VERSION ""

NS_ :

BS_:

BU_: ACCL BGW DBPC DCFL DCFR DCRL DCRR DSM ECPM FBCM FFL FLDC FRDC HLL HLR HUD IHUB LGL PBPC PSM RCLL RCLR RLDC RLSM RRDC RRSM TOOL RCCL RCCR SCAM DEMFL DEMFR DEMRL DEMRR DOSFL DOSFR DOSRL DOSRR

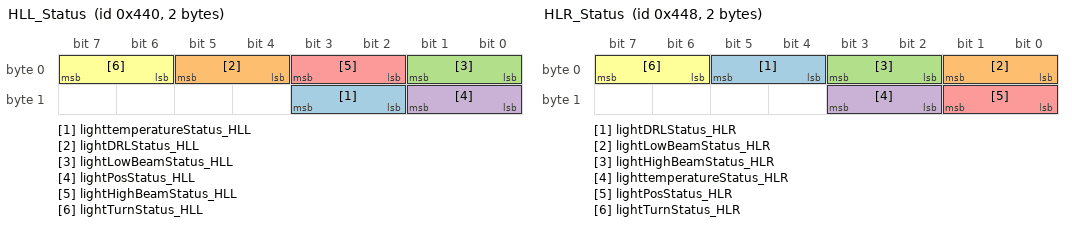
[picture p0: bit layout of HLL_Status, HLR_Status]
BO_ 1088 HLL_Status: 2 HLL
 SG_ lighttemperatureStatus_HLL : 11|2@0+ (1,0) [0|3] ""  FBCM
 SG_ lightDRLStatus_HLL : 5|2@0+ (1,0) [0|3] ""  HUD,BGW,FBCM
 SG_ lightLowBeamStatus_HLL : 1|2@0+ (1,0) [0|3] ""  IHUB,HUD,FBCM,BGW
 SG_ lightPosStatus_HLL : 9|2@0+ (1,0) [0|3] ""  HUD,FBCM,BGW
 SG_ lightHighBeamStatus_HLL : 3|2@0+ (1,0) [0|3] ""  IHUB,HUD,FBCM,BGW
 SG_ lightTurnStatus_HLL : 7|2@0+ (1,0) [0|3] ""  HUD,FBCM,BGW

BO_ 1096 HLR_Status: 2 HLR
 SG_ lightDRLStatus_HLR : 5|2@0+ (1,0) [0|3] ""  HUD,BGW,FBCM
 SG_ lightLowBeamStatus_HLR : 1|2@0+ (1,0) [0|3] ""  IHUB,HUD,FBCM,BGW
 SG_ lightHighBeamStatus_HLR : 3|2@0+ (1,0) [0|3] ""  IHUB,HUD,FBCM,BGW
 SG_ lighttemperatureStatus_HLR : 11|2@0+ (1,0) [0|3] ""  FBCM
 SG_ lightPosStatus_HLR : 9|2@0+ (1,0) [0|3] ""  HUD,FBCM,BGW
 SG_ lightTurnStatus_HLR : 7|2@0+ (1,0) [0|3] ""  HUD,FBCM,BGW

BO_ 680 DCRL_Status: 8 DCRL
 SG_ doorLockReq_DCRL : 55|2@0+ (1,0) [0|2] ""  BGW
 SG_ lockUnlockReq_RLLUS : 41|2@0+ (1,0) [0|2] ""  BGW
 SG_ doorSafeMode_DCRL : 53|2@0+ (1,0) [0|0] ""  FBCM,BGW
 SG_ doorLatchPawlOpen_DCRL : 48|2@0+ (1,0) [0|3] ""  TOOL
 SG_ doorLatchFault_DCRL : 23|2@0+ (1,0) [0|2] ""  BGW
 SG_ childLockButtonState_DCRL : 21|2@0+ (1,0) [0|2] ""  BGW,DCFL,DCFR,DCRL,DCRR
 SG_ doorIsUnlatched_DCRL : 31|2@0+ (1,0) [0|2] ""  HUD,FBCM,BGW,DCFR,DCRR,DCFL,IHUB
 SG_ doorExtSwitch_DCRL : 9|2@0+ (1,0) [0|2] ""  BGW
 SG_ doorMirrorState_DCRL : 7|3@0+ (1,0) [0|6] ""  ECPM,BGW
 SG_ doorState_DCRL : 13|4@0+ (1,0) [0|9] ""  ECPM,FBCM,BGW,DBPC
 SG_ mirrorHeaterState_DCRL : 15|2@0+ (1,0) [0|2] ""  ECPM,BGW
 SG_ sideRepeaterState_DCRL : 2|2@0+ (1,0) [0|2] ""  BGW
 SG_ doorDTCPresent_DCRL : 4|2@0+ (1,0) [0|2] ""  BGW
 SG_ windowStatusRl_DCRL : 19|3@0+ (1,0) [0|6] ""  BGW
 SG_ mirrorFoldFeedbackLeft_DCRL : 29|2@0+ (1,0) [0|2] ""  BGW
 SG_ mirrorDefrostGlassStatusLh_DCRL : 27|2@0+ (1,0) [0|2] ""  BGW
 SG_ mirrorStatusMovUpDownLeft_DCRL : 39|2@0+ (1,0) [0|2] ""  BGW
 SG_ mirrorStatusMovInOutLeft_DCRL : 37|2@0+ (1,0) [0|2] ""  BGW
 SG_ mirrorDefrostCamStatusLeft_DCRL : 35|2@0+ (1,0) [0|2] ""  BGW
 SG_ errorAMPRL_DCRL : 16|1@0+ (1,0) [0|1] ""  BGW
 SG_ errorALDRL_DCRL : 0|1@0+ (1,0) [0|1] ""  BGW
 SG_ doorAngle_DCRL : 47|6@0- (2,40) [-24|100] "degrees"  BGW
 SG_ doorAngleMax_DCRL : 62|7@0+ (1,0) [0|126] "degrees"  BGW
 SG_ wakeUpCause_DCRL : 51|3@0+ (1,0) [0|7] ""  TOOL

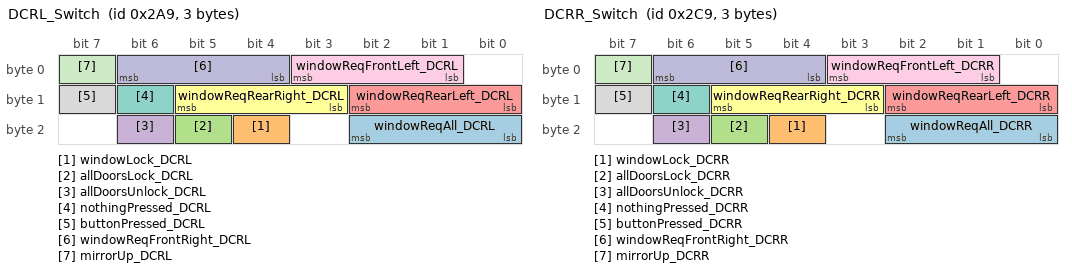
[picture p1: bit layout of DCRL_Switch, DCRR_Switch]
BO_ 681 DCRL_Switch: 3 DCRL
 SG_ windowReqAll_DCRL : 18|3@0+ (1,0) [0|6] ""  DCRR,DCRL,DCFR,DCFL,TOOL
 SG_ windowLock_DCRL : 20|1@0+ (1,0) [0|1] ""  DCRR,DCRL,DCFR,DCFL,TOOL
 SG_ allDoorsLock_DCRL : 21|1@0+ (1,0) [0|1] ""  DCRR,DCRL,DCFR,DCFL,TOOL
 SG_ allDoorsUnlock_DCRL : 22|1@0+ (1,0) [0|1] ""  DCRR,DCRL,DCFR,DCFL,TOOL
 SG_ windowReqRearLeft_DCRL : 10|3@0+ (1,0) [0|6] ""  DCFR,DCRR,DCFL,DCRL,BGW,TOOL
 SG_ windowReqRearRight_DCRL : 13|3@0+ (1,0) [0|6] ""  DCRL,DCFR,DCFL,DCRR,BGW,TOOL
 SG_ nothingPressed_DCRL : 14|1@0+ (1,0) [0|1] ""  DCFR,DCRL,DCRR,DCFL,TOOL
 SG_ buttonPressed_DCRL : 15|1@0+ (1,0) [0|1] ""  DCFR,DCRL,DCRR,DCFL,TOOL
 SG_ windowReqFrontLeft_DCRL : 3|3@0+ (1,0) [0|6] ""  DCFR,DCRL,DCRR,DCFL,BGW
 SG_ windowReqFrontRight_DCRL : 6|3@0+ (1,0) [0|6] ""  DCFR,DCRL,DCRR,DCFL,BGW,TOOL
 SG_ mirrorUp_DCRL : 7|1@0+ (1,0) [0|1] ""  DCRR,DCRL,DCFR,DCFL,TOOL

BO_ 712 DCRR_Status: 8 DCRR
 SG_ doorLockReq_DCRR : 55|2@0+ (1,0) [0|2] ""  BGW
 SG_ lockUnlockReq_RRLUS : 41|2@0+ (1,0) [0|2] ""  BGW
 SG_ doorSafeMode_DCRR : 53|2@0+ (1,0) [0|0] ""  FBCM,BGW
 SG_ doorLatchPawlOpen_DCRR : 48|2@0+ (1,0) [0|3] ""  TOOL
 SG_ doorLatchFault_DCRR : 23|2@0+ (1,0) [0|2] ""  BGW
 SG_ childLockButtonState_DCRR : 21|2@0+ (1,0) [0|2] ""  BGW,DCFL,DCFR,DCRL,DCRR
 SG_ doorIsUnlatched_DCRR : 31|2@0+ (1,0) [0|2] ""  HUD,FBCM,BGW,DCFR,DCFL,DCRL,IHUB
 SG_ doorExtSwitch_DCRR : 9|2@0+ (1,0) [0|2] ""  BGW
 SG_ doorMirrorState_DCRR : 7|3@0+ (1,0) [0|6] ""  ECPM,BGW
 SG_ doorState_DCRR : 13|4@0+ (1,0) [0|9] ""  ECPM,FBCM,BGW,DBPC
 SG_ mirrorHeaterState_DCRR : 15|2@0+ (1,0) [0|2] ""  ECPM,BGW
 SG_ sideRepeaterState_DCRR : 2|2@0+ (1,0) [0|2] ""  BGW
 SG_ doorDTCPresent_DCRR : 4|2@0+ (1,0) [0|2] ""  BGW
 SG_ windowStatusRr_DCRR : 19|3@0+ (1,0) [0|6] ""  BGW
 SG_ mirrorFoldFeedbackRight_DCRR : 29|2@0+ (1,0) [0|2] ""  BGW
 SG_ mirrorDefrostGlassStatusRh_DCRR : 27|2@0+ (1,0) [0|2] ""  BGW
 SG_ mirrorStatusMovUpDownRight_DCRR : 39|2@0+ (1,0) [0|2] ""  BGW
 SG_ mirrorStatusMovInOutRight_DCRR : 37|2@0+ (1,0) [0|2] ""  BGW
 SG_ mirrorDefrostCamStatusRight_DCRR : 35|2@0+ (1,0) [0|2] ""  BGW
 SG_ errorAMPRR_DCRR : 16|1@0+ (1,0) [0|1] ""  BGW
 SG_ errorALDRR_DCRR : 0|1@0+ (1,0) [0|1] ""  BGW
 SG_ doorAngle_DCRR : 47|6@0- (2,40) [-24|100] "degrees"  BGW
 SG_ doorAngleMax_DCRR : 62|7@0+ (1,0) [0|126] "degrees"  BGW
 SG_ wakeUpCause_DCRR : 51|3@0+ (1,0) [0|7] ""  TOOL

BO_ 713 DCRR_Switch: 3 DCRR
 SG_ windowReqAll_DCRR : 18|3@0+ (1,0) [0|6] ""  DCRR,DCRL,DCFR,DCFL,TOOL
 SG_ windowLock_DCRR : 20|1@0+ (1,0) [0|1] ""  DCRR,DCRL,DCFR,DCFL,TOOL
 SG_ allDoorsLock_DCRR : 21|1@0+ (1,0) [0|1] ""  DCRR,DCRL,DCFR,DCFL,TOOL
 SG_ allDoorsUnlock_DCRR : 22|1@0+ (1,0) [0|1] ""  DCRR,DCRL,DCFR,DCFL,TOOL
 SG_ windowReqRearLeft_DCRR : 10|3@0+ (1,0) [0|6] ""  DCFR,DCRR,DCFL,DCRL
 SG_ windowReqRearRight_DCRR : 13|3@0+ (1,0) [0|6] ""  DCRL,DCFR,DCFL,DCRR,BGW
 SG_ nothingPressed_DCRR : 14|1@0+ (1,0) [0|1] ""  DCFR,DCRL,DCRR,DCFL,TOOL
 SG_ buttonPressed_DCRR : 15|1@0+ (1,0) [0|1] ""  DCFR,DCRL,DCRR,DCFL,TOOL
 SG_ windowReqFrontLeft_DCRR : 3|3@0+ (1,0) [0|6] ""  DCFR,DCRL,DCRR,DCFL,BGW
 SG_ windowReqFrontRight_DCRR : 6|3@0+ (1,0) [0|6] ""  DCFR,DCRL,DCRR,DCFL,BGW,TOOL
 SG_ mirrorUp_DCRR : 7|1@0+ (1,0) [0|1] ""  DCRR,DCRL,DCFR,DCFL,TOOL

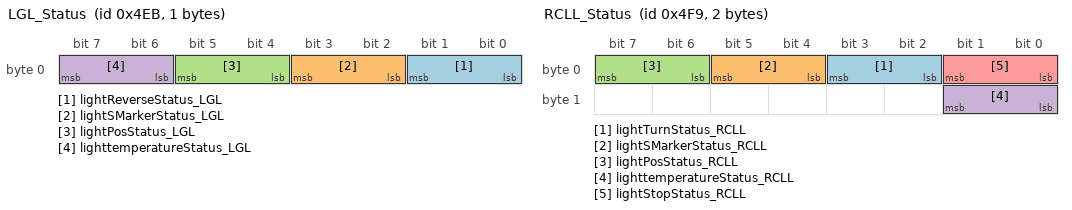
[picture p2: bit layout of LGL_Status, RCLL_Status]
BO_ 1259 LGL_Status: 1 LGL
 SG_ lightReverseStatus_LGL : 1|2@0+ (1,0) [0|3] ""  HUD,BGW,FBCM
 SG_ lightSMarkerStatus_LGL : 3|2@0+ (1,0) [0|3] ""  HUD,BGW,FBCM
 SG_ lightPosStatus_LGL : 5|2@0+ (1,0) [0|3] ""  HUD,BGW,FBCM
 SG_ lighttemperatureStatus_LGL : 7|2@0+ (1,0) [0|3] ""  HUD,BGW,FBCM

BO_ 1273 RCLL_Status: 2 RCLL
 SG_ lightTurnStatus_RCLL : 3|2@0+ (1,0) [0|3] ""  BGW,FBCM
 SG_ lightSMarkerStatus_RCLL : 5|2@0+ (1,0) [0|3] ""  HUD,BGW,FBCM
 SG_ lightPosStatus_RCLL : 7|2@0+ (1,0) [0|3] ""  HUD,BGW,FBCM
 SG_ lighttemperatureStatus_RCLL : 9|2@0+ (1,0) [0|3] ""  FBCM
 SG_ lightStopStatus_RCLL : 1|2@0+ (1,0) [0|2] ""  BGW,FBCM

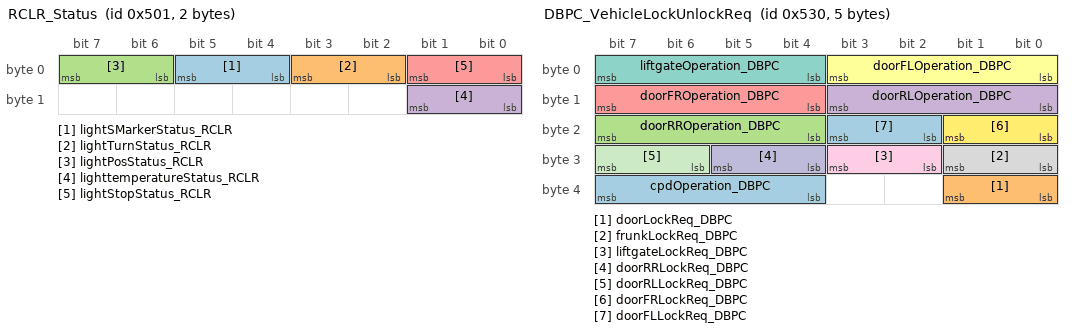
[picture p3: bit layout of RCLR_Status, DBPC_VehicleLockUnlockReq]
BO_ 1281 RCLR_Status: 2 RCLR
 SG_ lightSMarkerStatus_RCLR : 5|2@0+ (1,0) [0|3] ""  BGW
 SG_ lightTurnStatus_RCLR : 3|2@0+ (1,0) [0|3] ""  BGW,FBCM
 SG_ lightPosStatus_RCLR : 7|2@0+ (1,0) [0|3] ""  HUD,BGW,FBCM
 SG_ lighttemperatureStatus_RCLR : 9|2@0+ (1,0) [0|3] ""  FBCM
 SG_ lightStopStatus_RCLR : 1|2@0+ (1,0) [0|3] ""  BGW,FBCM

BO_ 1290 BGW_ClimateMassageCtrl: 8 BGW
 SG_ seatCushionMassageCmdRL_BGW : 34|2@0+ (1,0) [0|0] ""  RLSM
 SG_ seatCushionMassageCmdRR_BGW : 50|2@0+ (1,0) [0|0] ""  RRSM
 SG_ seatBackMassageCmdRR_BGW : 52|2@0+ (1,0) [0|0] ""  RRSM
 SG_ seatBackMassageCmdRL_BGW : 36|2@0+ (1,0) [0|0] ""  RLSM
 SG_ seatCushionMassageCmdFR_BGW : 18|2@0+ (1,0) [0|0] ""  PSM
 SG_ seatBackMassageCmdFR_BGW : 20|2@0+ (1,0) [0|0] ""  PSM
 SG_ seatCushionMassageCmdFL_BGW : 2|2@0+ (1,0) [0|0] ""  DSM
 SG_ seatBackMassageCmdFL_BGW : 4|2@0+ (1,0) [0|0] ""  DSM
 SG_ seatMassageTypeCmdRR_BGW : 63|3@0+ (1,0) [0|0] ""  RRSM
 SG_ seatMassageIntensityCmdRR_BGW : 60|3@0+ (1,0) [0|0] ""  RRSM
 SG_ seatHeatVentCmdRR_BGW : 55|3@0+ (1,0) [0|0] ""  RRSM
 SG_ seatMassageTypeCmdRL_BGW : 47|3@0+ (1,0) [0|0] ""  RLSM
 SG_ seatMassageIntensityCmdRL_BGW : 44|3@0+ (1,0) [0|0] ""  RLSM
 SG_ seatHeatVentCmdRL_BGW : 39|3@0+ (1,0) [0|0] ""  RLSM
 SG_ seatMassageTypeCmdFR_BGW : 31|3@0+ (1,0) [0|0] ""  PSM
 SG_ seatMassageIntensityCmdFR_BGW : 28|3@0+ (1,0) [0|0] ""  PSM
 SG_ seatHeatVentCmdFR_BGW : 23|3@0+ (1,0) [0|0] ""  PSM
 SG_ seatHeatVentCmdFL_BGW : 7|3@0+ (1,0) [0|0] ""  DSM
 SG_ seatMassageIntensityCmdFL_BGW : 12|3@0+ (1,0) [0|0] ""  DSM
 SG_ seatMassageTypeCmdFL_BGW : 15|3@0+ (1,0) [0|0] ""  DSM

BO_ 1298 ACCL_Status: 1 ACCL
 SG_ lightPosStatus_ACCL : 1|2@0+ (1,0) [0|3] ""  FBCM

BO_ 1328 DBPC_VehicleLockUnlockReq: 5 DBPC
 SG_ cpdOperation_DBPC : 39|4@0+ (1,0) [0|0] ""  FBCM,BGW
 SG_ doorLockReq_DBPC : 33|2@0+ (1,0) [0|2] ""  BGW
 SG_ doorRROperation_DBPC : 23|4@0+ (1,0) [0|14] ""  DCFL,DCFR,DCRR,DCRL,FBCM
 SG_ doorRLOperation_DBPC : 11|4@0+ (1,0) [0|14] ""  DCFL,DCFR,DCRR,DCRL,FBCM
 SG_ doorFROperation_DBPC : 15|4@0+ (1,0) [0|14] ""  DCFL,DCFR,DCRR,DCRL,FBCM
 SG_ doorFLOperation_DBPC : 3|4@0+ (1,0) [0|14] ""  DCFL,DCFR,DCRR,DCRL,FBCM
 SG_ liftgateOperation_DBPC : 7|4@0+ (1,0) [0|14] ""  BGW
 SG_ frunkLockReq_DBPC : 25|2@0+ (1,0) [0|2] ""  BGW
 SG_ liftgateLockReq_DBPC : 27|2@0+ (1,0) [0|2] ""  BGW
 SG_ doorRRLockReq_DBPC : 29|2@0+ (1,0) [0|2] ""  BGW
 SG_ doorRLLockReq_DBPC : 31|2@0+ (1,0) [0|2] ""  BGW
 SG_ doorFRLockReq_DBPC : 17|2@0+ (1,0) [0|2] ""  BGW
 SG_ doorFLLockReq_DBPC : 19|2@0+ (1,0) [0|2] ""  BGW

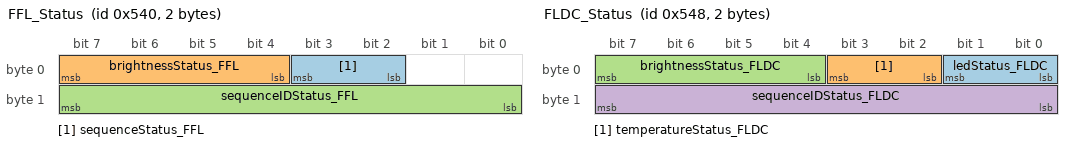
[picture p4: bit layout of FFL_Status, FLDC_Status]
BO_ 1344 FFL_Status: 2 FFL
 SG_ sequenceStatus_FFL : 3|2@0+ (1,0) [0|2] ""  BGW
 SG_ brightnessStatus_FFL : 7|4@0+ (0.07,0) [0|0.98] ""  BGW
 SG_ sequenceIDStatus_FFL : 15|8@0+ (1,0) [0|254] ""  BGW

BO_ 1352 FLDC_Status: 2 FLDC
 SG_ ledStatus_FLDC : 1|2@0+ (1,0) [0|0] ""  BGW
 SG_ temperatureStatus_FLDC : 3|2@0+ (1,0) [0|0] ""  BGW
 SG_ brightnessStatus_FLDC : 7|4@0+ (0.07,0) [0|0.98] ""  BGW
 SG_ sequenceIDStatus_FLDC : 15|8@0+ (1,0) [0|254] ""  BGW

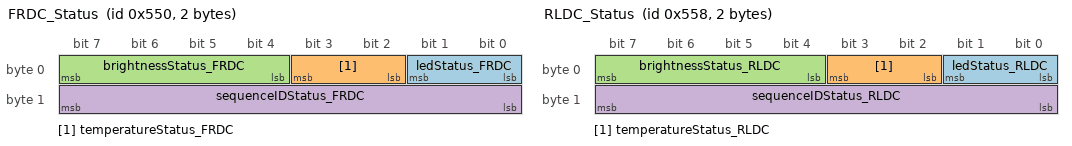
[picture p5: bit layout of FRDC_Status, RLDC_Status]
BO_ 1360 FRDC_Status: 2 FRDC
 SG_ ledStatus_FRDC : 1|2@0+ (1,0) [0|0] ""  BGW
 SG_ temperatureStatus_FRDC : 3|2@0+ (1,0) [0|0] ""  BGW
 SG_ brightnessStatus_FRDC : 7|4@0+ (0.07,0) [0|0.98] ""  BGW
 SG_ sequenceIDStatus_FRDC : 15|8@0+ (1,0) [0|254] ""  BGW

BO_ 1368 RLDC_Status: 2 RLDC
 SG_ ledStatus_RLDC : 1|2@0+ (1,0) [0|0] ""  BGW
 SG_ temperatureStatus_RLDC : 3|2@0+ (1,0) [0|0] ""  BGW
 SG_ brightnessStatus_RLDC : 7|4@0+ (0.07,0) [0|0.98] ""  BGW
 SG_ sequenceIDStatus_RLDC : 15|8@0+ (1,0) [0|254] ""  BGW

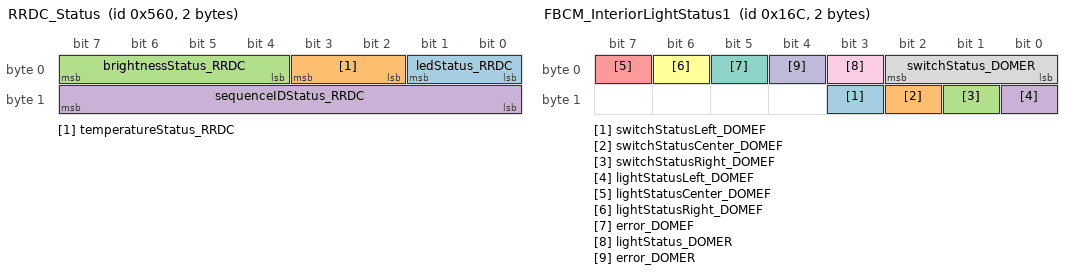
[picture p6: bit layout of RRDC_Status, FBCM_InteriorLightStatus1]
BO_ 1376 RRDC_Status: 2 RRDC
 SG_ ledStatus_RRDC : 1|2@0+ (1,0) [0|0] ""  BGW
 SG_ temperatureStatus_RRDC : 3|2@0+ (1,0) [0|0] ""  BGW
 SG_ brightnessStatus_RRDC : 7|4@0+ (0.07,0) [0|0.98] ""  BGW
 SG_ sequenceIDStatus_RRDC : 15|8@0+ (1,0) [0|254] ""  BGW

BO_ 364 FBCM_InteriorLightStatus1: 2 FBCM
 SG_ switchStatusLeft_DOMEF : 11|1@0+ (1,0) [0|1] ""  BGW
 SG_ switchStatusCenter_DOMEF : 10|1@0+ (1,0) [0|1] ""  BGW
 SG_ switchStatusRight_DOMEF : 9|1@0+ (1,0) [0|1] ""  BGW
 SG_ lightStatusLeft_DOMEF : 8|1@0+ (1,0) [0|1] ""  BGW
 SG_ lightStatusCenter_DOMEF : 7|1@0+ (1,0) [0|1] ""  BGW
 SG_ lightStatusRight_DOMEF : 6|1@0+ (1,0) [0|1] ""  BGW
 SG_ error_DOMEF : 5|1@0+ (1,0) [0|1] ""  BGW
 SG_ switchStatus_DOMER : 2|3@0+ (1,0) [0|6] ""  BGW
 SG_ lightStatus_DOMER : 3|1@0+ (1,0) [0|1] ""  BGW
 SG_ error_DOMER : 4|1@0+ (1,0) [0|1] ""  BGW

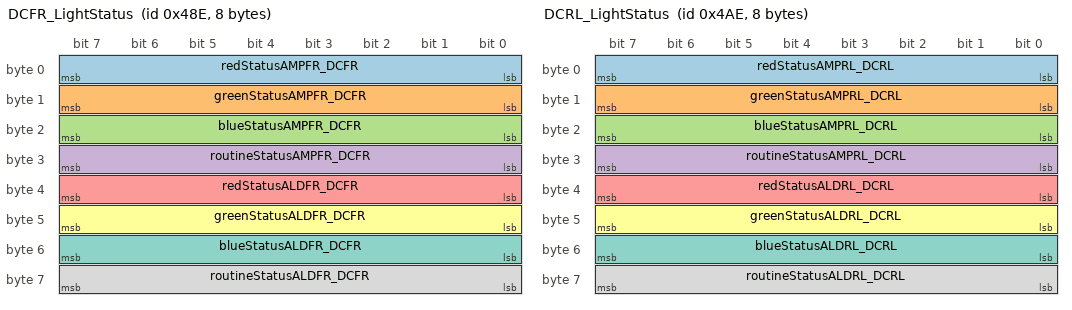
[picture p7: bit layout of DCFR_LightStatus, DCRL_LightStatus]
BO_ 1166 DCFR_LightStatus: 8 DCFR
 SG_ redStatusAMPFR_DCFR : 7|8@0+ (1,0) [0|254] ""  BGW
 SG_ greenStatusAMPFR_DCFR : 15|8@0+ (1,0) [0|254] ""  BGW
 SG_ blueStatusAMPFR_DCFR : 23|8@0+ (1,0) [0|254] ""  BGW
 SG_ routineStatusAMPFR_DCFR : 31|8@0+ (1,0) [0|254] ""  BGW
 SG_ redStatusALDFR_DCFR : 39|8@0+ (1,0) [0|254] ""  BGW
 SG_ greenStatusALDFR_DCFR : 47|8@0+ (1,0) [0|254] ""  BGW
 SG_ blueStatusALDFR_DCFR : 55|8@0+ (1,0) [0|254] ""  BGW
 SG_ routineStatusALDFR_DCFR : 63|8@0+ (1,0) [0|254] ""  BGW

BO_ 1198 DCRL_LightStatus: 8 DCRL
 SG_ redStatusAMPRL_DCRL : 7|8@0+ (1,0) [0|254] ""  BGW
 SG_ greenStatusAMPRL_DCRL : 15|8@0+ (1,0) [0|254] ""  BGW
 SG_ blueStatusAMPRL_DCRL : 23|8@0+ (1,0) [0|254] ""  BGW
 SG_ routineStatusAMPRL_DCRL : 31|8@0+ (1,0) [0|254] ""  BGW
 SG_ redStatusALDRL_DCRL : 39|8@0+ (1,0) [0|254] ""  BGW
 SG_ greenStatusALDRL_DCRL : 47|8@0+ (1,0) [0|254] ""  BGW
 SG_ blueStatusALDRL_DCRL : 55|8@0+ (1,0) [0|254] ""  BGW
 SG_ routineStatusALDRL_DCRL : 63|8@0+ (1,0) [0|254] ""  BGW

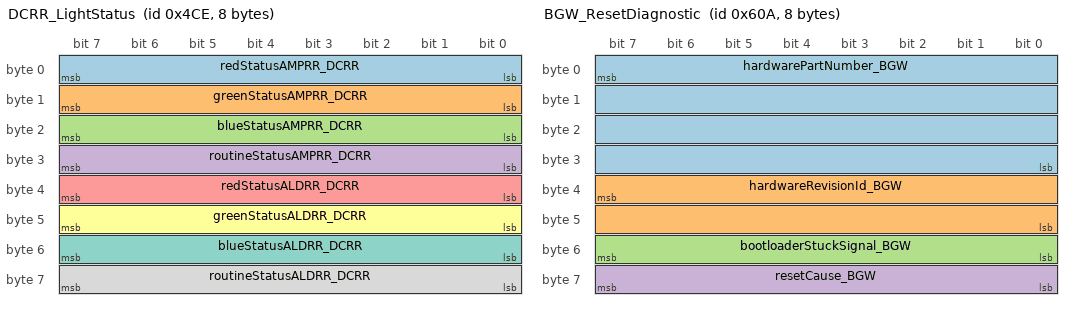
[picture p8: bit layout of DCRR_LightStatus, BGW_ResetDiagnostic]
BO_ 1230 DCRR_LightStatus: 8 DCRR
 SG_ redStatusAMPRR_DCRR : 7|8@0+ (1,0) [0|254] ""  BGW
 SG_ greenStatusAMPRR_DCRR : 15|8@0+ (1,0) [0|254] ""  BGW
 SG_ blueStatusAMPRR_DCRR : 23|8@0+ (1,0) [0|254] ""  BGW
 SG_ routineStatusAMPRR_DCRR : 31|8@0+ (1,0) [0|254] ""  BGW
 SG_ redStatusALDRR_DCRR : 39|8@0+ (1,0) [0|254] ""  BGW
 SG_ greenStatusALDRR_DCRR : 47|8@0+ (1,0) [0|254] ""  BGW
 SG_ blueStatusALDRR_DCRR : 55|8@0+ (1,0) [0|254] ""  BGW
 SG_ routineStatusALDRR_DCRR : 63|8@0+ (1,0) [0|254] ""  BGW

BO_ 1546 BGW_ResetDiagnostic: 8 BGW
 SG_ hardwarePartNumber_BGW : 7|32@0+ (1,0) [0|4294967294] ""  TOOL
 SG_ hardwareRevisionId_BGW : 39|16@0+ (1,0) [0|65534] ""  TOOL
 SG_ bootloaderStuckSignal_BGW : 55|8@0+ (1,0) [0|254] ""  TOOL
 SG_ resetCause_BGW : 63|8@0+ (1,0) [0|254] ""  TOOL

BO_ 1549 BGW_UDSRequest: 8 TOOL

BO_ 1550 BGW_UDSResponse: 8 BGW

BO_ 1551 BGW_Version: 8 BGW
 SG_ componentNum_BGW M : 7|8@0+ (1,0) [0|2] ""  TOOL
 SG_ idGitHashUpper_BGW m2 : 55|16@0+ (1,0) [0|65535] ""  TOOL
 SG_ idBuildMachine_BGW m2 : 47|8@0+ (1,0) [0|254] ""  TOOL
 SG_ versionSubMinor_BGW m2 : 39|8@0+ (1,0) [0|254] ""  TOOL
 SG_ versionReleaseCandidate_BGW m2 : 31|8@0+ (1,0) [0|254] ""  TOOL
 SG_ versionMinor_BGW m2 : 23|8@0+ (1,0) [0|254] ""  TOOL
 SG_ versionMajor_BGW m2 : 15|8@0+ (1,0) [0|254] ""  TOOL
 SG_ idBootGitHashUpper_BGW m0 : 55|16@0+ (1,0) [0|65535] ""  TOOL
 SG_ idBootBuildMachine_BGW m0 : 47|8@0+ (1,0) [0|254] ""  TOOL
 SG_ versionBootSubMinor_BGW m0 : 39|8@0+ (1,0) [0|254] ""  TOOL
 SG_ versionBootReleaseCandidate_BGW m0 : 31|8@0+ (1,0) [0|254] ""  TOOL
 SG_ versionBootMinor_BGW m0 : 23|8@0+ (1,0) [0|254] ""  TOOL
 SG_ versionBootMajor_BGW m0 : 15|8@0+ (1,0) [0|254] ""  TOOL
 SG_ versionCalSubMinor_BGW m1 : 39|8@0+ (1,0) [0|254] ""  TOOL
 SG_ versionCalReleaseCandidate_BGW m1 : 31|8@0+ (1,0) [0|254] ""  TOOL
 SG_ versionCalMinor_BGW m1 : 23|8@0+ (1,0) [0|254] ""  TOOL
 SG_ versionCalMajor_BGW m1 : 15|8@0+ (1,0) [0|254] ""  TOOL
 SG_ idCalGitHashUpper_BGW m1 : 55|16@0+ (1,0) [0|65534] ""  TOOL
 SG_ idCalBuildMachine_BGW m1 : 47|8@0+ (1,0) [0|254] ""  TOOL

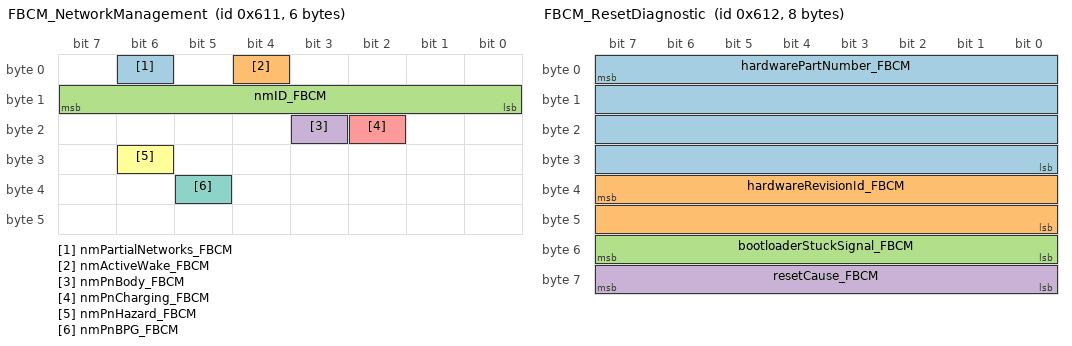
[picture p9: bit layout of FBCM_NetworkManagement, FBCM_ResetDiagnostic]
BO_ 1553 FBCM_NetworkManagement: 6 FBCM
 SG_ nmPartialNetworks_FBCM : 6|1@0+ (1,0) [0|1] ""  BGW,DCFL,DCFR,DCRL,DCRR
 SG_ nmActiveWake_FBCM : 4|1@0+ (1,0) [0|1] ""  BGW,DCFL,DCFR,DCRL,DCRR
 SG_ nmID_FBCM : 15|8@0+ (1,0) [0|31] ""  BGW,DCFL,DCFR,DCRL,DCRR
 SG_ nmPnBody_FBCM : 19|1@0+ (1,0) [0|1] ""  BGW,DCFL,DCFR,DCRL,DCRR
 SG_ nmPnCharging_FBCM : 18|1@0+ (1,0) [0|1] ""  BGW
 SG_ nmPnHazard_FBCM : 30|1@0+ (1,0) [0|1] ""  BGW,DCFL,DCFR
 SG_ nmPnBPG_FBCM : 37|1@0+ (1,0) [0|1] ""  BGW

BO_ 1554 FBCM_ResetDiagnostic: 8 FBCM
 SG_ hardwarePartNumber_FBCM : 7|32@0+ (1,0) [0|4294967294] ""  TOOL
 SG_ hardwareRevisionId_FBCM : 39|16@0+ (1,0) [0|65534] ""  TOOL
 SG_ bootloaderStuckSignal_FBCM : 55|8@0+ (1,0) [0|254] ""  TOOL
 SG_ resetCause_FBCM : 63|8@0+ (1,0) [0|254] ""  BGW,TOOL

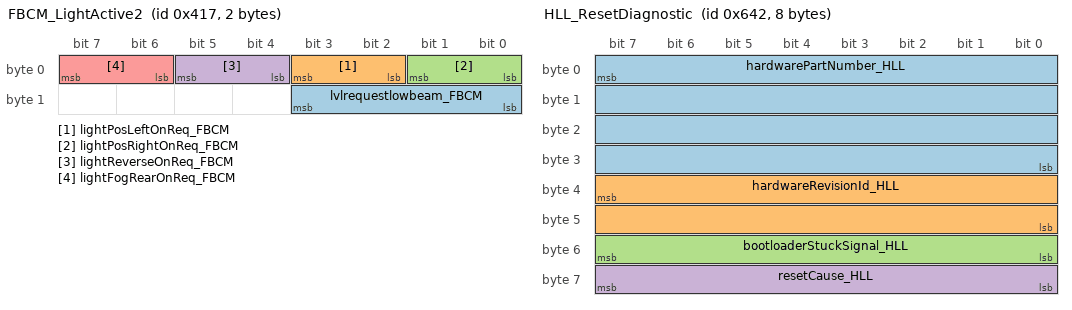
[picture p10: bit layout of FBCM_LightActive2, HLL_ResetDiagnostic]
BO_ 1047 FBCM_LightActive2: 2 FBCM
 SG_ lvlrequestlowbeam_FBCM : 11|4@0+ (1,0) [0|15] ""  HLR,HLL
 SG_ lightPosLeftOnReq_FBCM : 3|2@0+ (1,0) [0|2] ""  ACCL,RCCL,HLL,LGL
 SG_ lightPosRightOnReq_FBCM : 1|2@0+ (1,0) [0|2] ""  ACCL,RCCR,HLR,LGL
 SG_ lightReverseOnReq_FBCM : 5|2@0+ (1,0) [0|2] ""  BGW,IHUB,HUD,RCLL,RCLR
 SG_ lightFogRearOnReq_FBCM : 7|2@0+ (1,0) [0|2] ""  BGW,IHUB,HUD,RCLL,RCLR

BO_ 1557 FBCM_UDSRequest: 8 TOOL
 SG_ udsClientDataFBCM_TOOL : 7|64@0+ (1,0) [0|1.84467440737094E+019] ""  FBCM

BO_ 1558 FBCM_UDSResponse: 8 FBCM
 SG_ udsServerData_FBCM : 7|64@0+ (1,0) [0|1.84467440737094E+019] ""  TOOL

BO_ 1559 FBCM_Version: 8 FBCM
 SG_ versionCalSubMinor_FBCM m1 : 39|8@0+ (1,0) [0|254] ""  BGW,TOOL
 SG_ versionCalReleaseCandidate_FBCM m1 : 31|8@0+ (1,0) [0|254] ""  BGW,TOOL
 SG_ versionCalMinor_FBCM m1 : 23|8@0+ (1,0) [0|254] ""  BGW,TOOL
 SG_ versionCalMajor_FBCM m1 : 15|8@0+ (1,0) [0|254] ""  BGW,TOOL
 SG_ idCalGitHashUpper_FBCM m1 : 55|16@0+ (1,0) [0|65534] ""  BGW,TOOL
 SG_ idCalBuildMachine_FBCM m1 : 47|8@0+ (1,0) [0|254] ""  BGW,TOOL
 SG_ versionReleaseCandidate_FBCM m2 : 31|8@0+ (1,0) [0|254] ""  BGW,TOOL
 SG_ versionBootReleaseCandidate_FBCM m0 : 31|8@0+ (1,0) [0|254] ""  BGW,TOOL
 SG_ componentNum_FBCM M : 7|8@0+ (1,0) [0|254] ""  BGW,TOOL
 SG_ idGitHashUpper_FBCM m2 : 55|16@0+ (1,0) [0|65534] ""  BGW,TOOL
 SG_ idBootGitHashUpper_FBCM m0 : 55|16@0+ (1,0) [0|65534] ""  BGW,TOOL
 SG_ idBuildMachine_FBCM m2 : 47|8@0+ (1,0) [0|254] ""  BGW,TOOL
 SG_ versionSubMinor_FBCM m2 : 39|8@0+ (1,0) [0|254] ""  BGW,TOOL
 SG_ versionMinor_FBCM m2 : 23|8@0+ (1,0) [0|254] ""  BGW,TOOL
 SG_ versionMajor_FBCM m2 : 15|8@0+ (1,0) [0|254] ""  BGW,TOOL
 SG_ idBootBuildMachine_FBCM m0 : 47|8@0+ (1,0) [0|254] ""  BGW,TOOL
 SG_ versionBootSubMinor_FBCM m0 : 39|8@0+ (1,0) [0|254] ""  BGW,TOOL
 SG_ versionBootMinor_FBCM m0 : 23|8@0+ (1,0) [0|254] ""  BGW,TOOL
 SG_ versionBootMajor_FBCM m0 : 15|8@0+ (1,0) [0|254] ""  BGW,TOOL

BO_ 1602 HLL_ResetDiagnostic: 8 HLL
 SG_ hardwarePartNumber_HLL : 7|32@0+ (1,0) [0|4294967294] ""  TOOL
 SG_ hardwareRevisionId_HLL : 39|16@0+ (1,0) [0|65534] ""  TOOL
 SG_ bootloaderStuckSignal_HLL : 55|8@0+ (1,0) [0|254] ""  TOOL
 SG_ resetCause_HLL : 63|8@0+ (1,0) [0|254] ""  TOOL

BO_ 1605 HLL_UDSRequest: 8 TOOL
 SG_ udsClientDataHLL_TOOL : 7|64@0+ (1,0) [0|1.84467440737094E+019] ""  HLL

BO_ 1606 HLL_UDSResponse: 8 HLL
 SG_ udsServerData_HLL : 7|64@0+ (1,0) [0|1.84467440737094E+019] ""  TOOL

BO_ 1607 HLL_Version: 8 HLL
 SG_ versionReleaseCandidate_HLL m1 : 31|8@0+ (1,0) [0|254] ""  BGW,TOOL
 SG_ versionBootReleaseCandidate_HLL m0 : 31|8@0+ (1,0) [0|254] ""  BGW,TOOL
 SG_ componentNum_HLL M : 7|8@0+ (1,0) [0|254] ""  BGW,TOOL
 SG_ idGitHashUpper_HLL m1 : 55|16@0+ (1,0) [0|65534] ""  BGW,TOOL
 SG_ idBootGitHashUpper_HLL m0 : 55|16@0+ (1,0) [0|65534] ""  BGW,TOOL
 SG_ idBuildMachine_HLL m1 : 47|8@0+ (1,0) [0|254] ""  BGW,TOOL
 SG_ versionSubMinor_HLL m1 : 39|8@0+ (1,0) [0|254] ""  BGW,TOOL
 SG_ versionMinor_HLL m1 : 23|8@0+ (1,0) [0|254] ""  BGW,TOOL
 SG_ versionMajor_HLL m1 : 15|8@0+ (1,0) [0|254] ""  BGW,TOOL
 SG_ idBootBuildMachine_HLL m0 : 47|8@0+ (1,0) [0|254] ""  BGW,TOOL
 SG_ versionBootSubMinor_HLL m0 : 39|8@0+ (1,0) [0|254] ""  BGW,TOOL
 SG_ versionBootMinor_HLL m0 : 23|8@0+ (1,0) [0|254] ""  BGW,TOOL
 SG_ versionBootMajor_HLL m0 : 15|8@0+ (1,0) [0|254] ""  BGW,TOOL

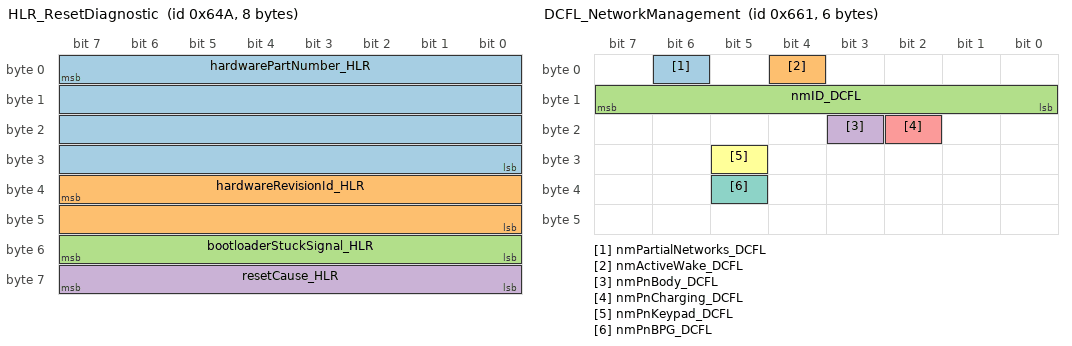
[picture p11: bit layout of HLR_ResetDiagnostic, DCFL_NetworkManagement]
BO_ 1610 HLR_ResetDiagnostic: 8 HLR
 SG_ hardwarePartNumber_HLR : 7|32@0+ (1,0) [0|4294967294] ""  TOOL
 SG_ hardwareRevisionId_HLR : 39|16@0+ (1,0) [0|65534] ""  TOOL
 SG_ bootloaderStuckSignal_HLR : 55|8@0+ (1,0) [0|254] ""  TOOL
 SG_ resetCause_HLR : 63|8@0+ (1,0) [0|254] ""  TOOL

BO_ 1613 HLR_UDSRequest: 8 TOOL
 SG_ udsClientDataHLR_TOOL : 7|64@0+ (1,0) [0|1.84467440737094E+019] ""  HLR

BO_ 1614 HLR_UDSResponse: 8 HLR
 SG_ udsServerData_HLR : 7|64@0+ (1,0) [0|1.84467440737094E+019] ""  TOOL

BO_ 1615 HLR_Version: 8 HLR
 SG_ versionReleaseCandidate_HLR m1 : 31|8@0+ (1,0) [0|254] ""  BGW,TOOL
 SG_ versionBootReleaseCandidate_HLR m0 : 31|8@0+ (1,0) [0|254] ""  BGW,TOOL
 SG_ componentNum_HLR M : 7|8@0+ (1,0) [0|254] ""  BGW,TOOL
 SG_ idGitHashUpper_HLR m1 : 55|16@0+ (1,0) [0|65534] ""  BGW,TOOL
 SG_ idBootGitHashUpper_HLR m0 : 55|16@0+ (1,0) [0|65534] ""  BGW,TOOL
 SG_ idBuildMachine_HLR m1 : 47|8@0+ (1,0) [0|254] ""  BGW,TOOL
 SG_ versionSubMinor_HLR m1 : 39|8@0+ (1,0) [0|254] ""  BGW,TOOL
 SG_ versionMinor_HLR m1 : 23|8@0+ (1,0) [0|254] ""  BGW,TOOL
 SG_ versionMajor_HLR m1 : 15|8@0+ (1,0) [0|254] ""  BGW,TOOL
 SG_ idBootBuildMachine_HLR m0 : 47|8@0+ (1,0) [0|254] ""  BGW,TOOL
 SG_ versionBootSubMinor_HLR m0 : 39|8@0+ (1,0) [0|254] ""  BGW,TOOL
 SG_ versionBootMinor_HLR m0 : 23|8@0+ (1,0) [0|254] ""  BGW,TOOL
 SG_ versionBootMajor_HLR m0 : 15|8@0+ (1,0) [0|254] ""  BGW,TOOL

BO_ 1633 DCFL_NetworkManagement: 6 DCFL
 SG_ nmPartialNetworks_DCFL : 6|1@0+ (1,0) [0|1] ""  BGW,DCFR,DCRL,DCRR,FBCM
 SG_ nmActiveWake_DCFL : 4|1@0+ (1,0) [0|1] ""  BGW,DCFR,DCRL,DCRR,FBCM
 SG_ nmID_DCFL : 15|8@0+ (1,0) [0|31] ""  BGW,DCFR,DCRL,DCRR,FBCM
 SG_ nmPnBody_DCFL : 19|1@0+ (1,0) [0|1] ""  BGW,DCFR,DCRL,DCRR,FBCM
 SG_ nmPnCharging_DCFL : 18|1@0+ (1,0) [0|1] ""  BGW
 SG_ nmPnKeypad_DCFL : 29|1@0+ (1,0) [0|1] ""  BGW
 SG_ nmPnBPG_DCFL : 37|1@0+ (1,0) [0|1] ""  BGW

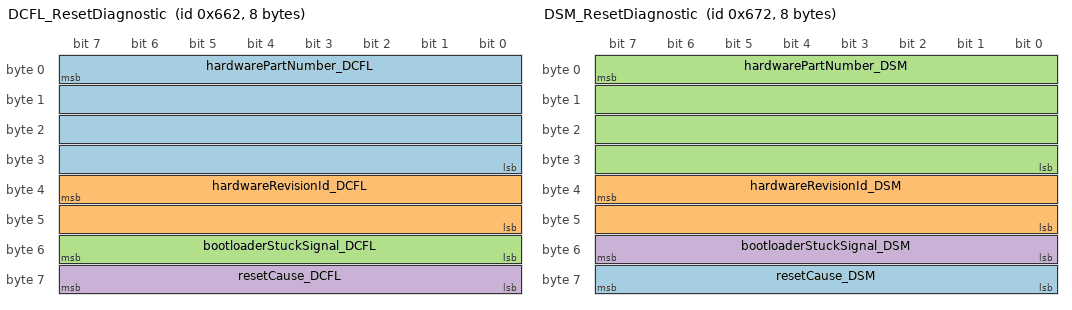
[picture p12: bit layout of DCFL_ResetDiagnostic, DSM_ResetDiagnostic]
BO_ 1634 DCFL_ResetDiagnostic: 8 DCFL
 SG_ hardwarePartNumber_DCFL : 7|32@0+ (1,0) [0|4294967294] ""  TOOL
 SG_ hardwareRevisionId_DCFL : 39|16@0+ (1,0) [0|65534] ""  TOOL
 SG_ bootloaderStuckSignal_DCFL : 55|8@0+ (1,0) [0|254] ""  TOOL
 SG_ resetCause_DCFL : 63|8@0+ (1,0) [0|254] ""  BGW,TOOL

BO_ 1637 DCFL_UDSRequest: 8 TOOL
 SG_ udsClientDataDcfl_TOOL : 7|64@0+ (1,0) [0|1.84467440737094E+019] ""  DCFL

BO_ 1638 DCFL_UDSResponse: 8 DCFL
 SG_ udsServerData_DCFL : 7|64@0+ (1,0) [0|1.84467440737094E+019] ""  TOOL

BO_ 1639 DCFL_Version: 8 DCFL
 SG_ versionCalSubMinor_DCFL m1 : 39|8@0+ (1,0) [0|254] ""  BGW,TOOL
 SG_ versionCalReleaseCandidate_DCFL m1 : 31|8@0+ (1,0) [0|254] ""  BGW,TOOL
 SG_ versionCalMinor_DCFL m1 : 23|8@0+ (1,0) [0|254] ""  BGW,TOOL
 SG_ versionCalMajor_DCFL m1 : 15|8@0+ (1,0) [0|254] ""  BGW,TOOL
 SG_ idCalBuildMachine_DCFL m1 : 47|8@0+ (1,0) [0|254] ""  BGW,TOOL
 SG_ idCalGitHashUpper_DCFL m1 : 55|16@0+ (1,0) [0|65534] ""  BGW,TOOL
 SG_ versionReleaseCandidate_DCFL m2 : 31|8@0+ (1,0) [0|254] ""  BGW,TOOL
 SG_ versionBootReleaseCandidate_DCFL m0 : 31|8@0+ (1,0) [0|254] ""  BGW,TOOL
 SG_ componentNum_DCFL M : 7|8@0+ (1,0) [0|3] ""  BGW,TOOL
 SG_ idGitHashUpper_DCFL m2 : 55|16@0+ (1,0) [0|65534] ""  BGW,TOOL
 SG_ idBootGitHashUpper_DCFL m0 : 55|16@0+ (1,0) [0|65534] ""  BGW,TOOL
 SG_ idBuildMachine_DCFL m2 : 47|8@0+ (1,0) [0|254] ""  BGW,TOOL
 SG_ versionSubMinor_DCFL m2 : 39|8@0+ (1,0) [0|254] ""  BGW,TOOL
 SG_ versionMinor_DCFL m2 : 23|8@0+ (1,0) [0|254] ""  BGW,TOOL
 SG_ versionMajor_DCFL m2 : 15|8@0+ (1,0) [0|254] ""  BGW,TOOL
 SG_ idBootBuildMachine_DCFL m0 : 47|8@0+ (1,0) [0|254] ""  BGW,TOOL
 SG_ versionBootSubMinor_DCFL m0 : 39|8@0+ (1,0) [0|254] ""  BGW,TOOL
 SG_ versionBootMinor_DCFL m0 : 23|8@0+ (1,0) [0|254] ""  BGW,TOOL
 SG_ versionBootMajor_DCFL m0 : 15|8@0+ (1,0) [0|254] ""  BGW,TOOL

BO_ 1650 DSM_ResetDiagnostic: 8 DSM
 SG_ resetCause_DSM : 63|8@0+ (1,0) [0|254] ""  TOOL
 SG_ hardwareRevisionId_DSM : 39|16@0+ (1,0) [0|65534] ""  TOOL
 SG_ hardwarePartNumber_DSM : 7|32@0+ (1,0) [0|4294967294] ""  TOOL
 SG_ bootloaderStuckSignal_DSM : 55|8@0+ (1,0) [0|254] ""  TOOL

BO_ 1653 DSM_UDSRequest: 8 TOOL
 SG_ udsClientDataDSM_TOOL : 7|64@0+ (1,0) [0|1.84467440737094E+019] ""  DSM

BO_ 1654 DSM_UDSResponse: 8 DSM
 SG_ udsServerData_DSM : 7|64@0+ (1,0) [0|1.84467440737094E+019] ""  TOOL

BO_ 1655 DSM_Version: 8 DSM
 SG_ versionReleaseCandidate_DSM m1 : 31|8@0+ (1,0) [0|254] ""  BGW,TOOL
 SG_ versionBootReleaseCandidate_DSM m0 : 31|8@0+ (1,0) [0|254] ""  BGW,TOOL
 SG_ componentNum_DSM M : 7|8@0+ (1,0) [0|254] ""  BGW,TOOL
 SG_ idGitHashUpper_DSM m1 : 55|16@0+ (1,0) [0|65534] ""  BGW,TOOL
 SG_ idBootGitHashUpper_DSM m0 : 55|16@0+ (1,0) [0|65534] ""  BGW,TOOL
 SG_ idBuildMachine_DSM m1 : 47|8@0+ (1,0) [0|254] ""  BGW,TOOL
 SG_ versionSubMinor_DSM m1 : 39|8@0+ (1,0) [0|254] ""  BGW,TOOL
 SG_ versionMinor_DSM m1 : 23|8@0+ (1,0) [0|254] ""  BGW,TOOL
 SG_ versionMajor_DSM m1 : 15|8@0+ (1,0) [0|254] ""  BGW,TOOL
 SG_ idBootBuildMachine_DSM m0 : 47|8@0+ (1,0) [0|254] ""  BGW,TOOL
 SG_ versionBootSubMinor_DSM m0 : 39|8@0+ (1,0) [0|254] ""  BGW,TOOL
 SG_ versionBootMinor_DSM m0 : 23|8@0+ (1,0) [0|254] ""  BGW,TOOL
 SG_ versionBootMajor_DSM m0 : 15|8@0+ (1,0) [0|254] ""  BGW,TOOL

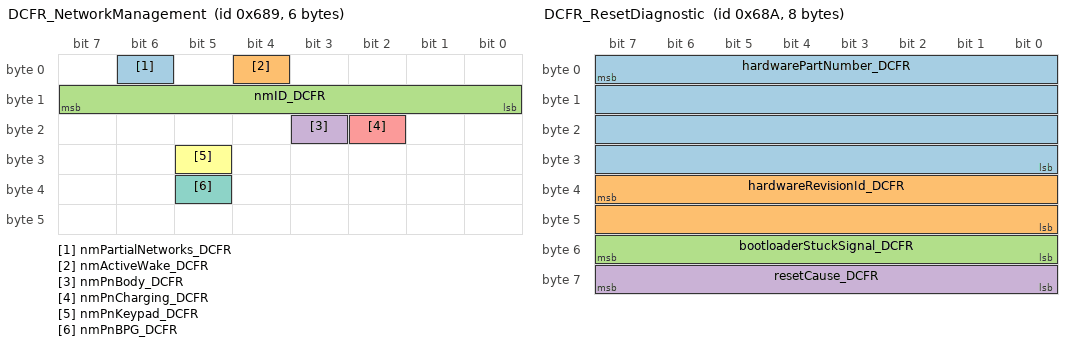
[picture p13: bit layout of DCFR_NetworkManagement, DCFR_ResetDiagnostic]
BO_ 1673 DCFR_NetworkManagement: 6 DCFR
 SG_ nmPartialNetworks_DCFR : 6|1@0+ (1,0) [0|1] ""  BGW,DCRL,DCRR,FBCM
 SG_ nmActiveWake_DCFR : 4|1@0+ (1,0) [0|1] ""  BGW,DCRL,DCRR,FBCM
 SG_ nmID_DCFR : 15|8@0+ (1,0) [0|31] ""  BGW,DCRL,DCRR,FBCM
 SG_ nmPnBody_DCFR : 19|1@0+ (1,0) [0|1] ""  BGW,DCRL,DCRR,FBCM
 SG_ nmPnCharging_DCFR : 18|1@0+ (1,0) [0|1] ""  BGW
 SG_ nmPnKeypad_DCFR : 29|1@0+ (1,0) [0|1] ""  BGW
 SG_ nmPnBPG_DCFR : 37|1@0+ (1,0) [0|1] ""  BGW

BO_ 1674 DCFR_ResetDiagnostic: 8 DCFR
 SG_ hardwarePartNumber_DCFR : 7|32@0+ (1,0) [0|4294967294] ""  TOOL
 SG_ hardwareRevisionId_DCFR : 39|16@0+ (1,0) [0|65534] ""  TOOL
 SG_ bootloaderStuckSignal_DCFR : 55|8@0+ (1,0) [0|254] ""  TOOL
 SG_ resetCause_DCFR : 63|8@0+ (1,0) [0|254] ""  BGW,TOOL

BO_ 1677 DCFR_UDSRequest: 8 TOOL
 SG_ udsClientDataDcfr_TOOL : 7|64@0+ (1,0) [0|1.84467440737094E+019] ""  DCFR

BO_ 1678 DCFR_UDSResponse: 8 DCFR
 SG_ udsServerData_DCFR : 7|64@0+ (1,0) [0|1.84467440737094E+019] ""  TOOL

BO_ 1679 DCFR_Version: 8 DCFR
 SG_ versionCalSubMinor_DCFR m1 : 39|8@0+ (1,0) [0|254] ""  BGW,TOOL
 SG_ versionCalReleaseCandidate_DCFR m1 : 31|8@0+ (1,0) [0|254] ""  BGW,TOOL
 SG_ versionCalMinor_DCFR m1 : 23|8@0+ (1,0) [0|254] ""  BGW,TOOL
 SG_ versionCalMajor_DCFR m1 : 15|8@0+ (1,0) [0|254] ""  BGW,TOOL
 SG_ idCalBuildMachine_DCFR m1 : 47|8@0+ (1,0) [0|254] ""  BGW,TOOL
 SG_ idCalGitHashUpper_DCFR m1 : 55|16@0+ (1,0) [0|65534] ""  BGW,TOOL
 SG_ versionReleaseCandidate_DCFR m2 : 31|8@0+ (1,0) [0|254] ""  BGW,TOOL
 SG_ versionBootReleaseCandidate_DCFR m0 : 31|8@0+ (1,0) [0|254] ""  BGW,TOOL
 SG_ componentNum_DCFR M : 7|8@0+ (1,0) [0|254] ""  BGW,TOOL
 SG_ idGitHashUpper_DCFR m2 : 55|16@0+ (1,0) [0|65534] ""  BGW,TOOL
 SG_ idBootGitHashUpper_DCFR m0 : 55|16@0+ (1,0) [0|65534] ""  BGW,TOOL
 SG_ idBuildMachine_DCFR m2 : 47|8@0+ (1,0) [0|254] ""  BGW,TOOL
 SG_ versionSubMinor_DCFR m2 : 39|8@0+ (1,0) [0|254] ""  BGW,TOOL
 SG_ versionMinor_DCFR m2 : 23|8@0+ (1,0) [0|254] ""  BGW,TOOL
 SG_ versionMajor_DCFR m2 : 15|8@0+ (1,0) [0|254] ""  BGW,TOOL
 SG_ idBootBuildMachine_DCFR m0 : 47|8@0+ (1,0) [0|254] ""  BGW,TOOL
 SG_ versionBootSubMinor_DCFR m0 : 39|8@0+ (1,0) [0|254] ""  BGW,TOOL
 SG_ versionBootMinor_DCFR m0 : 23|8@0+ (1,0) [0|254] ""  BGW,TOOL
 SG_ versionBootMajor_DCFR m0 : 15|8@0+ (1,0) [0|254] ""  BGW,TOOL

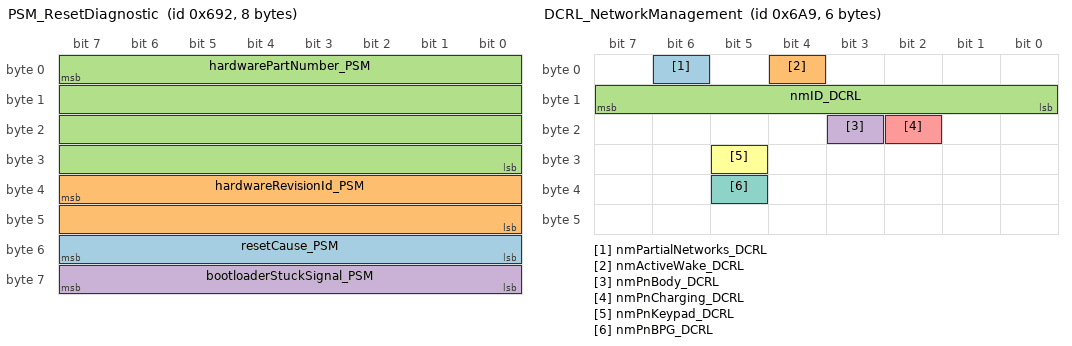
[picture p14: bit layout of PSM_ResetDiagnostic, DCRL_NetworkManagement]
BO_ 1682 PSM_ResetDiagnostic: 8 PSM
 SG_ resetCause_PSM : 55|8@0+ (1,0) [0|254] ""  TOOL
 SG_ hardwareRevisionId_PSM : 39|16@0+ (1,0) [0|65534] ""  TOOL
 SG_ hardwarePartNumber_PSM : 7|32@0+ (1,0) [0|4294967294] ""  TOOL
 SG_ bootloaderStuckSignal_PSM : 63|8@0+ (1,0) [0|254] ""  TOOL

BO_ 1685 PSM_UDSRequest: 8 TOOL
 SG_ udsClientDataPSM_TOOL : 7|64@0+ (1,0) [0|1.84467440737094E+019] ""  PSM

BO_ 1686 PSM_UDSResponse: 8 PSM
 SG_ udsServerData_PSM : 7|64@0+ (1,0) [0|1.84467440737094E+019] ""  TOOL

BO_ 1687 PSM_Version: 8 PSM
 SG_ versionReleaseCandidate_PSM m1 : 31|8@0+ (1,0) [0|254] ""  BGW,TOOL
 SG_ versionBootReleaseCandidate_PSM m0 : 31|8@0+ (1,0) [0|254] ""  BGW,TOOL
 SG_ componentNum_PSM M : 7|8@0+ (1,0) [0|254] ""  BGW,TOOL
 SG_ idGitHashUpper_PSM m1 : 55|16@0+ (1,0) [0|65534] ""  BGW,TOOL
 SG_ idBootGitHashUpper_PSM m0 : 55|16@0+ (1,0) [0|65534] ""  BGW,TOOL
 SG_ idBuildMachine_PSM m1 : 47|8@0+ (1,0) [0|254] ""  BGW,TOOL
 SG_ versionSubMinor_PSM m1 : 39|8@0+ (1,0) [0|254] ""  BGW,TOOL
 SG_ versionMinor_PSM m1 : 23|8@0+ (1,0) [0|254] ""  BGW,TOOL
 SG_ versionMajor_PSM m1 : 15|8@0+ (1,0) [0|254] ""  BGW,TOOL
 SG_ idBootBuildMachine_PSM m0 : 47|8@0+ (1,0) [0|254] ""  BGW,TOOL
 SG_ versionBootSubMinor_PSM m0 : 39|8@0+ (1,0) [0|254] ""  BGW,TOOL
 SG_ versionBootMinor_PSM m0 : 23|8@0+ (1,0) [0|254] ""  BGW,TOOL
 SG_ versionBootMajor_PSM m0 : 15|8@0+ (1,0) [0|254] ""  BGW,TOOL

BO_ 1705 DCRL_NetworkManagement: 6 DCRL
 SG_ nmPartialNetworks_DCRL : 6|1@0+ (1,0) [0|1] ""  BGW,DCFR,DCRR,FBCM
 SG_ nmActiveWake_DCRL : 4|1@0+ (1,0) [0|1] ""  BGW,DCFR,DCRR,FBCM
 SG_ nmID_DCRL : 15|8@0+ (1,0) [0|31] ""  BGW,DCFR,DCRR,FBCM
 SG_ nmPnBody_DCRL : 19|1@0+ (1,0) [0|1] ""  BGW,DCFR,DCRR,FBCM
 SG_ nmPnCharging_DCRL : 18|1@0+ (1,0) [0|1] ""  BGW
 SG_ nmPnKeypad_DCRL : 29|1@0+ (1,0) [0|1] ""  BGW
 SG_ nmPnBPG_DCRL : 37|1@0+ (1,0) [0|1] ""  BGW

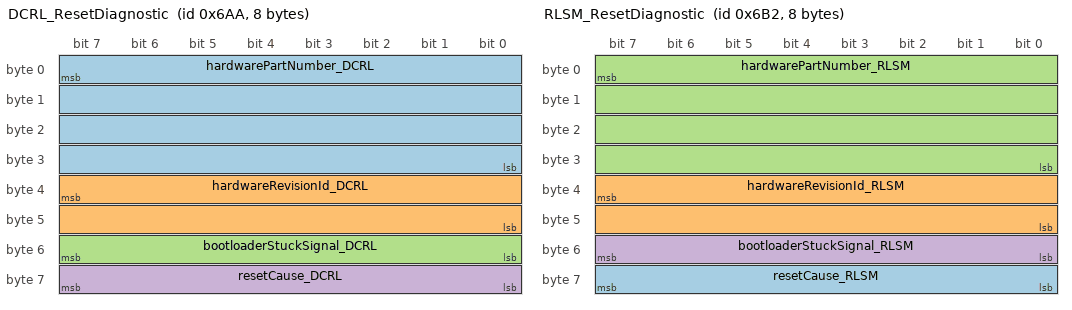
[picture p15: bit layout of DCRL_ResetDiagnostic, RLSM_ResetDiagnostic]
BO_ 1706 DCRL_ResetDiagnostic: 8 DCRL
 SG_ hardwarePartNumber_DCRL : 7|32@0+ (1,0) [0|4294967294] ""  TOOL
 SG_ hardwareRevisionId_DCRL : 39|16@0+ (1,0) [0|65534] ""  TOOL
 SG_ bootloaderStuckSignal_DCRL : 55|8@0+ (1,0) [0|254] ""  TOOL
 SG_ resetCause_DCRL : 63|8@0+ (1,0) [0|254] ""  BGW,TOOL

BO_ 1709 DCRL_UDSRequest: 8 TOOL
 SG_ udsClientDataDcrl_TOOL : 7|64@0+ (1,0) [0|1.84467440737094E+019] ""  DCRL

BO_ 1710 DCRL_UDSResponse: 8 DCRL
 SG_ udsServerData_DCRL : 7|64@0+ (1,0) [0|1.84467440737094E+019] ""  TOOL

BO_ 1711 DCRL_Version: 8 DCRL
 SG_ versionCalSubMinor_DCRL m1 : 39|8@0+ (1,0) [0|254] ""  BGW,TOOL
 SG_ versionCalReleaseCandidate_DCRL m1 : 31|8@0+ (1,0) [0|254] ""  BGW,TOOL
 SG_ versionCalMinor_DCRL m1 : 23|8@0+ (1,0) [0|254] ""  BGW,TOOL
 SG_ versionCalMajor_DCRL m1 : 15|8@0+ (1,0) [0|254] ""  BGW,TOOL
 SG_ idCalBuildMachine_DCRL m1 : 47|8@0+ (1,0) [0|254] ""  BGW,TOOL
 SG_ idCalGitHashUpper_DCRL m1 : 55|16@0+ (1,0) [0|65534] ""  BGW,TOOL
 SG_ versionReleaseCandidate_DCRL m2 : 31|8@0+ (1,0) [0|254] ""  BGW,TOOL
 SG_ versionBootReleaseCandidate_DCRL m0 : 31|8@0+ (1,0) [0|254] ""  BGW,TOOL
 SG_ componentNum_DCRL M : 7|8@0+ (1,0) [0|254] ""  BGW,TOOL
 SG_ idGitHashUpper_DCRL m2 : 55|16@0+ (1,0) [0|65534] ""  BGW,TOOL
 SG_ idBootGitHashUpper_DCRL m0 : 55|16@0+ (1,0) [0|65534] ""  BGW,TOOL
 SG_ idBuildMachine_DCRL m2 : 47|8@0+ (1,0) [0|254] ""  BGW,TOOL
 SG_ versionSubMinor_DCRL m2 : 39|8@0+ (1,0) [0|254] ""  BGW,TOOL
 SG_ versionMinor_DCRL m2 : 23|8@0+ (1,0) [0|254] ""  BGW,TOOL
 SG_ versionMajor_DCRL m2 : 15|8@0+ (1,0) [0|254] ""  BGW,TOOL
 SG_ idBootBuildMachine_DCRL m0 : 47|8@0+ (1,0) [0|254] ""  BGW,TOOL
 SG_ versionBootSubMinor_DCRL m0 : 39|8@0+ (1,0) [0|254] ""  BGW,TOOL
 SG_ versionBootMinor_DCRL m0 : 23|8@0+ (1,0) [0|254] ""  BGW,TOOL
 SG_ versionBootMajor_DCRL m0 : 15|8@0+ (1,0) [0|254] ""  BGW,TOOL

BO_ 1714 RLSM_ResetDiagnostic: 8 RLSM
 SG_ resetCause_RLSM : 63|8@0+ (1,0) [0|254] ""  TOOL
 SG_ hardwareRevisionId_RLSM : 39|16@0+ (1,0) [0|65534] ""  TOOL
 SG_ hardwarePartNumber_RLSM : 7|32@0+ (1,0) [0|4294967294] ""  TOOL
 SG_ bootloaderStuckSignal_RLSM : 55|8@0+ (1,0) [0|254] ""  TOOL

BO_ 1717 RLSM_UDSRequest: 8 TOOL
 SG_ udsClientDataRLSM_TOOL : 7|64@0+ (1,0) [0|1.84467440737094E+019] ""  RLSM

BO_ 1718 RLSM_UDSResponse: 8 RLSM
 SG_ udsServerData_RLSM : 7|64@0+ (1,0) [0|1.84467440737094E+019] ""  TOOL

BO_ 1719 RLSM_Version: 8 RLSM
 SG_ versionReleaseCandidate_RLSM m1 : 31|8@0+ (1,0) [0|254] ""  BGW,TOOL
 SG_ versionBootReleaseCandidate_RLSM m0 : 31|8@0+ (1,0) [0|254] ""  BGW,TOOL
 SG_ componentNum_RLSM M : 7|8@0+ (1,0) [0|254] ""  BGW,TOOL
 SG_ idGitHashUpper_RLSM m1 : 55|16@0+ (1,0) [0|65534] ""  BGW,TOOL
 SG_ idBootGitHashUpper_RLSM m0 : 55|16@0+ (1,0) [0|65534] ""  BGW,TOOL
 SG_ idBuildMachine_RLSM m1 : 47|8@0+ (1,0) [0|254] ""  BGW,TOOL
 SG_ versionSubMinor_RLSM m1 : 39|8@0+ (1,0) [0|254] ""  BGW,TOOL
 SG_ versionMinor_RLSM m1 : 23|8@0+ (1,0) [0|254] ""  BGW,TOOL
 SG_ versionMajor_RLSM m1 : 15|8@0+ (1,0) [0|254] ""  BGW,TOOL
 SG_ idBootBuildMachine_RLSM m0 : 47|8@0+ (1,0) [0|254] ""  BGW,TOOL
 SG_ versionBootSubMinor_RLSM m0 : 39|8@0+ (1,0) [0|254] ""  BGW,TOOL
 SG_ versionBootMinor_RLSM m0 : 23|8@0+ (1,0) [0|254] ""  BGW,TOOL
 SG_ versionBootMajor_RLSM m0 : 15|8@0+ (1,0) [0|254] ""  BGW,TOOL

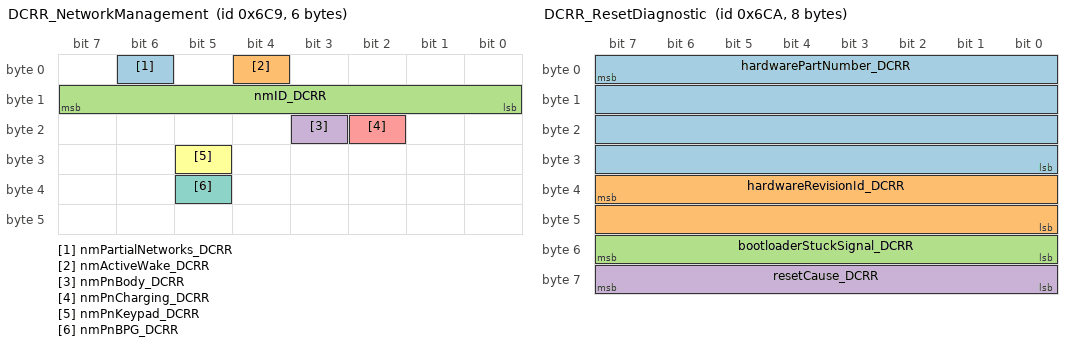
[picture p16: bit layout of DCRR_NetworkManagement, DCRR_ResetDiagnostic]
BO_ 1737 DCRR_NetworkManagement: 6 DCRR
 SG_ nmPartialNetworks_DCRR : 6|1@0+ (1,0) [0|1] ""  BGW,DCFR,DCRL,FBCM
 SG_ nmActiveWake_DCRR : 4|1@0+ (1,0) [0|1] ""  BGW,DCFR,DCRL,FBCM
 SG_ nmID_DCRR : 15|8@0+ (1,0) [0|31] ""  BGW,DCFR,DCRL,FBCM
 SG_ nmPnBody_DCRR : 19|1@0+ (1,0) [0|1] ""  BGW,DCFR,DCRL,FBCM
 SG_ nmPnCharging_DCRR : 18|1@0+ (1,0) [0|1] ""  BGW
 SG_ nmPnKeypad_DCRR : 29|1@0+ (1,0) [0|1] ""  BGW
 SG_ nmPnBPG_DCRR : 37|1@0+ (1,0) [0|1] ""  BGW

BO_ 1738 DCRR_ResetDiagnostic: 8 DCRR
 SG_ hardwarePartNumber_DCRR : 7|32@0+ (1,0) [0|4294967294] ""  TOOL
 SG_ hardwareRevisionId_DCRR : 39|16@0+ (1,0) [0|65534] ""  TOOL
 SG_ bootloaderStuckSignal_DCRR : 55|8@0+ (1,0) [0|254] ""  TOOL
 SG_ resetCause_DCRR : 63|8@0+ (1,0) [0|254] ""  BGW,TOOL

BO_ 1741 DCRR_UDSRequest: 8 TOOL
 SG_ udsClientDataDcrr_TOOL : 7|64@0+ (1,0) [0|1.84467440737094E+019] ""  DCRR

BO_ 1742 DCRR_UDSResponse: 8 DCRR
 SG_ udsServerData_DCRR : 7|64@0+ (1,0) [0|1.84467440737094E+019] ""  TOOL

BO_ 1743 DCRR_Version: 8 DCRR
 SG_ versionCalSubMinor_DCRR m1 : 39|8@0+ (1,0) [0|254] ""  BGW,TOOL
 SG_ versionCalReleaseCandidate_DCRR m1 : 31|8@0+ (1,0) [0|254] ""  BGW,TOOL
 SG_ versionCalMinor_DCRR m1 : 23|8@0+ (1,0) [0|254] ""  BGW,TOOL
 SG_ versionCalMajor_DCRR m1 : 15|8@0+ (1,0) [0|254] ""  BGW,TOOL
 SG_ idCalBuildMachine_DCRR m1 : 47|8@0+ (1,0) [0|254] ""  BGW,TOOL
 SG_ idCalGitHashUpper_DCRR m1 : 55|16@0+ (1,0) [0|65534] ""  BGW,TOOL
 SG_ versionReleaseCandidate_DCRR m2 : 31|8@0+ (1,0) [0|254] ""  BGW,TOOL
 SG_ versionBootReleaseCandidate_DCRR m0 : 31|8@0+ (1,0) [0|254] ""  BGW,TOOL
 SG_ componentNum_DCRR M : 7|8@0+ (1,0) [0|254] ""  BGW,TOOL
 SG_ idGitHashUpper_DCRR m2 : 55|16@0+ (1,0) [0|65534] ""  BGW,TOOL
 SG_ idBootGitHashUpper_DCRR m0 : 55|16@0+ (1,0) [0|65534] ""  BGW,TOOL
 SG_ idBuildMachine_DCRR m2 : 47|8@0+ (1,0) [0|254] ""  BGW,TOOL
 SG_ versionSubMinor_DCRR m2 : 39|8@0+ (1,0) [0|254] ""  BGW,TOOL
 SG_ versionMinor_DCRR m2 : 23|8@0+ (1,0) [0|254] ""  BGW,TOOL
 SG_ versionMajor_DCRR m2 : 15|8@0+ (1,0) [0|254] ""  BGW,TOOL
 SG_ idBootBuildMachine_DCRR m0 : 47|8@0+ (1,0) [0|254] ""  BGW,TOOL
 SG_ versionBootSubMinor_DCRR m0 : 39|8@0+ (1,0) [0|254] ""  BGW,TOOL
 SG_ versionBootMinor_DCRR m0 : 23|8@0+ (1,0) [0|254] ""  BGW,TOOL
 SG_ versionBootMajor_DCRR m0 : 15|8@0+ (1,0) [0|254] ""  BGW,TOOL

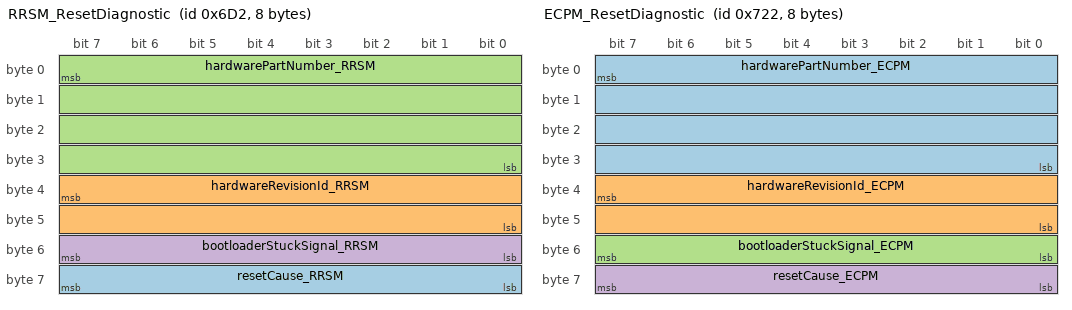
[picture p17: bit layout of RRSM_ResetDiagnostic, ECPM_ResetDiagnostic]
BO_ 1746 RRSM_ResetDiagnostic: 8 RRSM
 SG_ resetCause_RRSM : 63|8@0+ (1,0) [0|254] ""  TOOL
 SG_ hardwareRevisionId_RRSM : 39|16@0+ (1,0) [0|65534] ""  TOOL
 SG_ hardwarePartNumber_RRSM : 7|32@0+ (1,0) [0|4294967294] ""  TOOL
 SG_ bootloaderStuckSignal_RRSM : 55|8@0+ (1,0) [0|254] ""  TOOL

BO_ 1749 RRSM_UDSRequest: 8 TOOL
 SG_ udsClientDataRRSM_TOOL : 7|64@0+ (1,0) [0|1.84467440737094E+019] ""  RRSM

BO_ 1750 RRSM_UDSResponse: 8 RRSM
 SG_ udsServerData_RRSM : 7|64@0+ (1,0) [0|1.84467440737094E+019] ""  TOOL

BO_ 1751 RRSM_Version: 8 RRSM
 SG_ versionReleaseCandidate_RRSM m1 : 31|8@0+ (1,0) [0|254] ""  BGW,TOOL
 SG_ versionBootReleaseCandidate_RRSM m0 : 31|8@0+ (1,0) [0|254] ""  BGW,TOOL
 SG_ componentNum_RRSM M : 7|8@0+ (1,0) [0|254] ""  BGW,TOOL
 SG_ idGitHashUpper_RRSM m1 : 55|16@0+ (1,0) [0|65534] ""  BGW,TOOL
 SG_ idBootGitHashUpper_RRSM m0 : 55|16@0+ (1,0) [0|65534] ""  BGW,TOOL
 SG_ idBuildMachine_RRSM m1 : 47|8@0+ (1,0) [0|254] ""  BGW,TOOL
 SG_ versionSubMinor_RRSM m1 : 39|8@0+ (1,0) [0|254] ""  BGW,TOOL
 SG_ versionMinor_RRSM m1 : 23|8@0+ (1,0) [0|254] ""  BGW,TOOL
 SG_ versionMajor_RRSM m1 : 15|8@0+ (1,0) [0|254] ""  BGW,TOOL
 SG_ idBootBuildMachine_RRSM m0 : 47|8@0+ (1,0) [0|254] ""  BGW,TOOL
 SG_ versionBootSubMinor_RRSM m0 : 39|8@0+ (1,0) [0|254] ""  BGW,TOOL
 SG_ versionBootMinor_RRSM m0 : 23|8@0+ (1,0) [0|254] ""  BGW,TOOL
 SG_ versionBootMajor_RRSM m0 : 15|8@0+ (1,0) [0|254] ""  BGW,TOOL

BO_ 1773 LGL_UDSRequest: 8 TOOL
 SG_ udsClientDataLGL_TOOL : 7|64@0+ (1,0) [0|1.84467440737094E+019] ""  LGL

BO_ 1774 LGL_UDSResponse: 8 LGL
 SG_ udsServerData_LGL : 7|64@0+ (1,0) [0|1.84467440737094E+019] ""  TOOL

BO_ 1775 LGL_Version: 8 LGL
 SG_ versionReleaseCandidate_LGL m1 : 31|8@0+ (1,0) [0|254] ""  BGW,TOOL
 SG_ versionBootReleaseCandidate_LGL m0 : 31|8@0+ (1,0) [0|254] ""  BGW,TOOL
 SG_ componentNum_LGL M : 7|8@0+ (1,0) [0|254] ""  BGW,TOOL
 SG_ idGitHashUpper_LGL m1 : 55|16@0+ (1,0) [0|65534] ""  BGW,TOOL
 SG_ idBootGitHashUpper_LGL m0 : 55|16@0+ (1,0) [0|65534] ""  BGW,TOOL
 SG_ idBuildMachine_LGL m1 : 47|8@0+ (1,0) [0|254] ""  BGW,TOOL
 SG_ versionSubMinor_LGL m1 : 39|8@0+ (1,0) [0|254] ""  BGW,TOOL
 SG_ versionMinor_LGL m1 : 23|8@0+ (1,0) [0|254] ""  BGW,TOOL
 SG_ versionMajor_LGL m1 : 15|8@0+ (1,0) [0|254] ""  BGW,TOOL
 SG_ idBootBuildMachine_LGL m0 : 47|8@0+ (1,0) [0|254] ""  BGW,TOOL
 SG_ versionBootSubMinor_LGL m0 : 39|8@0+ (1,0) [0|254] ""  BGW,TOOL
 SG_ versionBootMinor_LGL m0 : 23|8@0+ (1,0) [0|254] ""  BGW,TOOL
 SG_ versionBootMajor_LGL m0 : 15|8@0+ (1,0) [0|254] ""  BGW,TOOL

BO_ 1789 RCLL_UDSRequest: 8 TOOL
 SG_ udsClientDataRCLL_TOOL : 7|64@0+ (1,0) [0|1.84467440737094E+019] ""  RCLL

BO_ 1790 RCLL_UDSResponse: 8 RCLL
 SG_ udsServerData_RCLL : 7|64@0+ (1,0) [0|1.84467440737094E+019] ""  TOOL

BO_ 1791 RCLL_Version: 8 RCLL
 SG_ versionReleaseCandidate_RCLL m1 : 31|8@0+ (1,0) [0|254] ""  BGW,TOOL
 SG_ versionBootReleaseCandidate_RCLL m0 : 31|8@0+ (1,0) [0|254] ""  BGW,TOOL
 SG_ componentNum_RCLL M : 7|8@0+ (1,0) [0|254] ""  BGW,TOOL
 SG_ idGitHashUpper_RCLL m1 : 55|16@0+ (1,0) [0|65534] ""  BGW,TOOL
 SG_ idBootGitHashUpper_RCLL m0 : 55|16@0+ (1,0) [0|65534] ""  BGW,TOOL
 SG_ idBuildMachine_RCLL m1 : 47|8@0+ (1,0) [0|254] ""  BGW,TOOL
 SG_ versionSubMinor_RCLL m1 : 39|8@0+ (1,0) [0|254] ""  BGW,TOOL
 SG_ versionMinor_RCLL m1 : 23|8@0+ (1,0) [0|254] ""  BGW,TOOL
 SG_ versionMajor_RCLL m1 : 15|8@0+ (1,0) [0|254] ""  BGW,TOOL
 SG_ idBootBuildMachine_RCLL m0 : 47|8@0+ (1,0) [0|254] ""  BGW,TOOL
 SG_ versionBootSubMinor_RCLL m0 : 39|8@0+ (1,0) [0|254] ""  BGW,TOOL
 SG_ versionBootMinor_RCLL m0 : 23|8@0+ (1,0) [0|254] ""  BGW,TOOL
 SG_ versionBootMajor_RCLL m0 : 15|8@0+ (1,0) [0|254] ""  BGW,TOOL

BO_ 1797 RCLR_UDSRequest: 8 TOOL
 SG_ udsClientDataRCLR_TOOL : 7|64@0+ (1,0) [0|1.84467440737094E+019] ""  RCLR

BO_ 1798 RCLR_UDSResponse: 8 RCLR
 SG_ udsServerData_RCLR : 7|64@0+ (1,0) [0|1.84467440737094E+019] ""  TOOL

BO_ 1799 RCLR_Version: 8 RCLR
 SG_ versionReleaseCandidate_RCLR m1 : 31|8@0+ (1,0) [0|254] ""  BGW,TOOL
 SG_ versionBootReleaseCandidate_RCLR m0 : 31|8@0+ (1,0) [0|254] ""  BGW,TOOL
 SG_ componentNum_RCLR M : 7|8@0+ (1,0) [0|254] ""  BGW,TOOL
 SG_ idGitHashUpper_RCLR m1 : 55|16@0+ (1,0) [0|65534] ""  BGW,TOOL
 SG_ idBootGitHashUpper_RCLR m0 : 55|16@0+ (1,0) [0|65534] ""  BGW,TOOL
 SG_ idBuildMachine_RCLR m1 : 47|8@0+ (1,0) [0|254] ""  BGW,TOOL
 SG_ versionSubMinor_RCLR m1 : 39|8@0+ (1,0) [0|254] ""  BGW,TOOL
 SG_ versionMinor_RCLR m1 : 23|8@0+ (1,0) [0|254] ""  BGW,TOOL
 SG_ versionMajor_RCLR m1 : 15|8@0+ (1,0) [0|254] ""  BGW,TOOL
 SG_ idBootBuildMachine_RCLR m0 : 47|8@0+ (1,0) [0|254] ""  BGW,TOOL
 SG_ versionBootSubMinor_RCLR m0 : 39|8@0+ (1,0) [0|254] ""  BGW,TOOL
 SG_ versionBootMinor_RCLR m0 : 23|8@0+ (1,0) [0|254] ""  BGW,TOOL
 SG_ versionBootMajor_RCLR m0 : 15|8@0+ (1,0) [0|254] ""  BGW,TOOL

BO_ 1813 ACCL_UDSRequest: 8 TOOL
 SG_ udsClientDataACCL_TOOL : 7|64@0+ (1,0) [0|1.84467440737094E+019] ""  ACCL

BO_ 1814 ACCL_UDSResponse: 8 ACCL
 SG_ udsServerData_ACCL : 7|64@0+ (1,0) [0|1.84467440737094E+019] ""  TOOL

BO_ 1815 ACCL_Version: 8 ACCL
 SG_ versionReleaseCandidate_ACCL m1 : 31|8@0+ (1,0) [0|254] ""  BGW,TOOL
 SG_ versionBootReleaseCandidate_ACCL m0 : 31|8@0+ (1,0) [0|254] ""  BGW,TOOL
 SG_ componentNum_ACCL M : 7|8@0+ (1,0) [0|254] ""  BGW,TOOL
 SG_ idGitHashUpper_ACCL m1 : 55|16@0+ (1,0) [0|65534] ""  BGW,TOOL
 SG_ idBootGitHashUpper_ACCL m0 : 55|16@0+ (1,0) [0|65534] ""  BGW,TOOL
 SG_ idBuildMachine_ACCL m1 : 47|8@0+ (1,0) [0|254] ""  BGW,TOOL
 SG_ versionSubMinor_ACCL m1 : 39|8@0+ (1,0) [0|254] ""  BGW,TOOL
 SG_ versionMinor_ACCL m1 : 23|8@0+ (1,0) [0|254] ""  BGW,TOOL
 SG_ versionMajor_ACCL m1 : 15|8@0+ (1,0) [0|254] ""  BGW,TOOL
 SG_ idBootBuildMachine_ACCL m0 : 47|8@0+ (1,0) [0|254] ""  BGW,TOOL
 SG_ versionBootSubMinor_ACCL m0 : 39|8@0+ (1,0) [0|254] ""  BGW,TOOL
 SG_ versionBootMinor_ACCL m0 : 23|8@0+ (1,0) [0|254] ""  BGW,TOOL
 SG_ versionBootMajor_ACCL m0 : 15|8@0+ (1,0) [0|254] ""  BGW,TOOL

BO_ 1826 ECPM_ResetDiagnostic: 8 ECPM
 SG_ hardwarePartNumber_ECPM : 7|32@0+ (1,0) [0|4294967294] ""  TOOL
 SG_ hardwareRevisionId_ECPM : 39|16@0+ (1,0) [0|65534] ""  TOOL
 SG_ bootloaderStuckSignal_ECPM : 55|8@0+ (1,0) [0|254] ""  TOOL
 SG_ resetCause_ECPM : 63|8@0+ (1,0) [0|254] ""  TOOL

BO_ 1829 ECPM_UDSRequest: 8 TOOL
 SG_ udsClientDataECPM_TOOL : 7|64@0+ (1,0) [0|1.84467440737094E+019] ""  ECPM

BO_ 1830 ECPM_UDSResponse: 8 ECPM
 SG_ udsServerData_ECPM : 7|64@0+ (1,0) [0|1.84467440737094E+019] ""  TOOL

BO_ 1831 ECPM_Version: 8 ECPM
 SG_ versionReleaseCandidate_ECPM m1 : 31|8@0+ (1,0) [0|254] ""  BGW,TOOL
 SG_ versionBootReleaseCandidate_ECPM m0 : 31|8@0+ (1,0) [0|254] ""  BGW,TOOL
 SG_ componentNum_ECPM M : 7|8@0+ (1,0) [0|254] ""  BGW,TOOL
 SG_ idGitHashUpper_ECPM m1 : 55|16@0+ (1,0) [0|65534] ""  BGW,TOOL
 SG_ idBootGitHashUpper_ECPM m0 : 55|16@0+ (1,0) [0|65534] ""  BGW,TOOL
 SG_ idBuildMachine_ECPM m1 : 47|8@0+ (1,0) [0|254] ""  BGW,TOOL
 SG_ versionSubMinor_ECPM m1 : 39|8@0+ (1,0) [0|254] ""  BGW,TOOL
 SG_ versionMinor_ECPM m1 : 23|8@0+ (1,0) [0|254] ""  BGW,TOOL
 SG_ versionMajor_ECPM m1 : 15|8@0+ (1,0) [0|254] ""  BGW,TOOL
 SG_ idBootBuildMachine_ECPM m0 : 47|8@0+ (1,0) [0|254] ""  BGW,TOOL
 SG_ versionBootSubMinor_ECPM m0 : 39|8@0+ (1,0) [0|254] ""  BGW,TOOL
 SG_ versionBootMinor_ECPM m0 : 23|8@0+ (1,0) [0|254] ""  BGW,TOOL
 SG_ versionBootMajor_ECPM m0 : 15|8@0+ (1,0) [0|254] ""  BGW,TOOL

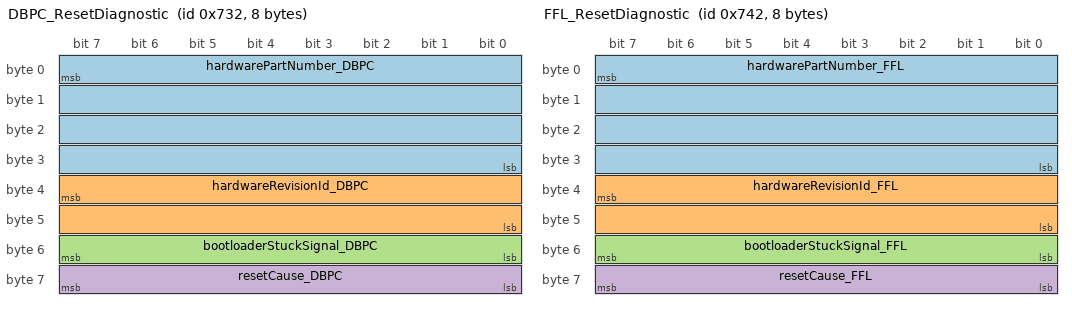
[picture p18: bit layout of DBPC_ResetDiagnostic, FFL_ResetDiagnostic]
BO_ 1842 DBPC_ResetDiagnostic: 8 DBPC
 SG_ hardwarePartNumber_DBPC : 7|32@0+ (1,0) [0|4294967294] ""  TOOL
 SG_ hardwareRevisionId_DBPC : 39|16@0+ (1,0) [0|65534] ""  TOOL
 SG_ bootloaderStuckSignal_DBPC : 55|8@0+ (1,0) [0|254] ""  TOOL
 SG_ resetCause_DBPC : 63|8@0+ (1,0) [0|254] ""  TOOL

BO_ 1845 DBPC_UDSRequest: 8 TOOL
 SG_ udsClientDataDBPC_TOOL : 7|64@0+ (1,0) [0|1.84467440737094E+019] ""  DBPC

BO_ 1846 DBPC_UDSResponse: 8 DBPC
 SG_ udsServerData_DBPC : 7|64@0+ (1,0) [0|1.84467440737094E+019] ""  TOOL

BO_ 1847 DBPC_Version: 8 DBPC
 SG_ versionReleaseCandidate_DBPC m1 : 31|8@0+ (1,0) [0|254] ""  BGW,TOOL
 SG_ versionBootReleaseCandidate_DBPC m0 : 31|8@0+ (1,0) [0|254] ""  BGW,TOOL
 SG_ componentNum_DBPC M : 7|8@0+ (1,0) [0|254] ""  BGW,TOOL
 SG_ idGitHashUpper_DBPC m1 : 55|16@0+ (1,0) [0|65534] ""  BGW,TOOL
 SG_ idBootGitHashUpper_DBPC m0 : 55|16@0+ (1,0) [0|65534] ""  BGW,TOOL
 SG_ idBuildMachine_DBPC m1 : 47|8@0+ (1,0) [0|254] ""  BGW,TOOL
 SG_ versionSubMinor_DBPC m1 : 39|8@0+ (1,0) [0|254] ""  BGW,TOOL
 SG_ versionMinor_DBPC m1 : 23|8@0+ (1,0) [0|254] ""  BGW,TOOL
 SG_ versionMajor_DBPC m1 : 15|8@0+ (1,0) [0|254] ""  BGW,TOOL
 SG_ idBootBuildMachine_DBPC m0 : 47|8@0+ (1,0) [0|254] ""  BGW,TOOL
 SG_ versionBootSubMinor_DBPC m0 : 39|8@0+ (1,0) [0|254] ""  BGW,TOOL
 SG_ versionBootMinor_DBPC m0 : 23|8@0+ (1,0) [0|254] ""  BGW,TOOL
 SG_ versionBootMajor_DBPC m0 : 15|8@0+ (1,0) [0|254] ""  BGW,TOOL

BO_ 1858 FFL_ResetDiagnostic: 8 FFL
 SG_ hardwarePartNumber_FFL : 7|32@0+ (1,0) [0|4294967294] ""  TOOL
 SG_ hardwareRevisionId_FFL : 39|16@0+ (1,0) [0|65534] ""  TOOL
 SG_ bootloaderStuckSignal_FFL : 55|8@0+ (1,0) [0|254] ""  TOOL
 SG_ resetCause_FFL : 63|8@0+ (1,0) [0|254] ""  TOOL

BO_ 1861 FFL_UDSRequest: 8 TOOL
 SG_ udsClientDataFFL_TOOL : 7|64@0+ (1,0) [0|1.84467440737094E+019] ""  FFL

BO_ 1862 FFL_UDSResponse: 8 FFL
 SG_ udsServerData_FFL : 7|64@0+ (1,0) [0|1.84467440737094E+019] ""  TOOL

BO_ 1863 FFL_Version: 8 FFL
 SG_ versionReleaseCandidate_FFL m1 : 31|8@0+ (1,0) [0|254] ""  BGW,TOOL
 SG_ versionBootReleaseCandidate_FFL m0 : 31|8@0+ (1,0) [0|254] ""  BGW,TOOL
 SG_ componentNum_FFL M : 7|8@0+ (1,0) [0|254] ""  BGW,TOOL
 SG_ idGitHashUpper_FFL m1 : 55|16@0+ (1,0) [0|65534] ""  BGW,TOOL
 SG_ idBootGitHashUpper_FFL m0 : 55|16@0+ (1,0) [0|65534] ""  BGW,TOOL
 SG_ idBuildMachine_FFL m1 : 47|8@0+ (1,0) [0|254] ""  BGW,TOOL
 SG_ versionSubMinor_FFL m1 : 39|8@0+ (1,0) [0|254] ""  BGW,TOOL
 SG_ versionMinor_FFL m1 : 23|8@0+ (1,0) [0|254] ""  BGW,TOOL
 SG_ versionMajor_FFL m1 : 15|8@0+ (1,0) [0|254] ""  BGW,TOOL
 SG_ idBootBuildMachine_FFL m0 : 47|8@0+ (1,0) [0|254] ""  BGW,TOOL
 SG_ versionBootSubMinor_FFL m0 : 39|8@0+ (1,0) [0|254] ""  BGW,TOOL
 SG_ versionBootMinor_FFL m0 : 23|8@0+ (1,0) [0|254] ""  BGW,TOOL
 SG_ versionBootMajor_FFL m0 : 15|8@0+ (1,0) [0|254] ""  BGW,TOOL

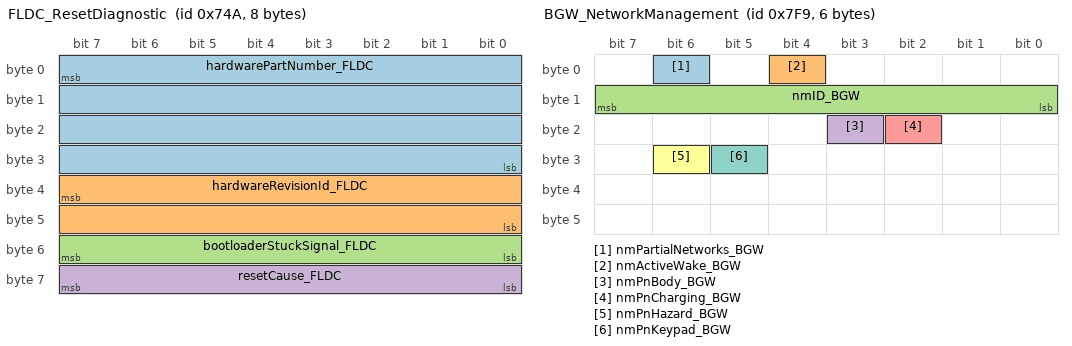
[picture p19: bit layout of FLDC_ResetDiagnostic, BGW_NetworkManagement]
BO_ 1866 FLDC_ResetDiagnostic: 8 FLDC
 SG_ hardwarePartNumber_FLDC : 7|32@0+ (1,0) [0|4294967294] ""  TOOL
 SG_ hardwareRevisionId_FLDC : 39|16@0+ (1,0) [0|65534] ""  TOOL
 SG_ bootloaderStuckSignal_FLDC : 55|8@0+ (1,0) [0|254] ""  TOOL
 SG_ resetCause_FLDC : 63|8@0+ (1,0) [0|254] ""  TOOL

BO_ 1869 FLDC_UDSRequest: 8 TOOL
 SG_ udsClientDataFLDC_TOOL : 7|64@0+ (1,0) [0|1.84467440737094E+019] ""  FLDC

BO_ 1870 FLDC_UDSResponse: 8 FLDC
 SG_ udsServerData_FLDC : 7|64@0+ (1,0) [0|1.84467440737094E+019] ""  TOOL

BO_ 1871 FLDC_Version: 8 FLDC
 SG_ versionReleaseCandidate_FLDC m1 : 31|8@0+ (1,0) [0|254] ""  BGW,TOOL
 SG_ versionBootReleaseCandidate_FLDC m0 : 31|8@0+ (1,0) [0|254] ""  BGW,TOOL
 SG_ componentNum_FLDC M : 7|8@0+ (1,0) [0|254] ""  BGW,TOOL
 SG_ idGitHashUpper_FLDC m1 : 55|16@0+ (1,0) [0|65534] ""  BGW,TOOL
 SG_ idBootGitHashUpper_FLDC m0 : 55|16@0+ (1,0) [0|65534] ""  BGW,TOOL
 SG_ idBuildMachine_FLDC m1 : 47|8@0+ (1,0) [0|254] ""  BGW,TOOL
 SG_ versionSubMinor_FLDC m1 : 39|8@0+ (1,0) [0|254] ""  BGW,TOOL
 SG_ versionMinor_FLDC m1 : 23|8@0+ (1,0) [0|254] ""  BGW,TOOL
 SG_ versionMajor_FLDC m1 : 15|8@0+ (1,0) [0|254] ""  BGW,TOOL
 SG_ idBootBuildMachine_FLDC m0 : 47|8@0+ (1,0) [0|254] ""  BGW,TOOL
 SG_ versionBootSubMinor_FLDC m0 : 39|8@0+ (1,0) [0|254] ""  BGW,TOOL
 SG_ versionBootMinor_FLDC m0 : 23|8@0+ (1,0) [0|254] ""  BGW,TOOL
 SG_ versionBootMajor_FLDC m0 : 15|8@0+ (1,0) [0|254] ""  BGW,TOOL

BO_ 1874 FRDC_ResetDiagnostic: 8 FRDC
 SG_ hardwarePartNumber_FRDC : 7|32@0+ (1,0) [0|4294967294] ""  TOOL
 SG_ hardwareRevisionId_FRDC : 39|16@0+ (1,0) [0|65534] ""  TOOL
 SG_ bootloaderStuckSignal_FRDC : 55|8@0+ (1,0) [0|254] ""  TOOL
 SG_ resetCause_FRDC : 63|8@0+ (1,0) [0|254] ""  TOOL

BO_ 1877 FRDC_UDSRequest: 8 TOOL
 SG_ udsClientDataFRDC_TOOL : 7|64@0+ (1,0) [0|1.84467440737094E+019] ""  FRDC

BO_ 1878 FRDC_UDSResponse: 8 FRDC
 SG_ udsServerData_FRDC : 7|64@0+ (1,0) [0|1.84467440737094E+019] ""  TOOL

BO_ 1879 FRDC_Version: 8 FRDC
 SG_ versionReleaseCandidate_FRDC m1 : 31|8@0+ (1,0) [0|254] ""  BGW,TOOL
 SG_ versionBootReleaseCandidate_FRDC m0 : 31|8@0+ (1,0) [0|254] ""  BGW,TOOL
 SG_ componentNum_FRDC M : 7|8@0+ (1,0) [0|254] ""  BGW,TOOL
 SG_ idGitHashUpper_FRDC m1 : 55|16@0+ (1,0) [0|65534] ""  BGW,TOOL
 SG_ idBootGitHashUpper_FRDC m0 : 55|16@0+ (1,0) [0|65534] ""  BGW,TOOL
 SG_ idBuildMachine_FRDC m1 : 47|8@0+ (1,0) [0|254] ""  BGW,TOOL
 SG_ versionSubMinor_FRDC m1 : 39|8@0+ (1,0) [0|254] ""  BGW,TOOL
 SG_ versionMinor_FRDC m1 : 23|8@0+ (1,0) [0|254] ""  BGW,TOOL
 SG_ versionMajor_FRDC m1 : 15|8@0+ (1,0) [0|254] ""  BGW,TOOL
 SG_ idBootBuildMachine_FRDC m0 : 47|8@0+ (1,0) [0|254] ""  BGW,TOOL
 SG_ versionBootSubMinor_FRDC m0 : 39|8@0+ (1,0) [0|254] ""  BGW,TOOL
 SG_ versionBootMinor_FRDC m0 : 23|8@0+ (1,0) [0|254] ""  BGW,TOOL
 SG_ versionBootMajor_FRDC m0 : 15|8@0+ (1,0) [0|254] ""  BGW,TOOL

BO_ 1882 RLDC_ResetDiagnostic: 8 RLDC
 SG_ hardwarePartNumber_RLDC : 7|32@0+ (1,0) [0|4294967294] ""  TOOL
 SG_ hardwareRevisionId_RLDC : 39|16@0+ (1,0) [0|65534] ""  TOOL
 SG_ bootloaderStuckSignal_RLDC : 55|8@0+ (1,0) [0|254] ""  TOOL
 SG_ resetCause_RLDC : 63|8@0+ (1,0) [0|254] ""  TOOL

BO_ 1885 RLDC_UDSRequest: 8 TOOL
 SG_ udsClientDataRLDC_TOOL : 7|64@0+ (1,0) [0|1.84467440737094E+019] ""  RLDC

BO_ 1886 RLDC_UDSResponse: 8 RLDC
 SG_ udsServerData_RLDC : 7|64@0+ (1,0) [0|1.84467440737094E+019] ""  TOOL

BO_ 1887 RLDC_Version: 8 RLDC
 SG_ versionReleaseCandidate_RLDC m1 : 31|8@0+ (1,0) [0|254] ""  BGW,TOOL
 SG_ versionBootReleaseCandidate_RLDC m0 : 31|8@0+ (1,0) [0|254] ""  BGW,TOOL
 SG_ componentNum_RLDC M : 7|8@0+ (1,0) [0|254] ""  BGW,TOOL
 SG_ idGitHashUpper_RLDC m1 : 55|16@0+ (1,0) [0|65534] ""  BGW,TOOL
 SG_ idBootGitHashUpper_RLDC m0 : 55|16@0+ (1,0) [0|65534] ""  BGW,TOOL
 SG_ idBuildMachine_RLDC m1 : 47|8@0+ (1,0) [0|254] ""  BGW,TOOL
 SG_ versionSubMinor_RLDC m1 : 39|8@0+ (1,0) [0|254] ""  BGW,TOOL
 SG_ versionMinor_RLDC m1 : 23|8@0+ (1,0) [0|254] ""  BGW,TOOL
 SG_ versionMajor_RLDC m1 : 15|8@0+ (1,0) [0|254] ""  BGW,TOOL
 SG_ idBootBuildMachine_RLDC m0 : 47|8@0+ (1,0) [0|254] ""  BGW,TOOL
 SG_ versionBootSubMinor_RLDC m0 : 39|8@0+ (1,0) [0|254] ""  BGW,TOOL
 SG_ versionBootMinor_RLDC m0 : 23|8@0+ (1,0) [0|254] ""  BGW,TOOL
 SG_ versionBootMajor_RLDC m0 : 15|8@0+ (1,0) [0|254] ""  BGW,TOOL

BO_ 1890 RRDC_ResetDiagnostic: 8 RRDC
 SG_ hardwarePartNumber_RRDC : 7|32@0+ (1,0) [0|4294967294] ""  TOOL
 SG_ hardwareRevisionId_RRDC : 39|16@0+ (1,0) [0|65534] ""  TOOL
 SG_ bootloaderStuckSignal_RRDC : 55|8@0+ (1,0) [0|254] ""  TOOL
 SG_ resetCause_RRDC : 63|8@0+ (1,0) [0|254] ""  TOOL

BO_ 1893 RRDC_UDSRequest: 8 TOOL
 SG_ udsClientDataRRDC_TOOL : 7|64@0+ (1,0) [0|1.84467440737094E+019] ""  RRDC

BO_ 1894 RRDC_UDSResponse: 8 RRDC
 SG_ udsServerData_RRDC : 7|64@0+ (1,0) [0|1.84467440737094E+019] ""  TOOL

BO_ 1895 RRDC_Version: 8 RRDC
 SG_ versionReleaseCandidate_RRDC m1 : 31|8@0+ (1,0) [0|254] ""  BGW,TOOL
 SG_ versionBootReleaseCandidate_RRDC m0 : 31|8@0+ (1,0) [0|254] ""  BGW,TOOL
 SG_ componentNum_RRDC M : 7|8@0+ (1,0) [0|254] ""  BGW,TOOL
 SG_ idGitHashUpper_RRDC m1 : 55|16@0+ (1,0) [0|65534] ""  BGW,TOOL
 SG_ idBootGitHashUpper_RRDC m0 : 55|16@0+ (1,0) [0|65534] ""  BGW,TOOL
 SG_ idBuildMachine_RRDC m1 : 47|8@0+ (1,0) [0|254] ""  BGW,TOOL
 SG_ versionSubMinor_RRDC m1 : 39|8@0+ (1,0) [0|254] ""  BGW,TOOL
 SG_ versionMinor_RRDC m1 : 23|8@0+ (1,0) [0|254] ""  BGW,TOOL
 SG_ versionMajor_RRDC m1 : 15|8@0+ (1,0) [0|254] ""  BGW,TOOL
 SG_ idBootBuildMachine_RRDC m0 : 47|8@0+ (1,0) [0|254] ""  BGW,TOOL
 SG_ versionBootSubMinor_RRDC m0 : 39|8@0+ (1,0) [0|254] ""  BGW,TOOL
 SG_ versionBootMinor_RRDC m0 : 23|8@0+ (1,0) [0|254] ""  BGW,TOOL
 SG_ versionBootMajor_RRDC m0 : 15|8@0+ (1,0) [0|254] ""  BGW,TOOL

BO_ 2041 BGW_NetworkManagement: 6 BGW
 SG_ nmPartialNetworks_BGW : 6|1@0+ (1,0) [0|1] ""  ACCL,DBPC,DCFL,DCFR,DCRL,DCRR,DSM,ECPM,FBCM,FFL,FLDC,FRDC,HLL,HLR,HUD,IHUB,LGL,PBPC,PSM,RCLL,RCLR,RLDC,RLSM,RRDC,RRSM
 SG_ nmActiveWake_BGW : 4|1@0+ (1,0) [0|1] ""  ACCL,DBPC,DCFL,DCFR,DCRL,DCRR,DSM,ECPM,FBCM,FFL,FLDC,FRDC,HLL,HLR,HUD,IHUB,LGL,PBPC,PSM,RCLL,RCLR,RLDC,RLSM,RRDC,RRSM
 SG_ nmID_BGW : 15|8@0+ (1,0) [0|31] ""  ACCL,DBPC,DCFL,DCFR,DCRL,DCRR,DSM,ECPM,FBCM,FFL,FLDC,FRDC,HLL,HLR,HUD,IHUB,LGL,PBPC,PSM,RCLL,RCLR,RLDC,RLSM,RRDC,RRSM
 SG_ nmPnBody_BGW : 19|1@0+ (1,0) [0|1] ""  ACCL,DBPC,DCFL,DCFR,DCRL,DCRR,DSM,ECPM,FBCM,FFL,FLDC,FRDC,HLL,HLR,HUD,IHUB,LGL,PBPC,PSM,RCLL,RCLR,RLDC,RLSM,RRDC,RRSM
 SG_ nmPnCharging_BGW : 18|1@0+ (1,0) [0|1] ""  FLDC,FRDC,RLDC,RRDC,FBCM
 SG_ nmPnHazard_BGW : 30|1@0+ (1,0) [0|1] ""  FBCM,HLL,HLR,RCLL,RCLR,IHUB,DCFL,DCFR
 SG_ nmPnKeypad_BGW : 29|1@0+ (1,0) [0|1] ""  DBPC

BO_ 2047 TOOL_UDSFunctionalRequest: 8 TOOL
 SG_ udsFunctionalRequestData_TOOL : 7|64@0+ (1,0) [0|1.84467E+019] ""  RRSM,RLSM,PSM,DSM

CM_ SG_ 1088 lighttemperatureStatus_HLL "Temp status (optional)";
CM_ SG_ 1088 lightDRLStatus_HLL "DRL status monitor";
CM_ SG_ 1088 lightLowBeamStatus_HLL "Low beam light status monitor";
CM_ SG_ 1088 lightPosStatus_HLL "Position light status monitor";
CM_ SG_ 1088 lightHighBeamStatus_HLL "High beam light status monitor";
CM_ SG_ 1088 lightTurnStatus_HLL "Turn status monitor, steady ON when requested";
CM_ SG_ 1096 lightDRLStatus_HLR "DRL status monitor";
CM_ SG_ 1096 lightLowBeamStatus_HLR "Low beam light status monitor";
CM_ SG_ 1096 lightHighBeamStatus_HLR "High beam light status monitor";
CM_ SG_ 1096 lighttemperatureStatus_HLR "Temp status (optional)";
CM_ SG_ 1096 lightPosStatus_HLR "Position light status monitor";
CM_ SG_ 1096 lightTurnStatus_HLR "Turn status monitor, steady ON when requested";
CM_ SG_ 680 doorLockReq_DCRL "Rear left door lock request";
CM_ SG_ 680 lockUnlockReq_RLLUS "Lock-Unlock Switch request";
CM_ SG_ 680 mirrorStatusMovUpDownLeft_DCRL "Front left mirror up/down movement status";
CM_ SG_ 680 mirrorStatusMovInOutLeft_DCRL "Front left mirror inwords/outwords movement status";
CM_ SG_ 680 mirrorDefrostCamStatusLeft_DCRL "Front left mirror camera defrost status";
CM_ SG_ 680 doorAngle_DCRL "Rear left door angle to the nearest 6 degrees";
CM_ SG_ 680 doorAngleMax_DCRL "Max door angle defined for Rear left door";
CM_ SG_ 681 windowReqAll_DCRL "All window request status";
CM_ SG_ 681 windowReqRearLeft_DCRL "Rear-Left window request status";
CM_ SG_ 681 windowReqRearRight_DCRL "Rear-Right window request status";
CM_ SG_ 681 windowReqFrontLeft_DCRL "Front-Left window request status";
CM_ SG_ 681 windowReqFrontRight_DCRL "Front-Right window request status";
CM_ SG_ 712 doorLockReq_DCRR "Rear right door lock request status";
CM_ SG_ 712 lockUnlockReq_RRLUS "Lock-Unlock Switch request";
CM_ SG_ 712 mirrorStatusMovUpDownRight_DCRR "Front right mirror up/down movement status";
CM_ SG_ 712 mirrorStatusMovInOutRight_DCRR "Front right mirror inwards/outwards movement status";
CM_ SG_ 712 mirrorDefrostCamStatusRight_DCRR "Front right mirror camera defrost status";
CM_ SG_ 712 doorAngle_DCRR "Rear right door angle to the nearest 6 degrees";
CM_ SG_ 712 doorAngleMax_DCRR "Max door angle defined for Rear right door";
CM_ SG_ 713 windowReqAll_DCRR "All window request status";
CM_ SG_ 713 windowReqRearLeft_DCRR "Rear-Left window request status";
CM_ SG_ 713 windowReqRearRight_DCRR "Rear-Right window request status";
CM_ SG_ 713 windowReqFrontLeft_DCRR "Front-Left window request status";
CM_ SG_ 713 windowReqFrontRight_DCRR "Front-Right window request status";
CM_ SG_ 1259 lightReverseStatus_LGL "Reverse lamp status";
CM_ SG_ 1259 lightSMarkerStatus_LGL "Rear side marker status monitor";
CM_ SG_ 1259 lightPosStatus_LGL "Liftgate position lamp status";
CM_ SG_ 1259 lighttemperatureStatus_LGL "Temp status (optional)";
CM_ SG_ 1273 lightTurnStatus_RCLL "Turn status monitor, steady ON when requested";
CM_ SG_ 1273 lightSMarkerStatus_RCLL "Rear side marker status monitor";
CM_ SG_ 1273 lightPosStatus_RCLL "Position light status monitor";
CM_ SG_ 1273 lighttemperatureStatus_RCLL "Temp status (optional)";
CM_ SG_ 1273 lightStopStatus_RCLL "Stop light status";
CM_ SG_ 1281 lightSMarkerStatus_RCLR "Rear side marker status monitor";
CM_ SG_ 1281 lightTurnStatus_RCLR "Turn status monitor, steady ON when requested";
CM_ SG_ 1281 lightPosStatus_RCLR "Position light status monitor";
CM_ SG_ 1281 lighttemperatureStatus_RCLR "Temp status (optional)";
CM_ SG_ 1281 lightStopStatus_RCLR "Stop status monitor";
CM_ SG_ 1290 seatMassageTypeCmdRR_BGW "Type of seat massage.";
CM_ SG_ 1290 seatMassageIntensityCmdRR_BGW "Desired intensity(speed) of massage.";
CM_ SG_ 1290 seatHeatVentCmdRR_BGW "Desired intesity of heating/cooling of seat.";
CM_ SG_ 1290 seatMassageTypeCmdRL_BGW "Type of seat massage.";
CM_ SG_ 1290 seatMassageIntensityCmdRL_BGW "Desired intensity(speed) of massage.";
CM_ SG_ 1290 seatHeatVentCmdRL_BGW "Desired intesity of heating/cooling of seat.";
CM_ SG_ 1290 seatMassageTypeCmdFR_BGW "Type of seat massage.";
CM_ SG_ 1290 seatMassageIntensityCmdFR_BGW "Desired intensity(speed) of massage.";
CM_ SG_ 1290 seatHeatVentCmdFR_BGW "Desired intesity of heating/cooling of seat.";
CM_ SG_ 1290 seatHeatVentCmdFL_BGW "Desired intesity of heating/cooling of seat.";
CM_ SG_ 1290 seatMassageIntensityCmdFL_BGW "Desired intensity(speed) of massage.";
CM_ SG_ 1290 seatMassageTypeCmdFL_BGW "Type of seat massage.";
CM_ SG_ 1298 lightPosStatus_ACCL "Position light status monitor";
CM_ SG_ 1328 doorLockReq_DBPC "Global Lock/Unlock Request";
CM_ SG_ 1553 nmPartialNetworks_FBCM "From AUTOSAR spec";
CM_ SG_ 1553 nmActiveWake_FBCM "From AUTOSAR spec";
CM_ SG_ 1553 nmID_FBCM "From AUTOSAR spec, the ECU ID of the ECU requesting the partial network";
CM_ SG_ 1553 nmPnBody_FBCM "FBCM request all devices on Body CAN to wake up";
CM_ SG_ 1553 nmPnCharging_FBCM "FBCM request battery domain to recharge 12V battery when using horns";
CM_ SG_ 1553 nmPnHazard_FBCM "FBCM request for ext func lighting and IPC for hazard lights";
CM_ SG_ 1553 nmPnBPG_FBCM "FBCM request for BPG to check 12V power level";
CM_ SG_ 1047 lightReverseOnReq_FBCM "Request to turn on reverse lights";
CM_ SG_ 1047 lightFogRearOnReq_FBCM "Request to turn on rear fog lights";
CM_ SG_ 1633 nmPartialNetworks_DCFL "From AUTOSAR spec";
CM_ SG_ 1633 nmActiveWake_DCFL "From AUTOSAR spec";
CM_ SG_ 1633 nmID_DCFL "From AUTOSAR spec, the ECU ID of the ECU requesting partial network";
CM_ SG_ 1633 nmPnBody_DCFL "DCM request all devices on Body CAN to wake up";
CM_ SG_ 1633 nmPnCharging_DCFL "DCM request battery recharge";
CM_ SG_ 1633 nmPnKeypad_DCFL "DCM request B-Pillar on ext switch press";
CM_ SG_ 1633 nmPnBPG_DCFL "DCM request BPG to check 12V power level";
CM_ SG_ 1673 nmPartialNetworks_DCFR "From AUTOSAR spec";
CM_ SG_ 1673 nmActiveWake_DCFR "From AUTOSAR spec";
CM_ SG_ 1673 nmID_DCFR "From AUTOSAR spec, the ECU ID of the ECU requesting partial network";
CM_ SG_ 1673 nmPnBody_DCFR "DCM request all devices on Body CAN to wake up";
CM_ SG_ 1673 nmPnCharging_DCFR "DCM request battery recharge";
CM_ SG_ 1673 nmPnKeypad_DCFR "DCM request B-Pillar on ext switch press";
CM_ SG_ 1673 nmPnBPG_DCFR "DCM request BPG to check 12V power level";
CM_ SG_ 1705 nmPartialNetworks_DCRL "From AUTOSAR spec";
CM_ SG_ 1705 nmActiveWake_DCRL "From AUTOSAR spec";
CM_ SG_ 1705 nmID_DCRL "From AUTOSAR spec, the ECU ID of the ECU requesting partial network";
CM_ SG_ 1705 nmPnBody_DCRL "DCM request all devices on Body CAN to wake up";
CM_ SG_ 1705 nmPnCharging_DCRL "DCM request battery recharge";
CM_ SG_ 1705 nmPnKeypad_DCRL "DCM request B-Pillar on ext switch press";
CM_ SG_ 1705 nmPnBPG_DCRL "DCM request BPG to check 12V power level";
CM_ SG_ 1737 nmPartialNetworks_DCRR "From AUTOSAR spec";
CM_ SG_ 1737 nmActiveWake_DCRR "From AUTOSAR spec";
CM_ SG_ 1737 nmID_DCRR "From AUTOSAR spec, the ECU ID of the ECU requesting partial network";
CM_ SG_ 1737 nmPnBody_DCRR "DCM request all devices on Body CAN to wake up";
CM_ SG_ 1737 nmPnCharging_DCRR "DCM request battery recharge";
CM_ SG_ 1737 nmPnKeypad_DCRR "DCM request B-Pillar on ext switch press";
CM_ SG_ 1737 nmPnBPG_DCRR "DCM request BPG to check 12V power level";
CM_ SG_ 2041 nmPartialNetworks_BGW "From AUTOSAR spec";
CM_ SG_ 2041 nmActiveWake_BGW "From AUTOSAR spec";
CM_ SG_ 2041 nmID_BGW "From AUTOSAR spec, the ECU ID of the ECU requesting the partial network";
CM_ SG_ 2041 nmPnBody_BGW "BGW request all devices on Body CAN to wake up";
CM_ SG_ 2041 nmPnCharging_BGW "BGW request ext aes lighting during charging";
CM_ SG_ 2041 nmPnHazard_BGW "BGW request for ext func lighting and IPC for hazard lights";
CM_ SG_ 2041 nmPnKeypad_BGW "BGW request B-Pillar Display to wake up";
BA_DEF_ BO_  "CloudLogRate" INT 0 65000;
BA_DEF_ SG_  "ExpirationValue" STRING ;
BA_DEF_ BO_  "MsgTxIsRx" INT 0 1;
BA_DEF_ BO_  "DebugMessage" INT 0 1;
BA_DEF_ BO_  "DebugMessageTransmitAlways" INT 0 1;
BA_DEF_ BO_  "DiagRequest" ENUM  "No","Yes";
BA_DEF_ BO_  "GatewayHandlerEnum" ENUM  "noHandler","uds","alertLog","messageLogOnReception","udsClient";
BA_DEF_ BO_  "GatewayMessageSendType" ENUM  "UseGenMsgSendType","onWrite","noAutoCode";
BA_DEF_ BO_  "GenMsgCycleTime" INT 0 65000;
BA_DEF_ BO_  "GenMsgGatewayNotification" STRING ;
BA_DEF_ BO_  "GenMsgILSupport" ENUM  "No","Yes";
BA_DEF_ BO_  "GenMsgMinAcceptLength" INT 0 0;
BA_DEF_ BO_  "GenMsgSendType" ENUM  "Cyclic","IfActive","NoMsgSendType","OnEvent";
BA_DEF_ BO_  "GenMsgTimeoutTime" INT 0 10000;
BA_DEF_ BO_  "Type" ENUM  "-","P","E","PE","vector_leerstring";
BA_DEF_ BO_  "cycleMilliSecs100" INT 0 100;
BA_DEF_ BO_  "receiveMsgFromEthernet" INT 0 1;
BA_DEF_ BO_  "sendMsgToEthernet" INT 0 1;
BA_DEF_ BO_  "targetGw" ENUM  "BPG","BGW","IHUB","SDCM","BGW,IHUB","BGW,BPG","BPG,IHUB","SDCM,IHUB","SDCM,BGW","SDCM,BPG","ALL","SDCM,ADC","IHUB,ADC","IHUB,BGW,ADC","ADC","ADC,BGW","SDCM,ADC,IHUB";
BA_DEF_ BO_  "targetMsgECUs" ENUM  "BPG","BGW","IVI","SDCM","ALL","vector_leerstring";
BA_DEF_ BO_  "transmitMsgRateEthernetMs" ENUM  "100","1000","0","10000","250","500","10","20","40","200","50";
BA_DEF_ SG_  "GatewayedSignal" INT 0 1;
BA_DEF_ SG_  "GenSigEnvVarType" ENUM  "int","float","undef";
BA_DEF_ SG_  "GenSigInactiveValue" INT 0 0;
BA_DEF_ SG_  "GenSigSNA" STRING ;
BA_DEF_ SG_  "GenSigSendType" ENUM  "Cyclic","OnWrite","OnWriteWithRepetition","OnChange","OnChangeWithRepetition","IfActive","IfActiveWithRepetition","NoSigSendType";
BA_DEF_ SG_  "GenSigStartValue" INT 0 0;
BA_DEF_ SG_  "OriginatingECU" STRING ;
BA_DEF_ SG_  "SNARequired" ENUM  "Required","NotRequired";
BA_DEF_DEF_  "CloudLogRate" 1000;
BA_DEF_DEF_  "ExpirationValue" "";
BA_DEF_DEF_  "MsgTxIsRx" 0;
BA_DEF_DEF_  "DebugMessage" 0;
BA_DEF_DEF_  "DebugMessageTransmitAlways" 0;
BA_DEF_DEF_  "DiagRequest" "No";
BA_DEF_DEF_  "GatewayHandlerEnum" "noHandler";
BA_DEF_DEF_  "GatewayMessageSendType" "UseGenMsgSendType";
BA_DEF_DEF_  "GenMsgCycleTime" 0;
BA_DEF_DEF_  "GenMsgGatewayNotification" "";
BA_DEF_DEF_  "GenMsgILSupport" "Yes";
BA_DEF_DEF_  "GenMsgMinAcceptLength" 8;
BA_DEF_DEF_  "GenMsgSendType" "NoMsgSendType";
BA_DEF_DEF_  "GenMsgTimeoutTime" 0;
BA_DEF_DEF_  "Type" "";
BA_DEF_DEF_  "cycleMilliSecs100" 100;
BA_DEF_DEF_  "receiveMsgFromEthernet" 0;
BA_DEF_DEF_  "sendMsgToEthernet" 0;
BA_DEF_DEF_  "targetGw" "ALL";
BA_DEF_DEF_  "targetMsgECUs" "";
BA_DEF_DEF_  "transmitMsgRateEthernetMs" "1000";
BA_DEF_DEF_  "GatewayedSignal" 0;
BA_DEF_DEF_  "GenSigEnvVarType" "undef";
BA_DEF_DEF_  "GenSigInactiveValue" 0;
BA_DEF_DEF_  "GenSigSNA" "";
BA_DEF_DEF_  "GenSigSendType" "NoSigSendType";
BA_DEF_DEF_  "GenSigStartValue" 0;
BA_DEF_DEF_  "OriginatingECU" "";
BA_DEF_DEF_  "SNARequired" "Required";
BA_ "GenMsgSendType" BO_ 1088 0;
BA_ "GenMsgCycleTime" BO_ 1088 100;
BA_ "sendMsgToEthernet" BO_ 1088 1;
BA_ "targetGw" BO_ 1088 7;
BA_ "transmitMsgRateEthernetMs" BO_ 1088 0;
BA_ "GenMsgSendType" BO_ 1096 0;
BA_ "GenMsgCycleTime" BO_ 1096 100;
BA_ "sendMsgToEthernet" BO_ 1096 1;
BA_ "targetGw" BO_ 1096 7;
BA_ "transmitMsgRateEthernetMs" BO_ 1096 0;
BA_ "sendMsgToEthernet" BO_ 680 1;
BA_ "GenMsgSendType" BO_ 680 0;
BA_ "GenMsgCycleTime" BO_ 680 250;
BA_ "MsgTxIsRx" BO_ 680 1;
BA_ "targetGw" BO_ 680 2;
BA_ "transmitMsgRateEthernetMs" BO_ 680 4;
BA_ "sendMsgToEthernet" BO_ 681 1;
BA_ "MsgTxIsRx" BO_ 681 1;
BA_ "targetGw" BO_ 681 2;
BA_ "transmitMsgRateEthernetMs" BO_ 681 2;
BA_ "sendMsgToEthernet" BO_ 712 1;
BA_ "GenMsgSendType" BO_ 712 0;
BA_ "GenMsgCycleTime" BO_ 712 250;
BA_ "MsgTxIsRx" BO_ 712 1;
BA_ "targetGw" BO_ 712 2;
BA_ "transmitMsgRateEthernetMs" BO_ 712 4;
BA_ "sendMsgToEthernet" BO_ 713 1;
BA_ "MsgTxIsRx" BO_ 713 1;
BA_ "targetGw" BO_ 713 2;
BA_ "transmitMsgRateEthernetMs" BO_ 713 2;
BA_ "GenMsgSendType" BO_ 1259 0;
BA_ "GenMsgCycleTime" BO_ 1259 1000;
BA_ "sendMsgToEthernet" BO_ 1259 1;
BA_ "targetGw" BO_ 1259 2;
BA_ "GenMsgSendType" BO_ 1273 0;
BA_ "GenMsgCycleTime" BO_ 1273 1000;
BA_ "sendMsgToEthernet" BO_ 1273 1;
BA_ "targetGw" BO_ 1273 2;
BA_ "GenMsgSendType" BO_ 1281 0;
BA_ "GenMsgCycleTime" BO_ 1281 1000;
BA_ "sendMsgToEthernet" BO_ 1281 1;
BA_ "targetGw" BO_ 1281 2;
BA_ "transmitMsgRateEthernetMs" BO_ 1290 2;
BA_ "Type" BO_ 1290 3;
BA_ "GenMsgTimeoutTime" BO_ 1290 2500;
BA_ "GenMsgSendType" BO_ 1298 0;
BA_ "GenMsgCycleTime" BO_ 1298 1000;
BA_ "GenMsgCycleTime" BO_ 1328 100;
BA_ "GenMsgSendType" BO_ 1328 0;
BA_ "sendMsgToEthernet" BO_ 1344 1;
BA_ "GenMsgSendType" BO_ 1344 0;
BA_ "GenMsgCycleTime" BO_ 1344 100;
BA_ "targetGw" BO_ 1344 2;
BA_ "transmitMsgRateEthernetMs" BO_ 1344 0;
BA_ "GenMsgSendType" BO_ 1352 0;
BA_ "GenMsgCycleTime" BO_ 1352 100;
BA_ "transmitMsgRateEthernetMs" BO_ 1352 0;
BA_ "GenMsgSendType" BO_ 1360 0;
BA_ "GenMsgCycleTime" BO_ 1360 100;
BA_ "transmitMsgRateEthernetMs" BO_ 1360 0;
BA_ "GenMsgSendType" BO_ 1368 0;
BA_ "GenMsgCycleTime" BO_ 1368 100;
BA_ "transmitMsgRateEthernetMs" BO_ 1368 0;
BA_ "GenMsgSendType" BO_ 1376 0;
BA_ "GenMsgCycleTime" BO_ 1376 100;
BA_ "transmitMsgRateEthernetMs" BO_ 1376 0;
BA_ "sendMsgToEthernet" BO_ 364 1;
BA_ "GenMsgSendType" BO_ 364 0;
BA_ "GenMsgCycleTime" BO_ 364 100;
BA_ "targetGw" BO_ 364 2;
BA_ "transmitMsgRateEthernetMs" BO_ 364 0;
BA_ "sendMsgToEthernet" BO_ 1166 1;
BA_ "GenMsgSendType" BO_ 1166 0;
BA_ "GenMsgCycleTime" BO_ 1166 1000;
BA_ "targetGw" BO_ 1166 2;
BA_ "sendMsgToEthernet" BO_ 1198 1;
BA_ "GenMsgSendType" BO_ 1198 0;
BA_ "GenMsgCycleTime" BO_ 1198 1000;
BA_ "targetGw" BO_ 1198 2;
BA_ "sendMsgToEthernet" BO_ 1230 1;
BA_ "GenMsgSendType" BO_ 1230 0;
BA_ "GenMsgCycleTime" BO_ 1230 1000;
BA_ "targetGw" BO_ 1230 2;
BA_ "transmitMsgRateEthernetMs" BO_ 1549 2;
BA_ "transmitMsgRateEthernetMs" BO_ 1550 2;
BA_ "GenMsgCycleTime" BO_ 1551 10000;
BA_ "GenMsgSendType" BO_ 1551 0;
BA_ "transmitMsgRateEthernetMs" BO_ 1551 3;
BA_ "sendMsgToEthernet" BO_ 1554 1;
BA_ "targetGw" BO_ 1554 2;
BA_ "GenMsgCycleTime" BO_ 1047 100;
BA_ "GenMsgSendType" BO_ 1047 0;
BA_ "sendMsgToEthernet" BO_ 1047 1;
BA_ "targetGw" BO_ 1047 2;
BA_ "transmitMsgRateEthernetMs" BO_ 1047 0;
BA_ "transmitMsgRateEthernetMs" BO_ 1557 2;
BA_ "transmitMsgRateEthernetMs" BO_ 1558 2;
BA_ "sendMsgToEthernet" BO_ 1559 1;
BA_ "GenMsgSendType" BO_ 1559 0;
BA_ "GenMsgCycleTime" BO_ 1559 10000;
BA_ "targetGw" BO_ 1559 2;
BA_ "transmitMsgRateEthernetMs" BO_ 1559 3;
BA_ "GenMsgCycleTime" BO_ 1607 10000;
BA_ "GenMsgSendType" BO_ 1607 0;
BA_ "sendMsgToEthernet" BO_ 1607 1;
BA_ "targetGw" BO_ 1607 2;
BA_ "transmitMsgRateEthernetMs" BO_ 1607 3;
BA_ "GenMsgCycleTime" BO_ 1615 10000;
BA_ "GenMsgSendType" BO_ 1615 0;
BA_ "sendMsgToEthernet" BO_ 1615 1;
BA_ "targetGw" BO_ 1615 2;
BA_ "transmitMsgRateEthernetMs" BO_ 1615 3;
BA_ "sendMsgToEthernet" BO_ 1634 1;
BA_ "targetGw" BO_ 1634 2;
BA_ "GenMsgCycleTime" BO_ 1639 10000;
BA_ "GenMsgSendType" BO_ 1639 0;
BA_ "sendMsgToEthernet" BO_ 1639 1;
BA_ "targetGw" BO_ 1639 2;
BA_ "transmitMsgRateEthernetMs" BO_ 1639 3;
BA_ "targetMsgECUs" BO_ 1650 5;
BA_ "GenMsgCycleTime" BO_ 1655 10000;
BA_ "GenMsgSendType" BO_ 1655 0;
BA_ "sendMsgToEthernet" BO_ 1655 1;
BA_ "targetGw" BO_ 1655 2;
BA_ "transmitMsgRateEthernetMs" BO_ 1655 3;
BA_ "sendMsgToEthernet" BO_ 1674 1;
BA_ "targetGw" BO_ 1674 2;
BA_ "GenMsgCycleTime" BO_ 1679 10000;
BA_ "GenMsgSendType" BO_ 1679 0;
BA_ "sendMsgToEthernet" BO_ 1679 1;
BA_ "targetGw" BO_ 1679 2;
BA_ "transmitMsgRateEthernetMs" BO_ 1679 3;
BA_ "targetMsgECUs" BO_ 1682 5;
BA_ "GenMsgCycleTime" BO_ 1687 10000;
BA_ "GenMsgSendType" BO_ 1687 0;
BA_ "sendMsgToEthernet" BO_ 1687 1;
BA_ "targetGw" BO_ 1687 2;
BA_ "transmitMsgRateEthernetMs" BO_ 1687 3;
BA_ "sendMsgToEthernet" BO_ 1706 1;
BA_ "targetGw" BO_ 1706 2;
BA_ "GenMsgCycleTime" BO_ 1711 10000;
BA_ "GenMsgSendType" BO_ 1711 0;
BA_ "sendMsgToEthernet" BO_ 1711 1;
BA_ "targetGw" BO_ 1711 2;
BA_ "transmitMsgRateEthernetMs" BO_ 1711 3;
BA_ "targetMsgECUs" BO_ 1714 5;
BA_ "GenMsgCycleTime" BO_ 1719 10000;
BA_ "GenMsgSendType" BO_ 1719 0;
BA_ "sendMsgToEthernet" BO_ 1719 1;
BA_ "targetGw" BO_ 1719 2;
BA_ "transmitMsgRateEthernetMs" BO_ 1719 3;
BA_ "sendMsgToEthernet" BO_ 1738 1;
BA_ "targetGw" BO_ 1738 2;
BA_ "GenMsgCycleTime" BO_ 1743 10000;
BA_ "GenMsgSendType" BO_ 1743 0;
BA_ "sendMsgToEthernet" BO_ 1743 1;
BA_ "targetGw" BO_ 1743 2;
BA_ "transmitMsgRateEthernetMs" BO_ 1743 3;
BA_ "targetMsgECUs" BO_ 1746 5;
BA_ "transmitMsgRateEthernetMs" BO_ 1746 2;
BA_ "GenMsgCycleTime" BO_ 1751 10000;
BA_ "GenMsgSendType" BO_ 1751 0;
BA_ "sendMsgToEthernet" BO_ 1751 1;
BA_ "targetGw" BO_ 1751 2;
BA_ "transmitMsgRateEthernetMs" BO_ 1751 3;
BA_ "GenMsgCycleTime" BO_ 1775 10000;
BA_ "GenMsgSendType" BO_ 1775 0;
BA_ "sendMsgToEthernet" BO_ 1775 1;
BA_ "targetGw" BO_ 1775 2;
BA_ "transmitMsgRateEthernetMs" BO_ 1775 3;
BA_ "GenMsgCycleTime" BO_ 1791 10000;
BA_ "GenMsgSendType" BO_ 1791 0;
BA_ "sendMsgToEthernet" BO_ 1791 1;
BA_ "targetGw" BO_ 1791 2;
BA_ "transmitMsgRateEthernetMs" BO_ 1791 3;
BA_ "GenMsgCycleTime" BO_ 1799 10000;
BA_ "GenMsgSendType" BO_ 1799 0;
BA_ "sendMsgToEthernet" BO_ 1799 1;
BA_ "targetGw" BO_ 1799 2;
BA_ "transmitMsgRateEthernetMs" BO_ 1799 3;
BA_ "GenMsgCycleTime" BO_ 1815 10000;
BA_ "GenMsgSendType" BO_ 1815 0;
BA_ "sendMsgToEthernet" BO_ 1815 1;
BA_ "targetGw" BO_ 1815 2;
BA_ "transmitMsgRateEthernetMs" BO_ 1815 3;
BA_ "GenMsgCycleTime" BO_ 1831 10000;
BA_ "GenMsgSendType" BO_ 1831 0;
BA_ "sendMsgToEthernet" BO_ 1831 1;
BA_ "targetGw" BO_ 1831 2;
BA_ "transmitMsgRateEthernetMs" BO_ 1831 3;
BA_ "GenMsgCycleTime" BO_ 1847 10000;
BA_ "GenMsgSendType" BO_ 1847 0;
BA_ "sendMsgToEthernet" BO_ 1847 1;
BA_ "targetGw" BO_ 1847 2;
BA_ "transmitMsgRateEthernetMs" BO_ 1847 3;
BA_ "GenMsgCycleTime" BO_ 1863 10000;
BA_ "GenMsgSendType" BO_ 1863 0;
BA_ "sendMsgToEthernet" BO_ 1863 1;
BA_ "targetGw" BO_ 1863 2;
BA_ "transmitMsgRateEthernetMs" BO_ 1863 3;
BA_ "GenMsgCycleTime" BO_ 1871 10000;
BA_ "GenMsgSendType" BO_ 1871 0;
BA_ "sendMsgToEthernet" BO_ 1871 1;
BA_ "targetGw" BO_ 1871 2;
BA_ "transmitMsgRateEthernetMs" BO_ 1871 3;
BA_ "GenMsgCycleTime" BO_ 1879 10000;
BA_ "GenMsgSendType" BO_ 1879 0;
BA_ "sendMsgToEthernet" BO_ 1879 1;
BA_ "targetGw" BO_ 1879 2;
BA_ "transmitMsgRateEthernetMs" BO_ 1879 3;
BA_ "transmitMsgRateEthernetMs" BO_ 1882 2;
BA_ "GenMsgCycleTime" BO_ 1887 10000;
BA_ "GenMsgSendType" BO_ 1887 0;
BA_ "sendMsgToEthernet" BO_ 1887 1;
BA_ "targetGw" BO_ 1887 2;
BA_ "transmitMsgRateEthernetMs" BO_ 1887 3;
BA_ "transmitMsgRateEthernetMs" BO_ 1890 2;
BA_ "GenMsgCycleTime" BO_ 1895 10000;
BA_ "GenMsgSendType" BO_ 1895 0;
BA_ "sendMsgToEthernet" BO_ 1895 1;
BA_ "targetGw" BO_ 1895 2;
BA_ "transmitMsgRateEthernetMs" BO_ 1895 3;
BA_ "transmitMsgRateEthernetMs" BO_ 2047 2;
BA_ "targetMsgECUs" BO_ 2047 5;
BA_ "Type" BO_ 2047 2;
BA_ "GenMsgGatewayNotification" BO_ 2047 "udsClientResponseHandler";
BA_ "GatewayHandlerEnum" BO_ 2047 4;
BA_ "DiagRequest" BO_ 2047 1;
BA_ "GatewayedSignal" SG_ 1088 lightLowBeamStatus_HLL 1;
BA_ "OriginatingECU" SG_ 1088 lightLowBeamStatus_HLL "HLL";
BA_ "GatewayedSignal" SG_ 1088 lightHighBeamStatus_HLL 1;
BA_ "OriginatingECU" SG_ 1088 lightHighBeamStatus_HLL "HLL";
BA_ "GatewayedSignal" SG_ 1088 lightTurnStatus_HLL 1;
BA_ "OriginatingECU" SG_ 1088 lightTurnStatus_HLL "HLL";
BA_ "GatewayedSignal" SG_ 1096 lightLowBeamStatus_HLR 1;
BA_ "OriginatingECU" SG_ 1096 lightLowBeamStatus_HLR "HLR";
BA_ "GatewayedSignal" SG_ 1096 lightHighBeamStatus_HLR 1;
BA_ "OriginatingECU" SG_ 1096 lightHighBeamStatus_HLR "HLR";
BA_ "GatewayedSignal" SG_ 1096 lightTurnStatus_HLR 1;
BA_ "OriginatingECU" SG_ 1096 lightTurnStatus_HLR "HLR";
BA_ "OriginatingECU" SG_ 680 lockUnlockReq_RLLUS "RLLUS";
BA_ "GatewayedSignal" SG_ 680 doorLatchFault_DCRL 1;
BA_ "OriginatingECU" SG_ 680 doorLatchFault_DCRL "DCRL";
BA_ "GatewayedSignal" SG_ 680 childLockButtonState_DCRL 1;
BA_ "OriginatingECU" SG_ 680 childLockButtonState_DCRL "DCRL";
BA_ "GatewayedSignal" SG_ 680 doorIsUnlatched_DCRL 1;
BA_ "OriginatingECU" SG_ 680 doorIsUnlatched_DCRL "DCRL";
BA_ "GatewayedSignal" SG_ 680 doorExtSwitch_DCRL 1;
BA_ "OriginatingECU" SG_ 680 doorExtSwitch_DCRL "DCRL";
BA_ "OriginatingECU" SG_ 680 doorState_DCRL "DCRL";
BA_ "GatewayedSignal" SG_ 680 doorState_DCRL 1;
BA_ "GatewayedSignal" SG_ 680 doorDTCPresent_DCRL 1;
BA_ "OriginatingECU" SG_ 680 doorDTCPresent_DCRL "DCRL";
BA_ "GatewayedSignal" SG_ 680 windowStatusRl_DCRL 1;
BA_ "OriginatingECU" SG_ 680 windowStatusRl_DCRL "DCRL";
BA_ "GatewayedSignal" SG_ 680 mirrorFoldFeedbackLeft_DCRL 1;
BA_ "OriginatingECU" SG_ 680 mirrorFoldFeedbackLeft_DCRL "DCRL";
BA_ "GatewayedSignal" SG_ 680 mirrorDefrostGlassStatusLh_DCRL 1;
BA_ "OriginatingECU" SG_ 680 mirrorDefrostGlassStatusLh_DCRL "DCRL";
BA_ "GatewayedSignal" SG_ 680 mirrorStatusMovUpDownLeft_DCRL 1;
BA_ "OriginatingECU" SG_ 680 mirrorStatusMovUpDownLeft_DCRL "DCRL";
BA_ "GatewayedSignal" SG_ 680 mirrorStatusMovInOutLeft_DCRL 1;
BA_ "OriginatingECU" SG_ 680 mirrorStatusMovInOutLeft_DCRL "DCRL";
BA_ "GatewayedSignal" SG_ 680 mirrorDefrostCamStatusLeft_DCRL 1;
BA_ "OriginatingECU" SG_ 680 mirrorDefrostCamStatusLeft_DCRL "DCRL";
BA_ "GatewayedSignal" SG_ 680 errorAMPRL_DCRL 1;
BA_ "OriginatingECU" SG_ 680 errorAMPRL_DCRL "DCRL";
BA_ "GatewayedSignal" SG_ 680 errorALDRL_DCRL 1;
BA_ "OriginatingECU" SG_ 680 errorALDRL_DCRL "DCRL";
BA_ "GatewayedSignal" SG_ 680 doorAngle_DCRL 1;
BA_ "OriginatingECU" SG_ 680 doorAngle_DCRL "DCRL";
BA_ "GenSigStartValue" SG_ 680 doorAngle_DCRL -20;
BA_ "GatewayedSignal" SG_ 680 doorAngleMax_DCRL 1;
BA_ "OriginatingECU" SG_ 680 doorAngleMax_DCRL "DCRL";
BA_ "GenSigSendType" SG_ 681 windowReqAll_DCRL 1;
BA_ "GenSigSendType" SG_ 681 windowLock_DCRL 1;
BA_ "SNARequired" SG_ 681 windowLock_DCRL 1;
BA_ "GenSigSendType" SG_ 681 allDoorsLock_DCRL 1;
BA_ "SNARequired" SG_ 681 allDoorsLock_DCRL 1;
BA_ "GenSigSendType" SG_ 681 allDoorsUnlock_DCRL 1;
BA_ "SNARequired" SG_ 681 allDoorsUnlock_DCRL 1;
BA_ "OriginatingECU" SG_ 681 windowReqRearLeft_DCRL "DCRL";
BA_ "GatewayedSignal" SG_ 681 windowReqRearLeft_DCRL 1;
BA_ "GenSigSendType" SG_ 681 windowReqRearLeft_DCRL 1;
BA_ "GenSigSendType" SG_ 681 windowReqRearRight_DCRL 1;
BA_ "GenSigSendType" SG_ 681 nothingPressed_DCRL 1;
BA_ "SNARequired" SG_ 681 nothingPressed_DCRL 1;
BA_ "GenSigSendType" SG_ 681 buttonPressed_DCRL 1;
BA_ "SNARequired" SG_ 681 buttonPressed_DCRL 1;
BA_ "GenSigSendType" SG_ 681 windowReqFrontLeft_DCRL 1;
BA_ "OriginatingECU" SG_ 681 windowReqFrontRight_DCRL "DCRL";
BA_ "GenSigSendType" SG_ 681 windowReqFrontRight_DCRL 1;
BA_ "GenSigSendType" SG_ 681 mirrorUp_DCRL 1;
BA_ "SNARequired" SG_ 681 mirrorUp_DCRL 1;
BA_ "OriginatingECU" SG_ 712 lockUnlockReq_RRLUS "RRLUS";
BA_ "GatewayedSignal" SG_ 712 doorLatchFault_DCRR 1;
BA_ "OriginatingECU" SG_ 712 doorLatchFault_DCRR "DCRR";
BA_ "GatewayedSignal" SG_ 712 childLockButtonState_DCRR 1;
BA_ "OriginatingECU" SG_ 712 childLockButtonState_DCRR "DCRR";
BA_ "GatewayedSignal" SG_ 712 doorIsUnlatched_DCRR 1;
BA_ "OriginatingECU" SG_ 712 doorIsUnlatched_DCRR "DCRR";
BA_ "OriginatingECU" SG_ 712 doorExtSwitch_DCRR "DCRR";
BA_ "GatewayedSignal" SG_ 712 doorExtSwitch_DCRR 1;
BA_ "OriginatingECU" SG_ 712 doorState_DCRR "DCRR";
BA_ "GatewayedSignal" SG_ 712 doorState_DCRR 1;
BA_ "OriginatingECU" SG_ 712 doorDTCPresent_DCRR "DCRR";
BA_ "GatewayedSignal" SG_ 712 doorDTCPresent_DCRR 1;
BA_ "GatewayedSignal" SG_ 712 windowStatusRr_DCRR 1;
BA_ "OriginatingECU" SG_ 712 windowStatusRr_DCRR "DCRR";
BA_ "GatewayedSignal" SG_ 712 mirrorFoldFeedbackRight_DCRR 1;
BA_ "OriginatingECU" SG_ 712 mirrorFoldFeedbackRight_DCRR "DCRR";
BA_ "GatewayedSignal" SG_ 712 mirrorDefrostGlassStatusRh_DCRR 1;
BA_ "OriginatingECU" SG_ 712 mirrorDefrostGlassStatusRh_DCRR "DCRR";
BA_ "GatewayedSignal" SG_ 712 mirrorStatusMovUpDownRight_DCRR 1;
BA_ "OriginatingECU" SG_ 712 mirrorStatusMovUpDownRight_DCRR "DCRR";
BA_ "GatewayedSignal" SG_ 712 mirrorStatusMovInOutRight_DCRR 1;
BA_ "OriginatingECU" SG_ 712 mirrorStatusMovInOutRight_DCRR "DCRR";
BA_ "GatewayedSignal" SG_ 712 mirrorDefrostCamStatusRight_DCRR 1;
BA_ "OriginatingECU" SG_ 712 mirrorDefrostCamStatusRight_DCRR "DCRR";
BA_ "GatewayedSignal" SG_ 712 errorAMPRR_DCRR 1;
BA_ "OriginatingECU" SG_ 712 errorAMPRR_DCRR "DCRR";
BA_ "GatewayedSignal" SG_ 712 errorALDRR_DCRR 1;
BA_ "OriginatingECU" SG_ 712 errorALDRR_DCRR "DCRR";
BA_ "GatewayedSignal" SG_ 712 doorAngle_DCRR 1;
BA_ "OriginatingECU" SG_ 712 doorAngle_DCRR "DCRR";
BA_ "GenSigStartValue" SG_ 712 doorAngle_DCRR -20;
BA_ "GatewayedSignal" SG_ 712 doorAngleMax_DCRR 1;
BA_ "OriginatingECU" SG_ 712 doorAngleMax_DCRR "DCRR";
BA_ "GenSigSendType" SG_ 713 windowReqAll_DCRR 1;
BA_ "GenSigSendType" SG_ 713 windowLock_DCRR 1;
BA_ "SNARequired" SG_ 713 windowLock_DCRR 1;
BA_ "GenSigSendType" SG_ 713 allDoorsLock_DCRR 1;
BA_ "SNARequired" SG_ 713 allDoorsLock_DCRR 1;
BA_ "GenSigSendType" SG_ 713 allDoorsUnlock_DCRR 1;
BA_ "SNARequired" SG_ 713 allDoorsUnlock_DCRR 1;
BA_ "GenSigSendType" SG_ 713 windowReqRearLeft_DCRR 1;
BA_ "OriginatingECU" SG_ 713 windowReqRearRight_DCRR "DCRR";
BA_ "GatewayedSignal" SG_ 713 windowReqRearRight_DCRR 1;
BA_ "GenSigSendType" SG_ 713 windowReqRearRight_DCRR 1;
BA_ "GenSigSendType" SG_ 713 nothingPressed_DCRR 1;
BA_ "SNARequired" SG_ 713 nothingPressed_DCRR 1;
BA_ "GenSigSendType" SG_ 713 buttonPressed_DCRR 1;
BA_ "SNARequired" SG_ 713 buttonPressed_DCRR 1;
BA_ "GenSigSendType" SG_ 713 windowReqFrontLeft_DCRR 1;
BA_ "OriginatingECU" SG_ 713 windowReqFrontRight_DCRR "DCRR";
BA_ "SNARequired" SG_ 713 windowReqFrontRight_DCRR 1;
BA_ "GenSigSendType" SG_ 713 windowReqFrontRight_DCRR 1;
BA_ "GenSigSendType" SG_ 713 mirrorUp_DCRR 1;
BA_ "SNARequired" SG_ 713 mirrorUp_DCRR 1;
BA_ "GatewayedSignal" SG_ 1259 lighttemperatureStatus_LGL 1;
BA_ "OriginatingECU" SG_ 1259 lighttemperatureStatus_LGL "LGL";
BA_ "GatewayedSignal" SG_ 1273 lightTurnStatus_RCLL 1;
BA_ "OriginatingECU" SG_ 1273 lightTurnStatus_RCLL "RCLL";
BA_ "GatewayedSignal" SG_ 1273 lightStopStatus_RCLL 1;
BA_ "OriginatingECU" SG_ 1273 lightStopStatus_RCLL "RCLL";
BA_ "GatewayedSignal" SG_ 1281 lightTurnStatus_RCLR 1;
BA_ "OriginatingECU" SG_ 1281 lightTurnStatus_RCLR "RCLR";
BA_ "GatewayedSignal" SG_ 1281 lightStopStatus_RCLR 1;
BA_ "OriginatingECU" SG_ 1281 lightStopStatus_RCLR "RCLR";
BA_ "GenSigSendType" SG_ 1290 seatCushionMassageCmdRL_BGW 1;
BA_ "GenSigSendType" SG_ 1290 seatCushionMassageCmdRR_BGW 1;
BA_ "GenSigSendType" SG_ 1290 seatBackMassageCmdRR_BGW 1;
BA_ "GenSigSendType" SG_ 1290 seatBackMassageCmdRL_BGW 1;
BA_ "GenSigSendType" SG_ 1290 seatCushionMassageCmdFR_BGW 1;
BA_ "GenSigSendType" SG_ 1290 seatBackMassageCmdFR_BGW 1;
BA_ "GenSigSendType" SG_ 1290 seatCushionMassageCmdFL_BGW 1;
BA_ "GenSigSendType" SG_ 1290 seatBackMassageCmdFL_BGW 1;
BA_ "GenSigSendType" SG_ 1290 seatMassageTypeCmdRR_BGW 1;
BA_ "GenSigSendType" SG_ 1290 seatMassageIntensityCmdRR_BGW 1;
BA_ "GenSigSendType" SG_ 1290 seatHeatVentCmdRR_BGW 1;
BA_ "GenSigSendType" SG_ 1290 seatMassageTypeCmdRL_BGW 1;
BA_ "GenSigSendType" SG_ 1290 seatMassageIntensityCmdRL_BGW 1;
BA_ "GenSigSendType" SG_ 1290 seatHeatVentCmdRL_BGW 1;
BA_ "GenSigSendType" SG_ 1290 seatMassageTypeCmdFR_BGW 1;
BA_ "GenSigSendType" SG_ 1290 seatMassageIntensityCmdFR_BGW 1;
BA_ "GenSigSendType" SG_ 1290 seatHeatVentCmdFR_BGW 1;
BA_ "GenSigSendType" SG_ 1290 seatHeatVentCmdFL_BGW 1;
BA_ "GenSigSendType" SG_ 1290 seatMassageIntensityCmdFL_BGW 1;
BA_ "GenSigSendType" SG_ 1290 seatMassageTypeCmdFL_BGW 1;
BA_ "GatewayedSignal" SG_ 1344 sequenceStatus_FFL 1;
BA_ "OriginatingECU" SG_ 1344 sequenceStatus_FFL "FFL";
BA_ "GatewayedSignal" SG_ 1344 brightnessStatus_FFL 1;
BA_ "OriginatingECU" SG_ 1344 brightnessStatus_FFL "FFL";
BA_ "GatewayedSignal" SG_ 1344 sequenceIDStatus_FFL 1;
BA_ "OriginatingECU" SG_ 1344 sequenceIDStatus_FFL "FFL";
BA_ "GatewayedSignal" SG_ 364 switchStatusLeft_DOMEF 1;
BA_ "OriginatingECU" SG_ 364 switchStatusLeft_DOMEF "DOMEF";
BA_ "GatewayedSignal" SG_ 364 switchStatusCenter_DOMEF 1;
BA_ "OriginatingECU" SG_ 364 switchStatusCenter_DOMEF "DOMEF";
BA_ "GatewayedSignal" SG_ 364 switchStatusRight_DOMEF 1;
BA_ "OriginatingECU" SG_ 364 switchStatusRight_DOMEF "DOMEF";
BA_ "GatewayedSignal" SG_ 364 lightStatusLeft_DOMEF 1;
BA_ "OriginatingECU" SG_ 364 lightStatusLeft_DOMEF "DOMEF";
BA_ "GatewayedSignal" SG_ 364 lightStatusCenter_DOMEF 1;
BA_ "OriginatingECU" SG_ 364 lightStatusCenter_DOMEF "DOMEF";
BA_ "GatewayedSignal" SG_ 364 lightStatusRight_DOMEF 1;
BA_ "OriginatingECU" SG_ 364 lightStatusRight_DOMEF "DOMEF";
BA_ "GatewayedSignal" SG_ 364 error_DOMEF 1;
BA_ "OriginatingECU" SG_ 364 error_DOMEF "DOMEF";
BA_ "GatewayedSignal" SG_ 364 switchStatus_DOMER 1;
BA_ "OriginatingECU" SG_ 364 switchStatus_DOMER "DOMER";
BA_ "GatewayedSignal" SG_ 364 lightStatus_DOMER 1;
BA_ "OriginatingECU" SG_ 364 lightStatus_DOMER "DOMER";
BA_ "GatewayedSignal" SG_ 364 error_DOMER 1;
BA_ "OriginatingECU" SG_ 364 error_DOMER "DOMER";
BA_ "GatewayedSignal" SG_ 1166 redStatusAMPFR_DCFR 1;
BA_ "OriginatingECU" SG_ 1166 redStatusAMPFR_DCFR "DCFR";
BA_ "GatewayedSignal" SG_ 1166 greenStatusAMPFR_DCFR 1;
BA_ "OriginatingECU" SG_ 1166 greenStatusAMPFR_DCFR "DCFR";
BA_ "GatewayedSignal" SG_ 1166 blueStatusAMPFR_DCFR 1;
BA_ "OriginatingECU" SG_ 1166 blueStatusAMPFR_DCFR "DCFR";
BA_ "GatewayedSignal" SG_ 1166 routineStatusAMPFR_DCFR 1;
BA_ "OriginatingECU" SG_ 1166 routineStatusAMPFR_DCFR "DCFR";
BA_ "GatewayedSignal" SG_ 1166 redStatusALDFR_DCFR 1;
BA_ "OriginatingECU" SG_ 1166 redStatusALDFR_DCFR "DCFR";
BA_ "GatewayedSignal" SG_ 1166 greenStatusALDFR_DCFR 1;
BA_ "OriginatingECU" SG_ 1166 greenStatusALDFR_DCFR "DCFR";
BA_ "GatewayedSignal" SG_ 1166 blueStatusALDFR_DCFR 1;
BA_ "OriginatingECU" SG_ 1166 blueStatusALDFR_DCFR "DCFR";
BA_ "GatewayedSignal" SG_ 1166 routineStatusALDFR_DCFR 1;
BA_ "OriginatingECU" SG_ 1166 routineStatusALDFR_DCFR "DCFR";
BA_ "GatewayedSignal" SG_ 1198 redStatusAMPRL_DCRL 1;
BA_ "OriginatingECU" SG_ 1198 redStatusAMPRL_DCRL "DCRL";
BA_ "GatewayedSignal" SG_ 1198 greenStatusAMPRL_DCRL 1;
BA_ "OriginatingECU" SG_ 1198 greenStatusAMPRL_DCRL "DCRL";
BA_ "GatewayedSignal" SG_ 1198 blueStatusAMPRL_DCRL 1;
BA_ "OriginatingECU" SG_ 1198 blueStatusAMPRL_DCRL "DCRL";
BA_ "GatewayedSignal" SG_ 1198 routineStatusAMPRL_DCRL 1;
BA_ "OriginatingECU" SG_ 1198 routineStatusAMPRL_DCRL "DCRL";
BA_ "GatewayedSignal" SG_ 1198 redStatusALDRL_DCRL 1;
BA_ "OriginatingECU" SG_ 1198 redStatusALDRL_DCRL "DCRL";
BA_ "GatewayedSignal" SG_ 1198 greenStatusALDRL_DCRL 1;
BA_ "OriginatingECU" SG_ 1198 greenStatusALDRL_DCRL "DCRL";
BA_ "GatewayedSignal" SG_ 1198 blueStatusALDRL_DCRL 1;
BA_ "OriginatingECU" SG_ 1198 blueStatusALDRL_DCRL "DCRL";
BA_ "GatewayedSignal" SG_ 1198 routineStatusALDRL_DCRL 1;
BA_ "OriginatingECU" SG_ 1198 routineStatusALDRL_DCRL "DCRL";
BA_ "GatewayedSignal" SG_ 1230 redStatusAMPRR_DCRR 1;
BA_ "OriginatingECU" SG_ 1230 redStatusAMPRR_DCRR "DCRR";
BA_ "GatewayedSignal" SG_ 1230 greenStatusAMPRR_DCRR 1;
BA_ "OriginatingECU" SG_ 1230 greenStatusAMPRR_DCRR "DCRR";
BA_ "GatewayedSignal" SG_ 1230 blueStatusAMPRR_DCRR 1;
BA_ "OriginatingECU" SG_ 1230 blueStatusAMPRR_DCRR "DCRR";
BA_ "GatewayedSignal" SG_ 1230 routineStatusAMPRR_DCRR 1;
BA_ "OriginatingECU" SG_ 1230 routineStatusAMPRR_DCRR "DCRR";
BA_ "GatewayedSignal" SG_ 1230 redStatusALDRR_DCRR 1;
BA_ "OriginatingECU" SG_ 1230 redStatusALDRR_DCRR "DCRR";
BA_ "GatewayedSignal" SG_ 1230 greenStatusALDRR_DCRR 1;
BA_ "OriginatingECU" SG_ 1230 greenStatusALDRR_DCRR "DCRR";
BA_ "GatewayedSignal" SG_ 1230 blueStatusALDRR_DCRR 1;
BA_ "OriginatingECU" SG_ 1230 blueStatusALDRR_DCRR "DCRR";
BA_ "GatewayedSignal" SG_ 1230 routineStatusALDRR_DCRR 1;
BA_ "OriginatingECU" SG_ 1230 routineStatusALDRR_DCRR "DCRR";
BA_ "GenSigSendType" SG_ 1546 hardwarePartNumber_BGW 1;
BA_ "GenSigSendType" SG_ 1546 hardwareRevisionId_BGW 1;
BA_ "GenSigSendType" SG_ 1546 bootloaderStuckSignal_BGW 1;
BA_ "GenSigSendType" SG_ 1546 resetCause_BGW 1;
BA_ "SNARequired" SG_ 1551 idGitHashUpper_BGW 1;
BA_ "SNARequired" SG_ 1551 idBootGitHashUpper_BGW 1;
BA_ "SNARequired" SG_ 1551 idCalGitHashUpper_BGW 1;
BA_ "GenSigSendType" SG_ 1553 nmPartialNetworks_FBCM 1;
BA_ "GenSigSendType" SG_ 1553 nmActiveWake_FBCM 1;
BA_ "GenSigSendType" SG_ 1553 nmID_FBCM 1;
BA_ "GenSigSendType" SG_ 1553 nmPnBody_FBCM 1;
BA_ "GenSigSendType" SG_ 1553 nmPnCharging_FBCM 1;
BA_ "GenSigSendType" SG_ 1553 nmPnHazard_FBCM 1;
BA_ "GenSigSendType" SG_ 1553 nmPnBPG_FBCM 1;
BA_ "GenSigSendType" SG_ 1554 hardwarePartNumber_FBCM 1;
BA_ "GenSigSendType" SG_ 1554 hardwareRevisionId_FBCM 1;
BA_ "GenSigSendType" SG_ 1554 bootloaderStuckSignal_FBCM 1;
BA_ "OriginatingECU" SG_ 1554 resetCause_FBCM "FBCM";
BA_ "GatewayedSignal" SG_ 1554 resetCause_FBCM 1;
BA_ "GenSigSendType" SG_ 1554 resetCause_FBCM 1;
BA_ "OriginatingECU" SG_ 1047 lvlrequestlowbeam_FBCM "FBCM";
BA_ "OriginatingECU" SG_ 1047 lightReverseOnReq_FBCM "FBCM";
BA_ "GatewayedSignal" SG_ 1047 lightReverseOnReq_FBCM 1;
BA_ "OriginatingECU" SG_ 1047 lightFogRearOnReq_FBCM "FBCM";
BA_ "GatewayedSignal" SG_ 1047 lightFogRearOnReq_FBCM 1;
BA_ "SNARequired" SG_ 1557 udsClientDataFBCM_TOOL 1;
BA_ "GenSigSendType" SG_ 1557 udsClientDataFBCM_TOOL 1;
BA_ "SNARequired" SG_ 1558 udsServerData_FBCM 1;
BA_ "GenSigSendType" SG_ 1558 udsServerData_FBCM 1;
BA_ "GatewayedSignal" SG_ 1559 versionCalSubMinor_FBCM 1;
BA_ "OriginatingECU" SG_ 1559 versionCalSubMinor_FBCM "FBCM";
BA_ "GatewayedSignal" SG_ 1559 versionCalReleaseCandidate_FBCM 1;
BA_ "OriginatingECU" SG_ 1559 versionCalReleaseCandidate_FBCM "FBCM";
BA_ "GatewayedSignal" SG_ 1559 versionCalMinor_FBCM 1;
BA_ "OriginatingECU" SG_ 1559 versionCalMinor_FBCM "FBCM";
BA_ "GatewayedSignal" SG_ 1559 versionCalMajor_FBCM 1;
BA_ "OriginatingECU" SG_ 1559 versionCalMajor_FBCM "FBCM";
BA_ "GatewayedSignal" SG_ 1559 idCalGitHashUpper_FBCM 1;
BA_ "OriginatingECU" SG_ 1559 idCalGitHashUpper_FBCM "FBCM";
BA_ "GatewayedSignal" SG_ 1559 idCalBuildMachine_FBCM 1;
BA_ "OriginatingECU" SG_ 1559 idCalBuildMachine_FBCM "FBCM";
BA_ "GatewayedSignal" SG_ 1559 versionReleaseCandidate_FBCM 1;
BA_ "OriginatingECU" SG_ 1559 versionReleaseCandidate_FBCM "FBCM";
BA_ "GatewayedSignal" SG_ 1559 versionBootReleaseCandidate_FBCM 1;
BA_ "OriginatingECU" SG_ 1559 versionBootReleaseCandidate_FBCM "FBCM";
BA_ "GatewayedSignal" SG_ 1559 componentNum_FBCM 1;
BA_ "OriginatingECU" SG_ 1559 componentNum_FBCM "FBCM";
BA_ "GatewayedSignal" SG_ 1559 idGitHashUpper_FBCM 1;
BA_ "OriginatingECU" SG_ 1559 idGitHashUpper_FBCM "FBCM";
BA_ "GatewayedSignal" SG_ 1559 idBootGitHashUpper_FBCM 1;
BA_ "OriginatingECU" SG_ 1559 idBootGitHashUpper_FBCM "FBCM";
BA_ "GatewayedSignal" SG_ 1559 idBuildMachine_FBCM 1;
BA_ "OriginatingECU" SG_ 1559 idBuildMachine_FBCM "FBCM";
BA_ "GatewayedSignal" SG_ 1559 versionSubMinor_FBCM 1;
BA_ "OriginatingECU" SG_ 1559 versionSubMinor_FBCM "FBCM";
BA_ "GatewayedSignal" SG_ 1559 versionMinor_FBCM 1;
BA_ "OriginatingECU" SG_ 1559 versionMinor_FBCM "FBCM";
BA_ "GatewayedSignal" SG_ 1559 versionMajor_FBCM 1;
BA_ "OriginatingECU" SG_ 1559 versionMajor_FBCM "FBCM";
BA_ "GatewayedSignal" SG_ 1559 idBootBuildMachine_FBCM 1;
BA_ "OriginatingECU" SG_ 1559 idBootBuildMachine_FBCM "FBCM";
BA_ "GatewayedSignal" SG_ 1559 versionBootSubMinor_FBCM 1;
BA_ "OriginatingECU" SG_ 1559 versionBootSubMinor_FBCM "FBCM";
BA_ "GatewayedSignal" SG_ 1559 versionBootMinor_FBCM 1;
BA_ "OriginatingECU" SG_ 1559 versionBootMinor_FBCM "FBCM";
BA_ "GatewayedSignal" SG_ 1559 versionBootMajor_FBCM 1;
BA_ "OriginatingECU" SG_ 1559 versionBootMajor_FBCM "FBCM";
BA_ "GenSigSendType" SG_ 1602 hardwarePartNumber_HLL 1;
BA_ "GenSigSendType" SG_ 1602 hardwareRevisionId_HLL 1;
BA_ "GenSigSendType" SG_ 1602 bootloaderStuckSignal_HLL 1;
BA_ "GenSigSendType" SG_ 1602 resetCause_HLL 1;
BA_ "SNARequired" SG_ 1605 udsClientDataHLL_TOOL 1;
BA_ "GenSigSendType" SG_ 1605 udsClientDataHLL_TOOL 1;
BA_ "SNARequired" SG_ 1606 udsServerData_HLL 1;
BA_ "GenSigSendType" SG_ 1606 udsServerData_HLL 1;
BA_ "GatewayedSignal" SG_ 1607 versionReleaseCandidate_HLL 1;
BA_ "OriginatingECU" SG_ 1607 versionReleaseCandidate_HLL "HLL";
BA_ "GatewayedSignal" SG_ 1607 versionBootReleaseCandidate_HLL 1;
BA_ "OriginatingECU" SG_ 1607 versionBootReleaseCandidate_HLL "HLL";
BA_ "GatewayedSignal" SG_ 1607 componentNum_HLL 1;
BA_ "OriginatingECU" SG_ 1607 componentNum_HLL "HLL";
BA_ "GatewayedSignal" SG_ 1607 idGitHashUpper_HLL 1;
BA_ "OriginatingECU" SG_ 1607 idGitHashUpper_HLL "HLL";
BA_ "GatewayedSignal" SG_ 1607 idBootGitHashUpper_HLL 1;
BA_ "OriginatingECU" SG_ 1607 idBootGitHashUpper_HLL "HLL";
BA_ "GatewayedSignal" SG_ 1607 idBuildMachine_HLL 1;
BA_ "OriginatingECU" SG_ 1607 idBuildMachine_HLL "HLL";
BA_ "GatewayedSignal" SG_ 1607 versionSubMinor_HLL 1;
BA_ "OriginatingECU" SG_ 1607 versionSubMinor_HLL "HLL";
BA_ "GatewayedSignal" SG_ 1607 versionMinor_HLL 1;
BA_ "OriginatingECU" SG_ 1607 versionMinor_HLL "HLL";
BA_ "GatewayedSignal" SG_ 1607 versionMajor_HLL 1;
BA_ "OriginatingECU" SG_ 1607 versionMajor_HLL "HLL";
BA_ "GatewayedSignal" SG_ 1607 idBootBuildMachine_HLL 1;
BA_ "OriginatingECU" SG_ 1607 idBootBuildMachine_HLL "HLL";
BA_ "GatewayedSignal" SG_ 1607 versionBootSubMinor_HLL 1;
BA_ "OriginatingECU" SG_ 1607 versionBootSubMinor_HLL "HLL";
BA_ "GatewayedSignal" SG_ 1607 versionBootMinor_HLL 1;
BA_ "OriginatingECU" SG_ 1607 versionBootMinor_HLL "HLL";
BA_ "GatewayedSignal" SG_ 1607 versionBootMajor_HLL 1;
BA_ "OriginatingECU" SG_ 1607 versionBootMajor_HLL "HLL";
BA_ "GenSigSendType" SG_ 1610 hardwarePartNumber_HLR 1;
BA_ "GenSigSendType" SG_ 1610 hardwareRevisionId_HLR 1;
BA_ "GenSigSendType" SG_ 1610 bootloaderStuckSignal_HLR 1;
BA_ "GenSigSendType" SG_ 1610 resetCause_HLR 1;
BA_ "SNARequired" SG_ 1613 udsClientDataHLR_TOOL 1;
BA_ "GenSigSendType" SG_ 1613 udsClientDataHLR_TOOL 1;
BA_ "SNARequired" SG_ 1614 udsServerData_HLR 1;
BA_ "GenSigSendType" SG_ 1614 udsServerData_HLR 1;
BA_ "GatewayedSignal" SG_ 1615 versionReleaseCandidate_HLR 1;
BA_ "OriginatingECU" SG_ 1615 versionReleaseCandidate_HLR "HLR";
BA_ "GatewayedSignal" SG_ 1615 versionBootReleaseCandidate_HLR 1;
BA_ "OriginatingECU" SG_ 1615 versionBootReleaseCandidate_HLR "HLR";
BA_ "GatewayedSignal" SG_ 1615 componentNum_HLR 1;
BA_ "OriginatingECU" SG_ 1615 componentNum_HLR "HLR";
BA_ "GatewayedSignal" SG_ 1615 idGitHashUpper_HLR 1;
BA_ "OriginatingECU" SG_ 1615 idGitHashUpper_HLR "HLR";
BA_ "GatewayedSignal" SG_ 1615 idBootGitHashUpper_HLR 1;
BA_ "OriginatingECU" SG_ 1615 idBootGitHashUpper_HLR "HLR";
BA_ "GatewayedSignal" SG_ 1615 idBuildMachine_HLR 1;
BA_ "OriginatingECU" SG_ 1615 idBuildMachine_HLR "HLR";
BA_ "GatewayedSignal" SG_ 1615 versionSubMinor_HLR 1;
BA_ "OriginatingECU" SG_ 1615 versionSubMinor_HLR "HLR";
BA_ "GatewayedSignal" SG_ 1615 versionMinor_HLR 1;
BA_ "OriginatingECU" SG_ 1615 versionMinor_HLR "HLR";
BA_ "GatewayedSignal" SG_ 1615 versionMajor_HLR 1;
BA_ "OriginatingECU" SG_ 1615 versionMajor_HLR "HLR";
BA_ "GatewayedSignal" SG_ 1615 idBootBuildMachine_HLR 1;
BA_ "OriginatingECU" SG_ 1615 idBootBuildMachine_HLR "HLR";
BA_ "GatewayedSignal" SG_ 1615 versionBootSubMinor_HLR 1;
BA_ "OriginatingECU" SG_ 1615 versionBootSubMinor_HLR "HLR";
BA_ "GatewayedSignal" SG_ 1615 versionBootMinor_HLR 1;
BA_ "OriginatingECU" SG_ 1615 versionBootMinor_HLR "HLR";
BA_ "GenSigSendType" SG_ 1633 nmPartialNetworks_DCFL 1;
BA_ "GenSigSendType" SG_ 1633 nmActiveWake_DCFL 1;
BA_ "GenSigSendType" SG_ 1633 nmID_DCFL 1;
BA_ "GenSigSendType" SG_ 1633 nmPnBody_DCFL 1;
BA_ "GenSigSendType" SG_ 1633 nmPnCharging_DCFL 1;
BA_ "GenSigSendType" SG_ 1633 nmPnKeypad_DCFL 1;
BA_ "GenSigSendType" SG_ 1633 nmPnBPG_DCFL 1;
BA_ "GenSigSendType" SG_ 1634 hardwarePartNumber_DCFL 1;
BA_ "GenSigSendType" SG_ 1634 hardwareRevisionId_DCFL 1;
BA_ "GenSigSendType" SG_ 1634 bootloaderStuckSignal_DCFL 1;
BA_ "OriginatingECU" SG_ 1634 resetCause_DCFL "DCFL";
BA_ "GatewayedSignal" SG_ 1634 resetCause_DCFL 1;
BA_ "GenSigSendType" SG_ 1634 resetCause_DCFL 1;
BA_ "SNARequired" SG_ 1637 udsClientDataDcfl_TOOL 1;
BA_ "GenSigSendType" SG_ 1637 udsClientDataDcfl_TOOL 1;
BA_ "SNARequired" SG_ 1638 udsServerData_DCFL 1;
BA_ "GenSigSendType" SG_ 1638 udsServerData_DCFL 1;
BA_ "GatewayedSignal" SG_ 1639 versionCalSubMinor_DCFL 1;
BA_ "OriginatingECU" SG_ 1639 versionCalSubMinor_DCFL "DCFL";
BA_ "GatewayedSignal" SG_ 1639 versionCalReleaseCandidate_DCFL 1;
BA_ "OriginatingECU" SG_ 1639 versionCalReleaseCandidate_DCFL "DCFL";
BA_ "GatewayedSignal" SG_ 1639 versionCalMinor_DCFL 1;
BA_ "OriginatingECU" SG_ 1639 versionCalMinor_DCFL "DCFL";
BA_ "GatewayedSignal" SG_ 1639 versionCalMajor_DCFL 1;
BA_ "OriginatingECU" SG_ 1639 versionCalMajor_DCFL "DCFL";
BA_ "GatewayedSignal" SG_ 1639 idCalBuildMachine_DCFL 1;
BA_ "OriginatingECU" SG_ 1639 idCalBuildMachine_DCFL "DCFL";
BA_ "GatewayedSignal" SG_ 1639 idCalGitHashUpper_DCFL 1;
BA_ "OriginatingECU" SG_ 1639 idCalGitHashUpper_DCFL "DCFL";
BA_ "GatewayedSignal" SG_ 1639 versionReleaseCandidate_DCFL 1;
BA_ "OriginatingECU" SG_ 1639 versionReleaseCandidate_DCFL "DCFL";
BA_ "GatewayedSignal" SG_ 1639 versionBootReleaseCandidate_DCFL 1;
BA_ "OriginatingECU" SG_ 1639 versionBootReleaseCandidate_DCFL "DCFL";
BA_ "GatewayedSignal" SG_ 1639 componentNum_DCFL 1;
BA_ "OriginatingECU" SG_ 1639 componentNum_DCFL "DCFL";
BA_ "GatewayedSignal" SG_ 1639 idGitHashUpper_DCFL 1;
BA_ "OriginatingECU" SG_ 1639 idGitHashUpper_DCFL "DCFL";
BA_ "GatewayedSignal" SG_ 1639 idBootGitHashUpper_DCFL 1;
BA_ "OriginatingECU" SG_ 1639 idBootGitHashUpper_DCFL "DCFL";
BA_ "GatewayedSignal" SG_ 1639 idBuildMachine_DCFL 1;
BA_ "OriginatingECU" SG_ 1639 idBuildMachine_DCFL "DCFL";
BA_ "GatewayedSignal" SG_ 1639 versionSubMinor_DCFL 1;
BA_ "OriginatingECU" SG_ 1639 versionSubMinor_DCFL "DCFL";
BA_ "GatewayedSignal" SG_ 1639 versionMinor_DCFL 1;
BA_ "OriginatingECU" SG_ 1639 versionMinor_DCFL "DCFL";
BA_ "GatewayedSignal" SG_ 1639 versionMajor_DCFL 1;
BA_ "OriginatingECU" SG_ 1639 versionMajor_DCFL "DCFL";
BA_ "GatewayedSignal" SG_ 1639 idBootBuildMachine_DCFL 1;
BA_ "OriginatingECU" SG_ 1639 idBootBuildMachine_DCFL "DCFL";
BA_ "GatewayedSignal" SG_ 1639 versionBootSubMinor_DCFL 1;
BA_ "OriginatingECU" SG_ 1639 versionBootSubMinor_DCFL "DCFL";
BA_ "GatewayedSignal" SG_ 1639 versionBootMinor_DCFL 1;
BA_ "OriginatingECU" SG_ 1639 versionBootMinor_DCFL "DCFL";
BA_ "GatewayedSignal" SG_ 1639 versionBootMajor_DCFL 1;
BA_ "OriginatingECU" SG_ 1639 versionBootMajor_DCFL "DCFL";
BA_ "GenSigSendType" SG_ 1650 resetCause_DSM 1;
BA_ "GenSigSendType" SG_ 1650 hardwareRevisionId_DSM 1;
BA_ "GenSigSendType" SG_ 1650 hardwarePartNumber_DSM 1;
BA_ "GenSigSendType" SG_ 1650 bootloaderStuckSignal_DSM 1;
BA_ "SNARequired" SG_ 1653 udsClientDataDSM_TOOL 1;
BA_ "GenSigSendType" SG_ 1653 udsClientDataDSM_TOOL 1;
BA_ "SNARequired" SG_ 1654 udsServerData_DSM 1;
BA_ "GenSigSendType" SG_ 1654 udsServerData_DSM 1;
BA_ "GatewayedSignal" SG_ 1655 versionReleaseCandidate_DSM 1;
BA_ "OriginatingECU" SG_ 1655 versionReleaseCandidate_DSM "DSM";
BA_ "GatewayedSignal" SG_ 1655 versionBootReleaseCandidate_DSM 1;
BA_ "OriginatingECU" SG_ 1655 versionBootReleaseCandidate_DSM "DSM";
BA_ "GatewayedSignal" SG_ 1655 componentNum_DSM 1;
BA_ "OriginatingECU" SG_ 1655 componentNum_DSM "DSM";
BA_ "GatewayedSignal" SG_ 1655 idGitHashUpper_DSM 1;
BA_ "OriginatingECU" SG_ 1655 idGitHashUpper_DSM "DSM";
BA_ "GatewayedSignal" SG_ 1655 idBootGitHashUpper_DSM 1;
BA_ "OriginatingECU" SG_ 1655 idBootGitHashUpper_DSM "DSM";
BA_ "GatewayedSignal" SG_ 1655 idBuildMachine_DSM 1;
BA_ "OriginatingECU" SG_ 1655 idBuildMachine_DSM "DSM";
BA_ "GatewayedSignal" SG_ 1655 versionSubMinor_DSM 1;
BA_ "OriginatingECU" SG_ 1655 versionSubMinor_DSM "DSM";
BA_ "GatewayedSignal" SG_ 1655 versionMinor_DSM 1;
BA_ "OriginatingECU" SG_ 1655 versionMinor_DSM "DSM";
BA_ "GatewayedSignal" SG_ 1655 versionMajor_DSM 1;
BA_ "OriginatingECU" SG_ 1655 versionMajor_DSM "DSM";
BA_ "GatewayedSignal" SG_ 1655 idBootBuildMachine_DSM 1;
BA_ "OriginatingECU" SG_ 1655 idBootBuildMachine_DSM "DSM";
BA_ "GatewayedSignal" SG_ 1655 versionBootSubMinor_DSM 1;
BA_ "OriginatingECU" SG_ 1655 versionBootSubMinor_DSM "DSM";
BA_ "GatewayedSignal" SG_ 1655 versionBootMinor_DSM 1;
BA_ "OriginatingECU" SG_ 1655 versionBootMinor_DSM "DSM";
BA_ "GatewayedSignal" SG_ 1655 versionBootMajor_DSM 1;
BA_ "OriginatingECU" SG_ 1655 versionBootMajor_DSM "DSM";
BA_ "GenSigSendType" SG_ 1673 nmPartialNetworks_DCFR 1;
BA_ "GenSigSendType" SG_ 1673 nmActiveWake_DCFR 1;
BA_ "GenSigSendType" SG_ 1673 nmID_DCFR 1;
BA_ "GenSigSendType" SG_ 1673 nmPnBody_DCFR 1;
BA_ "GenSigSendType" SG_ 1673 nmPnCharging_DCFR 1;
BA_ "GenSigSendType" SG_ 1673 nmPnKeypad_DCFR 1;
BA_ "GenSigSendType" SG_ 1673 nmPnBPG_DCFR 1;
BA_ "GenSigSendType" SG_ 1674 hardwarePartNumber_DCFR 1;
BA_ "GenSigSendType" SG_ 1674 hardwareRevisionId_DCFR 1;
BA_ "GenSigSendType" SG_ 1674 bootloaderStuckSignal_DCFR 1;
BA_ "OriginatingECU" SG_ 1674 resetCause_DCFR "DCFR";
BA_ "GatewayedSignal" SG_ 1674 resetCause_DCFR 1;
BA_ "GenSigSendType" SG_ 1674 resetCause_DCFR 1;
BA_ "SNARequired" SG_ 1677 udsClientDataDcfr_TOOL 1;
BA_ "GenSigSendType" SG_ 1677 udsClientDataDcfr_TOOL 1;
BA_ "SNARequired" SG_ 1678 udsServerData_DCFR 1;
BA_ "GenSigSendType" SG_ 1678 udsServerData_DCFR 1;
BA_ "GatewayedSignal" SG_ 1679 versionCalSubMinor_DCFR 1;
BA_ "OriginatingECU" SG_ 1679 versionCalSubMinor_DCFR "DCFR";
BA_ "GatewayedSignal" SG_ 1679 versionCalReleaseCandidate_DCFR 1;
BA_ "OriginatingECU" SG_ 1679 versionCalReleaseCandidate_DCFR "DCFR";
BA_ "GatewayedSignal" SG_ 1679 versionCalMinor_DCFR 1;
BA_ "OriginatingECU" SG_ 1679 versionCalMinor_DCFR "DCFR";
BA_ "GatewayedSignal" SG_ 1679 versionCalMajor_DCFR 1;
BA_ "OriginatingECU" SG_ 1679 versionCalMajor_DCFR "DCFR";
BA_ "OriginatingECU" SG_ 1679 idCalBuildMachine_DCFR "DCFR";
BA_ "GatewayedSignal" SG_ 1679 idCalBuildMachine_DCFR 1;
BA_ "OriginatingECU" SG_ 1679 idCalGitHashUpper_DCFR "DCFR";
BA_ "GatewayedSignal" SG_ 1679 idCalGitHashUpper_DCFR 1;
BA_ "GatewayedSignal" SG_ 1679 versionReleaseCandidate_DCFR 1;
BA_ "OriginatingECU" SG_ 1679 versionReleaseCandidate_DCFR "DCFR";
BA_ "GatewayedSignal" SG_ 1679 versionBootReleaseCandidate_DCFR 1;
BA_ "OriginatingECU" SG_ 1679 versionBootReleaseCandidate_DCFR "DCFR";
BA_ "GatewayedSignal" SG_ 1679 componentNum_DCFR 1;
BA_ "OriginatingECU" SG_ 1679 componentNum_DCFR "DCFR";
BA_ "GatewayedSignal" SG_ 1679 idGitHashUpper_DCFR 1;
BA_ "OriginatingECU" SG_ 1679 idGitHashUpper_DCFR "DCFR";
BA_ "GatewayedSignal" SG_ 1679 idBootGitHashUpper_DCFR 1;
BA_ "OriginatingECU" SG_ 1679 idBootGitHashUpper_DCFR "DCFR";
BA_ "GatewayedSignal" SG_ 1679 idBuildMachine_DCFR 1;
BA_ "OriginatingECU" SG_ 1679 idBuildMachine_DCFR "DCFR";
BA_ "GatewayedSignal" SG_ 1679 versionSubMinor_DCFR 1;
BA_ "OriginatingECU" SG_ 1679 versionSubMinor_DCFR "DCFR";
BA_ "GatewayedSignal" SG_ 1679 versionMinor_DCFR 1;
BA_ "OriginatingECU" SG_ 1679 versionMinor_DCFR "DCFR";
BA_ "GatewayedSignal" SG_ 1679 versionMajor_DCFR 1;
BA_ "OriginatingECU" SG_ 1679 versionMajor_DCFR "DCFR";
BA_ "GatewayedSignal" SG_ 1679 idBootBuildMachine_DCFR 1;
BA_ "OriginatingECU" SG_ 1679 idBootBuildMachine_DCFR "DCFR";
BA_ "GatewayedSignal" SG_ 1679 versionBootSubMinor_DCFR 1;
BA_ "OriginatingECU" SG_ 1679 versionBootSubMinor_DCFR "DCFR";
BA_ "GatewayedSignal" SG_ 1679 versionBootMinor_DCFR 1;
BA_ "OriginatingECU" SG_ 1679 versionBootMinor_DCFR "DCFR";
BA_ "GatewayedSignal" SG_ 1679 versionBootMajor_DCFR 1;
BA_ "OriginatingECU" SG_ 1679 versionBootMajor_DCFR "DCFR";
BA_ "GenSigSendType" SG_ 1682 resetCause_PSM 1;
BA_ "GenSigSendType" SG_ 1682 hardwareRevisionId_PSM 1;
BA_ "GenSigSendType" SG_ 1682 hardwarePartNumber_PSM 1;
BA_ "GenSigSendType" SG_ 1682 bootloaderStuckSignal_PSM 1;
BA_ "SNARequired" SG_ 1685 udsClientDataPSM_TOOL 1;
BA_ "GenSigSendType" SG_ 1685 udsClientDataPSM_TOOL 1;
BA_ "SNARequired" SG_ 1686 udsServerData_PSM 1;
BA_ "GenSigSendType" SG_ 1686 udsServerData_PSM 1;
BA_ "GatewayedSignal" SG_ 1687 versionReleaseCandidate_PSM 1;
BA_ "OriginatingECU" SG_ 1687 versionReleaseCandidate_PSM "PSM";
BA_ "GatewayedSignal" SG_ 1687 versionBootReleaseCandidate_PSM 1;
BA_ "OriginatingECU" SG_ 1687 versionBootReleaseCandidate_PSM "PSM";
BA_ "GatewayedSignal" SG_ 1687 componentNum_PSM 1;
BA_ "OriginatingECU" SG_ 1687 componentNum_PSM "PSM";
BA_ "GatewayedSignal" SG_ 1687 idGitHashUpper_PSM 1;
BA_ "OriginatingECU" SG_ 1687 idGitHashUpper_PSM "PSM";
BA_ "GatewayedSignal" SG_ 1687 idBootGitHashUpper_PSM 1;
BA_ "OriginatingECU" SG_ 1687 idBootGitHashUpper_PSM "PSM";
BA_ "GatewayedSignal" SG_ 1687 idBuildMachine_PSM 1;
BA_ "OriginatingECU" SG_ 1687 idBuildMachine_PSM "PSM";
BA_ "GatewayedSignal" SG_ 1687 versionSubMinor_PSM 1;
BA_ "OriginatingECU" SG_ 1687 versionSubMinor_PSM "PSM";
BA_ "GatewayedSignal" SG_ 1687 versionMinor_PSM 1;
BA_ "OriginatingECU" SG_ 1687 versionMinor_PSM "PSM";
BA_ "GatewayedSignal" SG_ 1687 versionMajor_PSM 1;
BA_ "OriginatingECU" SG_ 1687 versionMajor_PSM "PSM";
BA_ "GatewayedSignal" SG_ 1687 idBootBuildMachine_PSM 1;
BA_ "OriginatingECU" SG_ 1687 idBootBuildMachine_PSM "PSM";
BA_ "GatewayedSignal" SG_ 1687 versionBootSubMinor_PSM 1;
BA_ "OriginatingECU" SG_ 1687 versionBootSubMinor_PSM "PSM";
BA_ "GatewayedSignal" SG_ 1687 versionBootMinor_PSM 1;
BA_ "OriginatingECU" SG_ 1687 versionBootMinor_PSM "PSM";
BA_ "GatewayedSignal" SG_ 1687 versionBootMajor_PSM 1;
BA_ "OriginatingECU" SG_ 1687 versionBootMajor_PSM "PSM";
BA_ "GenSigSendType" SG_ 1705 nmPartialNetworks_DCRL 1;
BA_ "GenSigSendType" SG_ 1705 nmActiveWake_DCRL 1;
BA_ "GenSigSendType" SG_ 1705 nmID_DCRL 1;
BA_ "GenSigSendType" SG_ 1705 nmPnBody_DCRL 1;
BA_ "GenSigSendType" SG_ 1705 nmPnCharging_DCRL 1;
BA_ "GenSigSendType" SG_ 1705 nmPnKeypad_DCRL 1;
BA_ "GenSigSendType" SG_ 1705 nmPnBPG_DCRL 1;
BA_ "GenSigSendType" SG_ 1706 hardwarePartNumber_DCRL 1;
BA_ "GenSigSendType" SG_ 1706 hardwareRevisionId_DCRL 1;
BA_ "GenSigSendType" SG_ 1706 bootloaderStuckSignal_DCRL 1;
BA_ "OriginatingECU" SG_ 1706 resetCause_DCRL "DCRL";
BA_ "GatewayedSignal" SG_ 1706 resetCause_DCRL 1;
BA_ "GenSigSendType" SG_ 1706 resetCause_DCRL 1;
BA_ "SNARequired" SG_ 1709 udsClientDataDcrl_TOOL 1;
BA_ "GenSigSendType" SG_ 1709 udsClientDataDcrl_TOOL 1;
BA_ "SNARequired" SG_ 1710 udsServerData_DCRL 1;
BA_ "GenSigSendType" SG_ 1710 udsServerData_DCRL 1;
BA_ "GatewayedSignal" SG_ 1711 versionCalSubMinor_DCRL 1;
BA_ "OriginatingECU" SG_ 1711 versionCalSubMinor_DCRL "DCRL";
BA_ "GatewayedSignal" SG_ 1711 versionCalReleaseCandidate_DCRL 1;
BA_ "OriginatingECU" SG_ 1711 versionCalReleaseCandidate_DCRL "DCRL";
BA_ "GatewayedSignal" SG_ 1711 versionCalMinor_DCRL 1;
BA_ "OriginatingECU" SG_ 1711 versionCalMinor_DCRL "DCRL";
BA_ "GatewayedSignal" SG_ 1711 versionCalMajor_DCRL 1;
BA_ "OriginatingECU" SG_ 1711 versionCalMajor_DCRL "DCRL";
BA_ "GatewayedSignal" SG_ 1711 idCalBuildMachine_DCRL 1;
BA_ "OriginatingECU" SG_ 1711 idCalBuildMachine_DCRL "DCRL";
BA_ "GatewayedSignal" SG_ 1711 idCalGitHashUpper_DCRL 1;
BA_ "OriginatingECU" SG_ 1711 idCalGitHashUpper_DCRL "DCRL";
BA_ "GatewayedSignal" SG_ 1711 versionReleaseCandidate_DCRL 1;
BA_ "OriginatingECU" SG_ 1711 versionReleaseCandidate_DCRL "DCRL";
BA_ "GatewayedSignal" SG_ 1711 versionBootReleaseCandidate_DCRL 1;
BA_ "OriginatingECU" SG_ 1711 versionBootReleaseCandidate_DCRL "DCRL";
BA_ "GatewayedSignal" SG_ 1711 componentNum_DCRL 1;
BA_ "OriginatingECU" SG_ 1711 componentNum_DCRL "DCRL";
BA_ "GatewayedSignal" SG_ 1711 idGitHashUpper_DCRL 1;
BA_ "OriginatingECU" SG_ 1711 idGitHashUpper_DCRL "DCRL";
BA_ "GatewayedSignal" SG_ 1711 idBootGitHashUpper_DCRL 1;
BA_ "OriginatingECU" SG_ 1711 idBootGitHashUpper_DCRL "DCRL";
BA_ "GatewayedSignal" SG_ 1711 idBuildMachine_DCRL 1;
BA_ "OriginatingECU" SG_ 1711 idBuildMachine_DCRL "DCRL";
BA_ "GatewayedSignal" SG_ 1711 versionSubMinor_DCRL 1;
BA_ "OriginatingECU" SG_ 1711 versionSubMinor_DCRL "DCRL";
BA_ "GatewayedSignal" SG_ 1711 versionMinor_DCRL 1;
BA_ "OriginatingECU" SG_ 1711 versionMinor_DCRL "DCRL";
BA_ "GatewayedSignal" SG_ 1711 versionMajor_DCRL 1;
BA_ "OriginatingECU" SG_ 1711 versionMajor_DCRL "DCRL";
BA_ "GatewayedSignal" SG_ 1711 idBootBuildMachine_DCRL 1;
BA_ "OriginatingECU" SG_ 1711 idBootBuildMachine_DCRL "DCRL";
BA_ "GatewayedSignal" SG_ 1711 versionBootSubMinor_DCRL 1;
BA_ "OriginatingECU" SG_ 1711 versionBootSubMinor_DCRL "DCRL";
BA_ "GatewayedSignal" SG_ 1711 versionBootMinor_DCRL 1;
BA_ "OriginatingECU" SG_ 1711 versionBootMinor_DCRL "DCRL";
BA_ "GatewayedSignal" SG_ 1711 versionBootMajor_DCRL 1;
BA_ "OriginatingECU" SG_ 1711 versionBootMajor_DCRL "DCRL";
BA_ "GenSigSendType" SG_ 1714 resetCause_RLSM 1;
BA_ "GenSigSendType" SG_ 1714 hardwareRevisionId_RLSM 1;
BA_ "GenSigSendType" SG_ 1714 hardwarePartNumber_RLSM 1;
BA_ "GenSigSendType" SG_ 1714 bootloaderStuckSignal_RLSM 1;
BA_ "SNARequired" SG_ 1717 udsClientDataRLSM_TOOL 1;
BA_ "GenSigSendType" SG_ 1717 udsClientDataRLSM_TOOL 1;
BA_ "SNARequired" SG_ 1718 udsServerData_RLSM 1;
BA_ "GenSigSendType" SG_ 1718 udsServerData_RLSM 1;
BA_ "GatewayedSignal" SG_ 1719 versionReleaseCandidate_RLSM 1;
BA_ "OriginatingECU" SG_ 1719 versionReleaseCandidate_RLSM "RLSM";
BA_ "GatewayedSignal" SG_ 1719 versionBootReleaseCandidate_RLSM 1;
BA_ "OriginatingECU" SG_ 1719 versionBootReleaseCandidate_RLSM "RLSM";
BA_ "GatewayedSignal" SG_ 1719 componentNum_RLSM 1;
BA_ "OriginatingECU" SG_ 1719 componentNum_RLSM "RLSM";
BA_ "GatewayedSignal" SG_ 1719 idGitHashUpper_RLSM 1;
BA_ "OriginatingECU" SG_ 1719 idGitHashUpper_RLSM "RLSM";
BA_ "GatewayedSignal" SG_ 1719 idBootGitHashUpper_RLSM 1;
BA_ "OriginatingECU" SG_ 1719 idBootGitHashUpper_RLSM "RLSM";
BA_ "GatewayedSignal" SG_ 1719 idBuildMachine_RLSM 1;
BA_ "OriginatingECU" SG_ 1719 idBuildMachine_RLSM "RLSM";
BA_ "GatewayedSignal" SG_ 1719 versionSubMinor_RLSM 1;
BA_ "OriginatingECU" SG_ 1719 versionSubMinor_RLSM "RLSM";
BA_ "GatewayedSignal" SG_ 1719 versionMinor_RLSM 1;
BA_ "OriginatingECU" SG_ 1719 versionMinor_RLSM "RLSM";
BA_ "GatewayedSignal" SG_ 1719 versionMajor_RLSM 1;
BA_ "OriginatingECU" SG_ 1719 versionMajor_RLSM "RLSM";
BA_ "GatewayedSignal" SG_ 1719 idBootBuildMachine_RLSM 1;
BA_ "OriginatingECU" SG_ 1719 idBootBuildMachine_RLSM "RLSM";
BA_ "GatewayedSignal" SG_ 1719 versionBootSubMinor_RLSM 1;
BA_ "OriginatingECU" SG_ 1719 versionBootSubMinor_RLSM "RLSM";
BA_ "GatewayedSignal" SG_ 1719 versionBootMinor_RLSM 1;
BA_ "OriginatingECU" SG_ 1719 versionBootMinor_RLSM "RLSM";
BA_ "GatewayedSignal" SG_ 1719 versionBootMajor_RLSM 1;
BA_ "OriginatingECU" SG_ 1719 versionBootMajor_RLSM "RLSM";
BA_ "GenSigSendType" SG_ 1737 nmPartialNetworks_DCRR 1;
BA_ "GenSigSendType" SG_ 1737 nmActiveWake_DCRR 1;
BA_ "GenSigSendType" SG_ 1737 nmID_DCRR 1;
BA_ "GenSigSendType" SG_ 1737 nmPnBody_DCRR 1;
BA_ "GenSigSendType" SG_ 1737 nmPnCharging_DCRR 1;
BA_ "GenSigSendType" SG_ 1737 nmPnKeypad_DCRR 1;
BA_ "GenSigSendType" SG_ 1737 nmPnBPG_DCRR 1;
BA_ "GenSigSendType" SG_ 1738 hardwarePartNumber_DCRR 1;
BA_ "GenSigSendType" SG_ 1738 hardwareRevisionId_DCRR 1;
BA_ "GenSigSendType" SG_ 1738 bootloaderStuckSignal_DCRR 1;
BA_ "OriginatingECU" SG_ 1738 resetCause_DCRR "DCRR";
BA_ "GatewayedSignal" SG_ 1738 resetCause_DCRR 1;
BA_ "GenSigSendType" SG_ 1738 resetCause_DCRR 1;
BA_ "SNARequired" SG_ 1741 udsClientDataDcrr_TOOL 1;
BA_ "GenSigSendType" SG_ 1741 udsClientDataDcrr_TOOL 1;
BA_ "SNARequired" SG_ 1742 udsServerData_DCRR 1;
BA_ "GenSigSendType" SG_ 1742 udsServerData_DCRR 1;
BA_ "GatewayedSignal" SG_ 1743 versionCalSubMinor_DCRR 1;
BA_ "OriginatingECU" SG_ 1743 versionCalSubMinor_DCRR "DCRR";
BA_ "GatewayedSignal" SG_ 1743 versionCalReleaseCandidate_DCRR 1;
BA_ "OriginatingECU" SG_ 1743 versionCalReleaseCandidate_DCRR "DCRR";
BA_ "GatewayedSignal" SG_ 1743 versionCalMinor_DCRR 1;
BA_ "OriginatingECU" SG_ 1743 versionCalMinor_DCRR "DCRR";
BA_ "GatewayedSignal" SG_ 1743 versionCalMajor_DCRR 1;
BA_ "OriginatingECU" SG_ 1743 versionCalMajor_DCRR "DCRR";
BA_ "GatewayedSignal" SG_ 1743 idCalBuildMachine_DCRR 1;
BA_ "OriginatingECU" SG_ 1743 idCalBuildMachine_DCRR "DCRR";
BA_ "GatewayedSignal" SG_ 1743 idCalGitHashUpper_DCRR 1;
BA_ "OriginatingECU" SG_ 1743 idCalGitHashUpper_DCRR "DCRR";
BA_ "GatewayedSignal" SG_ 1743 versionReleaseCandidate_DCRR 1;
BA_ "OriginatingECU" SG_ 1743 versionReleaseCandidate_DCRR "DCRR";
BA_ "GatewayedSignal" SG_ 1743 versionBootReleaseCandidate_DCRR 1;
BA_ "OriginatingECU" SG_ 1743 versionBootReleaseCandidate_DCRR "DCRR";
BA_ "GatewayedSignal" SG_ 1743 componentNum_DCRR 1;
BA_ "OriginatingECU" SG_ 1743 componentNum_DCRR "DCRR";
BA_ "GatewayedSignal" SG_ 1743 idGitHashUpper_DCRR 1;
BA_ "OriginatingECU" SG_ 1743 idGitHashUpper_DCRR "DCRR";
BA_ "GatewayedSignal" SG_ 1743 idBootGitHashUpper_DCRR 1;
BA_ "OriginatingECU" SG_ 1743 idBootGitHashUpper_DCRR "DCRR";
BA_ "GatewayedSignal" SG_ 1743 idBuildMachine_DCRR 1;
BA_ "OriginatingECU" SG_ 1743 idBuildMachine_DCRR "DCRR";
BA_ "GatewayedSignal" SG_ 1743 versionSubMinor_DCRR 1;
BA_ "OriginatingECU" SG_ 1743 versionSubMinor_DCRR "DCRR";
BA_ "GatewayedSignal" SG_ 1743 versionMinor_DCRR 1;
BA_ "OriginatingECU" SG_ 1743 versionMinor_DCRR "DCRR";
BA_ "GatewayedSignal" SG_ 1743 versionMajor_DCRR 1;
BA_ "OriginatingECU" SG_ 1743 versionMajor_DCRR "DCRR";
BA_ "GatewayedSignal" SG_ 1743 idBootBuildMachine_DCRR 1;
BA_ "OriginatingECU" SG_ 1743 idBootBuildMachine_DCRR "DCRR";
BA_ "GatewayedSignal" SG_ 1743 versionBootSubMinor_DCRR 1;
BA_ "OriginatingECU" SG_ 1743 versionBootSubMinor_DCRR "DCRR";
BA_ "GatewayedSignal" SG_ 1743 versionBootMinor_DCRR 1;
BA_ "OriginatingECU" SG_ 1743 versionBootMinor_DCRR "DCRR";
BA_ "GatewayedSignal" SG_ 1743 versionBootMajor_DCRR 1;
BA_ "OriginatingECU" SG_ 1743 versionBootMajor_DCRR "DCRR";
BA_ "GenSigSendType" SG_ 1746 resetCause_RRSM 1;
BA_ "GenSigSendType" SG_ 1746 hardwareRevisionId_RRSM 1;
BA_ "GenSigSendType" SG_ 1746 hardwarePartNumber_RRSM 1;
BA_ "GenSigSendType" SG_ 1746 bootloaderStuckSignal_RRSM 1;
BA_ "SNARequired" SG_ 1749 udsClientDataRRSM_TOOL 1;
BA_ "GenSigSendType" SG_ 1749 udsClientDataRRSM_TOOL 1;
BA_ "SNARequired" SG_ 1750 udsServerData_RRSM 1;
BA_ "GenSigSendType" SG_ 1750 udsServerData_RRSM 1;
BA_ "GatewayedSignal" SG_ 1751 versionReleaseCandidate_RRSM 1;
BA_ "OriginatingECU" SG_ 1751 versionReleaseCandidate_RRSM "RRSM";
BA_ "GatewayedSignal" SG_ 1751 versionBootReleaseCandidate_RRSM 1;
BA_ "OriginatingECU" SG_ 1751 versionBootReleaseCandidate_RRSM "RRSM";
BA_ "GatewayedSignal" SG_ 1751 componentNum_RRSM 1;
BA_ "OriginatingECU" SG_ 1751 componentNum_RRSM "RRSM";
BA_ "GatewayedSignal" SG_ 1751 idGitHashUpper_RRSM 1;
BA_ "OriginatingECU" SG_ 1751 idGitHashUpper_RRSM "RRSM";
BA_ "GatewayedSignal" SG_ 1751 idBootGitHashUpper_RRSM 1;
BA_ "OriginatingECU" SG_ 1751 idBootGitHashUpper_RRSM "RRSM";
BA_ "GatewayedSignal" SG_ 1751 idBuildMachine_RRSM 1;
BA_ "OriginatingECU" SG_ 1751 idBuildMachine_RRSM "RRSM";
BA_ "GatewayedSignal" SG_ 1751 versionSubMinor_RRSM 1;
BA_ "OriginatingECU" SG_ 1751 versionSubMinor_RRSM "RRSM";
BA_ "GatewayedSignal" SG_ 1751 versionMinor_RRSM 1;
BA_ "OriginatingECU" SG_ 1751 versionMinor_RRSM "RRSM";
BA_ "GatewayedSignal" SG_ 1751 versionMajor_RRSM 1;
BA_ "OriginatingECU" SG_ 1751 versionMajor_RRSM "RRSM";
BA_ "GatewayedSignal" SG_ 1751 idBootBuildMachine_RRSM 1;
BA_ "OriginatingECU" SG_ 1751 idBootBuildMachine_RRSM "RRSM";
BA_ "GatewayedSignal" SG_ 1751 versionBootSubMinor_RRSM 1;
BA_ "OriginatingECU" SG_ 1751 versionBootSubMinor_RRSM "RRSM";
BA_ "GatewayedSignal" SG_ 1751 versionBootMinor_RRSM 1;
BA_ "OriginatingECU" SG_ 1751 versionBootMinor_RRSM "RRSM";
BA_ "GatewayedSignal" SG_ 1751 versionBootMajor_RRSM 1;
BA_ "OriginatingECU" SG_ 1751 versionBootMajor_RRSM "RRSM";
BA_ "SNARequired" SG_ 1773 udsClientDataLGL_TOOL 1;
BA_ "GenSigSendType" SG_ 1773 udsClientDataLGL_TOOL 1;
BA_ "SNARequired" SG_ 1774 udsServerData_LGL 1;
BA_ "GenSigSendType" SG_ 1774 udsServerData_LGL 1;
BA_ "GatewayedSignal" SG_ 1775 versionReleaseCandidate_LGL 1;
BA_ "OriginatingECU" SG_ 1775 versionReleaseCandidate_LGL "LGL";
BA_ "GatewayedSignal" SG_ 1775 versionBootReleaseCandidate_LGL 1;
BA_ "OriginatingECU" SG_ 1775 versionBootReleaseCandidate_LGL "LGL";
BA_ "GatewayedSignal" SG_ 1775 componentNum_LGL 1;
BA_ "OriginatingECU" SG_ 1775 componentNum_LGL "LGL";
BA_ "GatewayedSignal" SG_ 1775 idGitHashUpper_LGL 1;
BA_ "OriginatingECU" SG_ 1775 idGitHashUpper_LGL "LGL";
BA_ "GatewayedSignal" SG_ 1775 idBootGitHashUpper_LGL 1;
BA_ "OriginatingECU" SG_ 1775 idBootGitHashUpper_LGL "LGL";
BA_ "GatewayedSignal" SG_ 1775 idBuildMachine_LGL 1;
BA_ "OriginatingECU" SG_ 1775 idBuildMachine_LGL "LGL";
BA_ "GatewayedSignal" SG_ 1775 versionSubMinor_LGL 1;
BA_ "OriginatingECU" SG_ 1775 versionSubMinor_LGL "LGL";
BA_ "GatewayedSignal" SG_ 1775 versionMinor_LGL 1;
BA_ "OriginatingECU" SG_ 1775 versionMinor_LGL "LGL";
BA_ "GatewayedSignal" SG_ 1775 versionMajor_LGL 1;
BA_ "OriginatingECU" SG_ 1775 versionMajor_LGL "LGL";
BA_ "GatewayedSignal" SG_ 1775 idBootBuildMachine_LGL 1;
BA_ "OriginatingECU" SG_ 1775 idBootBuildMachine_LGL "LGL";
BA_ "GatewayedSignal" SG_ 1775 versionBootSubMinor_LGL 1;
BA_ "OriginatingECU" SG_ 1775 versionBootSubMinor_LGL "LGL";
BA_ "GatewayedSignal" SG_ 1775 versionBootMinor_LGL 1;
BA_ "OriginatingECU" SG_ 1775 versionBootMinor_LGL "LGL";
BA_ "GatewayedSignal" SG_ 1775 versionBootMajor_LGL 1;
BA_ "OriginatingECU" SG_ 1775 versionBootMajor_LGL "LGL";
BA_ "SNARequired" SG_ 1789 udsClientDataRCLL_TOOL 1;
BA_ "GenSigSendType" SG_ 1789 udsClientDataRCLL_TOOL 1;
BA_ "SNARequired" SG_ 1790 udsServerData_RCLL 1;
BA_ "GenSigSendType" SG_ 1790 udsServerData_RCLL 1;
BA_ "GatewayedSignal" SG_ 1791 versionReleaseCandidate_RCLL 1;
BA_ "OriginatingECU" SG_ 1791 versionReleaseCandidate_RCLL "RCLL";
BA_ "GatewayedSignal" SG_ 1791 versionBootReleaseCandidate_RCLL 1;
BA_ "OriginatingECU" SG_ 1791 versionBootReleaseCandidate_RCLL "RCLL";
BA_ "GatewayedSignal" SG_ 1791 componentNum_RCLL 1;
BA_ "OriginatingECU" SG_ 1791 componentNum_RCLL "RCLL";
BA_ "GatewayedSignal" SG_ 1791 idGitHashUpper_RCLL 1;
BA_ "OriginatingECU" SG_ 1791 idGitHashUpper_RCLL "RCLL";
BA_ "GatewayedSignal" SG_ 1791 idBootGitHashUpper_RCLL 1;
BA_ "OriginatingECU" SG_ 1791 idBootGitHashUpper_RCLL "RCLL";
BA_ "GatewayedSignal" SG_ 1791 idBuildMachine_RCLL 1;
BA_ "OriginatingECU" SG_ 1791 idBuildMachine_RCLL "RCLL";
BA_ "GatewayedSignal" SG_ 1791 versionSubMinor_RCLL 1;
BA_ "OriginatingECU" SG_ 1791 versionSubMinor_RCLL "RCLL";
BA_ "GatewayedSignal" SG_ 1791 versionMinor_RCLL 1;
BA_ "OriginatingECU" SG_ 1791 versionMinor_RCLL "RCLL";
BA_ "GatewayedSignal" SG_ 1791 versionMajor_RCLL 1;
BA_ "OriginatingECU" SG_ 1791 versionMajor_RCLL "RCLL";
BA_ "GatewayedSignal" SG_ 1791 idBootBuildMachine_RCLL 1;
BA_ "OriginatingECU" SG_ 1791 idBootBuildMachine_RCLL "RCLL";
BA_ "GatewayedSignal" SG_ 1791 versionBootSubMinor_RCLL 1;
BA_ "OriginatingECU" SG_ 1791 versionBootSubMinor_RCLL "RCLL";
BA_ "GatewayedSignal" SG_ 1791 versionBootMinor_RCLL 1;
BA_ "OriginatingECU" SG_ 1791 versionBootMinor_RCLL "RCLL";
BA_ "GatewayedSignal" SG_ 1791 versionBootMajor_RCLL 1;
BA_ "OriginatingECU" SG_ 1791 versionBootMajor_RCLL "RCLL";
BA_ "SNARequired" SG_ 1797 udsClientDataRCLR_TOOL 1;
BA_ "GenSigSendType" SG_ 1797 udsClientDataRCLR_TOOL 1;
BA_ "SNARequired" SG_ 1798 udsServerData_RCLR 1;
BA_ "GenSigSendType" SG_ 1798 udsServerData_RCLR 1;
BA_ "GatewayedSignal" SG_ 1799 versionReleaseCandidate_RCLR 1;
BA_ "OriginatingECU" SG_ 1799 versionReleaseCandidate_RCLR "RCLR";
BA_ "GatewayedSignal" SG_ 1799 versionBootReleaseCandidate_RCLR 1;
BA_ "OriginatingECU" SG_ 1799 versionBootReleaseCandidate_RCLR "RCLR";
BA_ "GatewayedSignal" SG_ 1799 componentNum_RCLR 1;
BA_ "OriginatingECU" SG_ 1799 componentNum_RCLR "RCLR";
BA_ "GatewayedSignal" SG_ 1799 idGitHashUpper_RCLR 1;
BA_ "OriginatingECU" SG_ 1799 idGitHashUpper_RCLR "RCLR";
BA_ "GatewayedSignal" SG_ 1799 idBootGitHashUpper_RCLR 1;
BA_ "OriginatingECU" SG_ 1799 idBootGitHashUpper_RCLR "RCLR";
BA_ "GatewayedSignal" SG_ 1799 idBuildMachine_RCLR 1;
BA_ "OriginatingECU" SG_ 1799 idBuildMachine_RCLR "RCLR";
BA_ "GatewayedSignal" SG_ 1799 versionSubMinor_RCLR 1;
BA_ "OriginatingECU" SG_ 1799 versionSubMinor_RCLR "RCLR";
BA_ "GatewayedSignal" SG_ 1799 versionMinor_RCLR 1;
BA_ "OriginatingECU" SG_ 1799 versionMinor_RCLR "RCLR";
BA_ "GatewayedSignal" SG_ 1799 versionMajor_RCLR 1;
BA_ "OriginatingECU" SG_ 1799 versionMajor_RCLR "RCLR";
BA_ "GatewayedSignal" SG_ 1799 idBootBuildMachine_RCLR 1;
BA_ "OriginatingECU" SG_ 1799 idBootBuildMachine_RCLR "RCLR";
BA_ "GatewayedSignal" SG_ 1799 versionBootSubMinor_RCLR 1;
BA_ "OriginatingECU" SG_ 1799 versionBootSubMinor_RCLR "RCLR";
BA_ "GatewayedSignal" SG_ 1799 versionBootMinor_RCLR 1;
BA_ "OriginatingECU" SG_ 1799 versionBootMinor_RCLR "RCLR";
BA_ "GatewayedSignal" SG_ 1799 versionBootMajor_RCLR 1;
BA_ "OriginatingECU" SG_ 1799 versionBootMajor_RCLR "RCLR";
BA_ "SNARequired" SG_ 1813 udsClientDataACCL_TOOL 1;
BA_ "GenSigSendType" SG_ 1813 udsClientDataACCL_TOOL 1;
BA_ "SNARequired" SG_ 1814 udsServerData_ACCL 1;
BA_ "GenSigSendType" SG_ 1814 udsServerData_ACCL 1;
BA_ "GatewayedSignal" SG_ 1815 versionReleaseCandidate_ACCL 1;
BA_ "OriginatingECU" SG_ 1815 versionReleaseCandidate_ACCL "ACCL";
BA_ "GatewayedSignal" SG_ 1815 versionBootReleaseCandidate_ACCL 1;
BA_ "OriginatingECU" SG_ 1815 versionBootReleaseCandidate_ACCL "ACCL";
BA_ "GatewayedSignal" SG_ 1815 componentNum_ACCL 1;
BA_ "OriginatingECU" SG_ 1815 componentNum_ACCL "ACCL";
BA_ "GatewayedSignal" SG_ 1815 idGitHashUpper_ACCL 1;
BA_ "OriginatingECU" SG_ 1815 idGitHashUpper_ACCL "ACCL";
BA_ "GatewayedSignal" SG_ 1815 idBootGitHashUpper_ACCL 1;
BA_ "OriginatingECU" SG_ 1815 idBootGitHashUpper_ACCL "ACCL";
BA_ "GatewayedSignal" SG_ 1815 idBuildMachine_ACCL 1;
BA_ "OriginatingECU" SG_ 1815 idBuildMachine_ACCL "ACCL";
BA_ "GatewayedSignal" SG_ 1815 versionSubMinor_ACCL 1;
BA_ "OriginatingECU" SG_ 1815 versionSubMinor_ACCL "ACCL";
BA_ "GatewayedSignal" SG_ 1815 versionMinor_ACCL 1;
BA_ "OriginatingECU" SG_ 1815 versionMinor_ACCL "ACCL";
BA_ "GatewayedSignal" SG_ 1815 versionMajor_ACCL 1;
BA_ "OriginatingECU" SG_ 1815 versionMajor_ACCL "ACCL";
BA_ "GatewayedSignal" SG_ 1815 idBootBuildMachine_ACCL 1;
BA_ "OriginatingECU" SG_ 1815 idBootBuildMachine_ACCL "ACCL";
BA_ "GatewayedSignal" SG_ 1815 versionBootSubMinor_ACCL 1;
BA_ "OriginatingECU" SG_ 1815 versionBootSubMinor_ACCL "ACCL";
BA_ "GatewayedSignal" SG_ 1815 versionBootMinor_ACCL 1;
BA_ "OriginatingECU" SG_ 1815 versionBootMinor_ACCL "ACCL";
BA_ "GatewayedSignal" SG_ 1815 versionBootMajor_ACCL 1;
BA_ "OriginatingECU" SG_ 1815 versionBootMajor_ACCL "ACCL";
BA_ "GenSigSendType" SG_ 1826 hardwarePartNumber_ECPM 1;
BA_ "GenSigSendType" SG_ 1826 hardwareRevisionId_ECPM 1;
BA_ "GenSigSendType" SG_ 1826 bootloaderStuckSignal_ECPM 1;
BA_ "GenSigSendType" SG_ 1826 resetCause_ECPM 1;
BA_ "SNARequired" SG_ 1829 udsClientDataECPM_TOOL 1;
BA_ "GenSigSendType" SG_ 1829 udsClientDataECPM_TOOL 1;
BA_ "SNARequired" SG_ 1830 udsServerData_ECPM 1;
BA_ "GenSigSendType" SG_ 1830 udsServerData_ECPM 1;
BA_ "GatewayedSignal" SG_ 1831 versionReleaseCandidate_ECPM 1;
BA_ "OriginatingECU" SG_ 1831 versionReleaseCandidate_ECPM "ECPM";
BA_ "GatewayedSignal" SG_ 1831 versionBootReleaseCandidate_ECPM 1;
BA_ "OriginatingECU" SG_ 1831 versionBootReleaseCandidate_ECPM "ECPM";
BA_ "GatewayedSignal" SG_ 1831 componentNum_ECPM 1;
BA_ "OriginatingECU" SG_ 1831 componentNum_ECPM "ECPM";
BA_ "GatewayedSignal" SG_ 1831 idGitHashUpper_ECPM 1;
BA_ "OriginatingECU" SG_ 1831 idGitHashUpper_ECPM "ECPM";
BA_ "GatewayedSignal" SG_ 1831 idBootGitHashUpper_ECPM 1;
BA_ "OriginatingECU" SG_ 1831 idBootGitHashUpper_ECPM "ECPM";
BA_ "GatewayedSignal" SG_ 1831 idBuildMachine_ECPM 1;
BA_ "OriginatingECU" SG_ 1831 idBuildMachine_ECPM "ECPM";
BA_ "GatewayedSignal" SG_ 1831 versionSubMinor_ECPM 1;
BA_ "OriginatingECU" SG_ 1831 versionSubMinor_ECPM "ECPM";
BA_ "GatewayedSignal" SG_ 1831 versionMinor_ECPM 1;
BA_ "OriginatingECU" SG_ 1831 versionMinor_ECPM "ECPM";
BA_ "GatewayedSignal" SG_ 1831 versionMajor_ECPM 1;
BA_ "OriginatingECU" SG_ 1831 versionMajor_ECPM "ECPM";
BA_ "GatewayedSignal" SG_ 1831 idBootBuildMachine_ECPM 1;
BA_ "OriginatingECU" SG_ 1831 idBootBuildMachine_ECPM "ECPM";
BA_ "GatewayedSignal" SG_ 1831 versionBootSubMinor_ECPM 1;
BA_ "OriginatingECU" SG_ 1831 versionBootSubMinor_ECPM "ECPM";
BA_ "GatewayedSignal" SG_ 1831 versionBootMinor_ECPM 1;
BA_ "OriginatingECU" SG_ 1831 versionBootMinor_ECPM "ECPM";
BA_ "GatewayedSignal" SG_ 1831 versionBootMajor_ECPM 1;
BA_ "OriginatingECU" SG_ 1831 versionBootMajor_ECPM "ECPM";
BA_ "GenSigSendType" SG_ 1842 hardwarePartNumber_DBPC 1;
BA_ "GenSigSendType" SG_ 1842 hardwareRevisionId_DBPC 1;
BA_ "GenSigSendType" SG_ 1842 bootloaderStuckSignal_DBPC 1;
BA_ "GenSigSendType" SG_ 1842 resetCause_DBPC 1;
BA_ "SNARequired" SG_ 1845 udsClientDataDBPC_TOOL 1;
BA_ "GenSigSendType" SG_ 1845 udsClientDataDBPC_TOOL 1;
BA_ "SNARequired" SG_ 1846 udsServerData_DBPC 1;
BA_ "GenSigSendType" SG_ 1846 udsServerData_DBPC 1;
BA_ "GatewayedSignal" SG_ 1847 versionReleaseCandidate_DBPC 1;
BA_ "OriginatingECU" SG_ 1847 versionReleaseCandidate_DBPC "DBPC";
BA_ "GatewayedSignal" SG_ 1847 versionBootReleaseCandidate_DBPC 1;
BA_ "OriginatingECU" SG_ 1847 versionBootReleaseCandidate_DBPC "DBPC";
BA_ "GatewayedSignal" SG_ 1847 componentNum_DBPC 1;
BA_ "OriginatingECU" SG_ 1847 componentNum_DBPC "DBPC";
BA_ "GatewayedSignal" SG_ 1847 idGitHashUpper_DBPC 1;
BA_ "OriginatingECU" SG_ 1847 idGitHashUpper_DBPC "DBPC";
BA_ "GatewayedSignal" SG_ 1847 idBootGitHashUpper_DBPC 1;
BA_ "OriginatingECU" SG_ 1847 idBootGitHashUpper_DBPC "DBPC";
BA_ "GatewayedSignal" SG_ 1847 idBuildMachine_DBPC 1;
BA_ "OriginatingECU" SG_ 1847 idBuildMachine_DBPC "DBPC";
BA_ "GatewayedSignal" SG_ 1847 versionSubMinor_DBPC 1;
BA_ "OriginatingECU" SG_ 1847 versionSubMinor_DBPC "DBPC";
BA_ "GatewayedSignal" SG_ 1847 versionMinor_DBPC 1;
BA_ "OriginatingECU" SG_ 1847 versionMinor_DBPC "DBPC";
BA_ "GatewayedSignal" SG_ 1847 versionMajor_DBPC 1;
BA_ "OriginatingECU" SG_ 1847 versionMajor_DBPC "DBPC";
BA_ "GatewayedSignal" SG_ 1847 idBootBuildMachine_DBPC 1;
BA_ "OriginatingECU" SG_ 1847 idBootBuildMachine_DBPC "DBPC";
BA_ "GatewayedSignal" SG_ 1847 versionBootSubMinor_DBPC 1;
BA_ "OriginatingECU" SG_ 1847 versionBootSubMinor_DBPC "DBPC";
BA_ "GatewayedSignal" SG_ 1847 versionBootMinor_DBPC 1;
BA_ "OriginatingECU" SG_ 1847 versionBootMinor_DBPC "DBPC";
BA_ "GatewayedSignal" SG_ 1847 versionBootMajor_DBPC 1;
BA_ "OriginatingECU" SG_ 1847 versionBootMajor_DBPC "DBPC";
BA_ "GenSigSendType" SG_ 1858 hardwarePartNumber_FFL 1;
BA_ "GenSigSendType" SG_ 1858 hardwareRevisionId_FFL 1;
BA_ "GenSigSendType" SG_ 1858 bootloaderStuckSignal_FFL 1;
BA_ "GenSigSendType" SG_ 1858 resetCause_FFL 1;
BA_ "SNARequired" SG_ 1861 udsClientDataFFL_TOOL 1;
BA_ "GenSigSendType" SG_ 1861 udsClientDataFFL_TOOL 1;
BA_ "SNARequired" SG_ 1862 udsServerData_FFL 1;
BA_ "GenSigSendType" SG_ 1862 udsServerData_FFL 1;
BA_ "GatewayedSignal" SG_ 1863 versionReleaseCandidate_FFL 1;
BA_ "OriginatingECU" SG_ 1863 versionReleaseCandidate_FFL "FFL";
BA_ "GatewayedSignal" SG_ 1863 versionBootReleaseCandidate_FFL 1;
BA_ "OriginatingECU" SG_ 1863 versionBootReleaseCandidate_FFL "FFL";
BA_ "GatewayedSignal" SG_ 1863 componentNum_FFL 1;
BA_ "OriginatingECU" SG_ 1863 componentNum_FFL "FFL";
BA_ "GatewayedSignal" SG_ 1863 idGitHashUpper_FFL 1;
BA_ "OriginatingECU" SG_ 1863 idGitHashUpper_FFL "FFL";
BA_ "GatewayedSignal" SG_ 1863 idBootGitHashUpper_FFL 1;
BA_ "OriginatingECU" SG_ 1863 idBootGitHashUpper_FFL "FFL";
BA_ "GatewayedSignal" SG_ 1863 idBuildMachine_FFL 1;
BA_ "OriginatingECU" SG_ 1863 idBuildMachine_FFL "FFL";
BA_ "GatewayedSignal" SG_ 1863 versionSubMinor_FFL 1;
BA_ "OriginatingECU" SG_ 1863 versionSubMinor_FFL "FFL";
BA_ "GatewayedSignal" SG_ 1863 versionMinor_FFL 1;
BA_ "OriginatingECU" SG_ 1863 versionMinor_FFL "FFL";
BA_ "GatewayedSignal" SG_ 1863 versionMajor_FFL 1;
BA_ "OriginatingECU" SG_ 1863 versionMajor_FFL "FFL";
BA_ "GatewayedSignal" SG_ 1863 idBootBuildMachine_FFL 1;
BA_ "OriginatingECU" SG_ 1863 idBootBuildMachine_FFL "FFL";
BA_ "GatewayedSignal" SG_ 1863 versionBootSubMinor_FFL 1;
BA_ "OriginatingECU" SG_ 1863 versionBootSubMinor_FFL "FFL";
BA_ "GatewayedSignal" SG_ 1863 versionBootMinor_FFL 1;
BA_ "OriginatingECU" SG_ 1863 versionBootMinor_FFL "FFL";
BA_ "GatewayedSignal" SG_ 1863 versionBootMajor_FFL 1;
BA_ "OriginatingECU" SG_ 1863 versionBootMajor_FFL "FFL";
BA_ "GenSigSendType" SG_ 1866 hardwarePartNumber_FLDC 1;
BA_ "GenSigSendType" SG_ 1866 hardwareRevisionId_FLDC 1;
BA_ "GenSigSendType" SG_ 1866 bootloaderStuckSignal_FLDC 1;
BA_ "GenSigSendType" SG_ 1866 resetCause_FLDC 1;
BA_ "SNARequired" SG_ 1869 udsClientDataFLDC_TOOL 1;
BA_ "GenSigSendType" SG_ 1869 udsClientDataFLDC_TOOL 1;
BA_ "SNARequired" SG_ 1870 udsServerData_FLDC 1;
BA_ "GenSigSendType" SG_ 1870 udsServerData_FLDC 1;
BA_ "GatewayedSignal" SG_ 1871 versionReleaseCandidate_FLDC 1;
BA_ "OriginatingECU" SG_ 1871 versionReleaseCandidate_FLDC "FLDC";
BA_ "GatewayedSignal" SG_ 1871 versionBootReleaseCandidate_FLDC 1;
BA_ "OriginatingECU" SG_ 1871 versionBootReleaseCandidate_FLDC "FLDC";
BA_ "GatewayedSignal" SG_ 1871 componentNum_FLDC 1;
BA_ "OriginatingECU" SG_ 1871 componentNum_FLDC "FLDC";
BA_ "GatewayedSignal" SG_ 1871 idGitHashUpper_FLDC 1;
BA_ "OriginatingECU" SG_ 1871 idGitHashUpper_FLDC "FLDC";
BA_ "GatewayedSignal" SG_ 1871 idBootGitHashUpper_FLDC 1;
BA_ "OriginatingECU" SG_ 1871 idBootGitHashUpper_FLDC "FLDC";
BA_ "GatewayedSignal" SG_ 1871 idBuildMachine_FLDC 1;
BA_ "OriginatingECU" SG_ 1871 idBuildMachine_FLDC "FLDC";
BA_ "GatewayedSignal" SG_ 1871 versionSubMinor_FLDC 1;
BA_ "OriginatingECU" SG_ 1871 versionSubMinor_FLDC "FLDC";
BA_ "GatewayedSignal" SG_ 1871 versionMinor_FLDC 1;
BA_ "OriginatingECU" SG_ 1871 versionMinor_FLDC "FLDC";
BA_ "GatewayedSignal" SG_ 1871 versionMajor_FLDC 1;
BA_ "OriginatingECU" SG_ 1871 versionMajor_FLDC "FLDC";
BA_ "GatewayedSignal" SG_ 1871 idBootBuildMachine_FLDC 1;
BA_ "OriginatingECU" SG_ 1871 idBootBuildMachine_FLDC "FLDC";
BA_ "GatewayedSignal" SG_ 1871 versionBootSubMinor_FLDC 1;
BA_ "OriginatingECU" SG_ 1871 versionBootSubMinor_FLDC "FLDC";
BA_ "GatewayedSignal" SG_ 1871 versionBootMinor_FLDC 1;
BA_ "OriginatingECU" SG_ 1871 versionBootMinor_FLDC "FLDC";
BA_ "GatewayedSignal" SG_ 1871 versionBootMajor_FLDC 1;
BA_ "OriginatingECU" SG_ 1871 versionBootMajor_FLDC "FLDC";
BA_ "GenSigSendType" SG_ 1874 hardwarePartNumber_FRDC 1;
BA_ "GenSigSendType" SG_ 1874 hardwareRevisionId_FRDC 1;
BA_ "GenSigSendType" SG_ 1874 bootloaderStuckSignal_FRDC 1;
BA_ "GenSigSendType" SG_ 1874 resetCause_FRDC 1;
BA_ "SNARequired" SG_ 1877 udsClientDataFRDC_TOOL 1;
BA_ "GenSigSendType" SG_ 1877 udsClientDataFRDC_TOOL 1;
BA_ "SNARequired" SG_ 1878 udsServerData_FRDC 1;
BA_ "GenSigSendType" SG_ 1878 udsServerData_FRDC 1;
BA_ "GatewayedSignal" SG_ 1879 versionReleaseCandidate_FRDC 1;
BA_ "OriginatingECU" SG_ 1879 versionReleaseCandidate_FRDC "FRDC";
BA_ "GatewayedSignal" SG_ 1879 versionBootReleaseCandidate_FRDC 1;
BA_ "OriginatingECU" SG_ 1879 versionBootReleaseCandidate_FRDC "FRDC";
BA_ "GatewayedSignal" SG_ 1879 componentNum_FRDC 1;
BA_ "OriginatingECU" SG_ 1879 componentNum_FRDC "FRDC";
BA_ "GatewayedSignal" SG_ 1879 idGitHashUpper_FRDC 1;
BA_ "OriginatingECU" SG_ 1879 idGitHashUpper_FRDC "FRDC";
BA_ "GatewayedSignal" SG_ 1879 idBootGitHashUpper_FRDC 1;
BA_ "OriginatingECU" SG_ 1879 idBootGitHashUpper_FRDC "FRDC";
BA_ "GatewayedSignal" SG_ 1879 idBuildMachine_FRDC 1;
BA_ "OriginatingECU" SG_ 1879 idBuildMachine_FRDC "FRDC";
BA_ "GatewayedSignal" SG_ 1879 versionSubMinor_FRDC 1;
BA_ "OriginatingECU" SG_ 1879 versionSubMinor_FRDC "FRDC";
BA_ "GatewayedSignal" SG_ 1879 versionMinor_FRDC 1;
BA_ "OriginatingECU" SG_ 1879 versionMinor_FRDC "FRDC";
BA_ "GatewayedSignal" SG_ 1879 versionMajor_FRDC 1;
BA_ "OriginatingECU" SG_ 1879 versionMajor_FRDC "FRDC";
BA_ "GatewayedSignal" SG_ 1879 idBootBuildMachine_FRDC 1;
BA_ "OriginatingECU" SG_ 1879 idBootBuildMachine_FRDC "FRDC";
BA_ "GatewayedSignal" SG_ 1879 versionBootSubMinor_FRDC 1;
BA_ "OriginatingECU" SG_ 1879 versionBootSubMinor_FRDC "FRDC";
BA_ "GatewayedSignal" SG_ 1879 versionBootMinor_FRDC 1;
BA_ "OriginatingECU" SG_ 1879 versionBootMinor_FRDC "FRDC";
BA_ "GatewayedSignal" SG_ 1879 versionBootMajor_FRDC 1;
BA_ "OriginatingECU" SG_ 1879 versionBootMajor_FRDC "FRDC";
BA_ "GenSigSendType" SG_ 1882 hardwarePartNumber_RLDC 1;
BA_ "GenSigSendType" SG_ 1882 hardwareRevisionId_RLDC 1;
BA_ "GenSigSendType" SG_ 1882 bootloaderStuckSignal_RLDC 1;
BA_ "GenSigSendType" SG_ 1882 resetCause_RLDC 1;
BA_ "SNARequired" SG_ 1885 udsClientDataRLDC_TOOL 1;
BA_ "GenSigSendType" SG_ 1885 udsClientDataRLDC_TOOL 1;
BA_ "SNARequired" SG_ 1886 udsServerData_RLDC 1;
BA_ "GenSigSendType" SG_ 1886 udsServerData_RLDC 1;
BA_ "GatewayedSignal" SG_ 1887 versionReleaseCandidate_RLDC 1;
BA_ "OriginatingECU" SG_ 1887 versionReleaseCandidate_RLDC "RLDC";
BA_ "GatewayedSignal" SG_ 1887 versionBootReleaseCandidate_RLDC 1;
BA_ "OriginatingECU" SG_ 1887 versionBootReleaseCandidate_RLDC "RLDC";
BA_ "GatewayedSignal" SG_ 1887 componentNum_RLDC 1;
BA_ "OriginatingECU" SG_ 1887 componentNum_RLDC "RLDC";
BA_ "GatewayedSignal" SG_ 1887 idGitHashUpper_RLDC 1;
BA_ "OriginatingECU" SG_ 1887 idGitHashUpper_RLDC "RLDC";
BA_ "GatewayedSignal" SG_ 1887 idBootGitHashUpper_RLDC 1;
BA_ "OriginatingECU" SG_ 1887 idBootGitHashUpper_RLDC "RLDC";
BA_ "GatewayedSignal" SG_ 1887 idBuildMachine_RLDC 1;
BA_ "OriginatingECU" SG_ 1887 idBuildMachine_RLDC "RLDC";
BA_ "GatewayedSignal" SG_ 1887 versionSubMinor_RLDC 1;
BA_ "OriginatingECU" SG_ 1887 versionSubMinor_RLDC "RLDC";
BA_ "GatewayedSignal" SG_ 1887 versionMinor_RLDC 1;
BA_ "OriginatingECU" SG_ 1887 versionMinor_RLDC "RLDC";
BA_ "GatewayedSignal" SG_ 1887 versionMajor_RLDC 1;
BA_ "OriginatingECU" SG_ 1887 versionMajor_RLDC "RLDC";
BA_ "GatewayedSignal" SG_ 1887 idBootBuildMachine_RLDC 1;
BA_ "OriginatingECU" SG_ 1887 idBootBuildMachine_RLDC "RLDC";
BA_ "GatewayedSignal" SG_ 1887 versionBootSubMinor_RLDC 1;
BA_ "OriginatingECU" SG_ 1887 versionBootSubMinor_RLDC "RLDC";
BA_ "GatewayedSignal" SG_ 1887 versionBootMinor_RLDC 1;
BA_ "OriginatingECU" SG_ 1887 versionBootMinor_RLDC "RLDC";
BA_ "GatewayedSignal" SG_ 1887 versionBootMajor_RLDC 1;
BA_ "OriginatingECU" SG_ 1887 versionBootMajor_RLDC "RLDC";
BA_ "GenSigSendType" SG_ 1890 hardwarePartNumber_RRDC 1;
BA_ "GenSigSendType" SG_ 1890 hardwareRevisionId_RRDC 1;
BA_ "GenSigSendType" SG_ 1890 bootloaderStuckSignal_RRDC 1;
BA_ "GenSigSendType" SG_ 1890 resetCause_RRDC 1;
BA_ "SNARequired" SG_ 1893 udsClientDataRRDC_TOOL 1;
BA_ "GenSigSendType" SG_ 1893 udsClientDataRRDC_TOOL 1;
BA_ "SNARequired" SG_ 1894 udsServerData_RRDC 1;
BA_ "GenSigSendType" SG_ 1894 udsServerData_RRDC 1;
BA_ "GatewayedSignal" SG_ 1895 versionReleaseCandidate_RRDC 1;
BA_ "OriginatingECU" SG_ 1895 versionReleaseCandidate_RRDC "RRDC";
BA_ "GatewayedSignal" SG_ 1895 versionBootReleaseCandidate_RRDC 1;
BA_ "OriginatingECU" SG_ 1895 versionBootReleaseCandidate_RRDC "RRDC";
BA_ "GatewayedSignal" SG_ 1895 componentNum_RRDC 1;
BA_ "OriginatingECU" SG_ 1895 componentNum_RRDC "RRDC";
BA_ "GatewayedSignal" SG_ 1895 idGitHashUpper_RRDC 1;
BA_ "OriginatingECU" SG_ 1895 idGitHashUpper_RRDC "RRDC";
BA_ "GatewayedSignal" SG_ 1895 idBootGitHashUpper_RRDC 1;
BA_ "OriginatingECU" SG_ 1895 idBootGitHashUpper_RRDC "RRDC";
BA_ "GatewayedSignal" SG_ 1895 idBuildMachine_RRDC 1;
BA_ "OriginatingECU" SG_ 1895 idBuildMachine_RRDC "RRDC";
BA_ "GatewayedSignal" SG_ 1895 versionSubMinor_RRDC 1;
BA_ "OriginatingECU" SG_ 1895 versionSubMinor_RRDC "RRDC";
BA_ "GatewayedSignal" SG_ 1895 versionMinor_RRDC 1;
BA_ "OriginatingECU" SG_ 1895 versionMinor_RRDC "RRDC";
BA_ "GatewayedSignal" SG_ 1895 versionMajor_RRDC 1;
BA_ "OriginatingECU" SG_ 1895 versionMajor_RRDC "RRDC";
BA_ "GatewayedSignal" SG_ 1895 idBootBuildMachine_RRDC 1;
BA_ "OriginatingECU" SG_ 1895 idBootBuildMachine_RRDC "RRDC";
BA_ "GatewayedSignal" SG_ 1895 versionBootSubMinor_RRDC 1;
BA_ "OriginatingECU" SG_ 1895 versionBootSubMinor_RRDC "RRDC";
BA_ "GatewayedSignal" SG_ 1895 versionBootMinor_RRDC 1;
BA_ "OriginatingECU" SG_ 1895 versionBootMinor_RRDC "RRDC";
BA_ "GatewayedSignal" SG_ 1895 versionBootMajor_RRDC 1;
BA_ "OriginatingECU" SG_ 1895 versionBootMajor_RRDC "RRDC";
BA_ "GenSigSendType" SG_ 2041 nmPartialNetworks_BGW 1;
BA_ "GenSigSendType" SG_ 2041 nmActiveWake_BGW 1;
BA_ "GenSigSendType" SG_ 2041 nmID_BGW 1;
BA_ "GenSigSendType" SG_ 2041 nmPnBody_BGW 1;
BA_ "GenSigSendType" SG_ 2041 nmPnCharging_BGW 1;
BA_ "GenSigSendType" SG_ 2041 nmPnHazard_BGW 1;
BA_ "GenSigSendType" SG_ 2041 nmPnKeypad_BGW 1;
BA_ "GenSigSendType" SG_ 2047 udsFunctionalRequestData_TOOL 1;
VAL_ 1088 lighttemperatureStatus_HLL 3 "SNA" 2 "Under" 1 "Over" 0 "Ok" ;
VAL_ 1088 lightDRLStatus_HLL 3 "SNA" 2 "LightFault" 1 "LightOn" 0 "LightOff" ;
VAL_ 1088 lightLowBeamStatus_HLL 3 "SNA" 2 "LightFault" 1 "LightOn" 0 "LightOff" ;
VAL_ 1088 lightPosStatus_HLL 3 "SNA" 2 "LightFault" 1 "LightOn" 0 "LightOff" ;
VAL_ 1088 lightHighBeamStatus_HLL 3 "SNA" 2 "LightFault" 1 "LightOn" 0 "LightOff" ;
VAL_ 1088 lightTurnStatus_HLL 3 "SNA" 2 "LightFault" 1 "LightOn" 0 "LightOff" ;
VAL_ 1096 lightDRLStatus_HLR 3 "SNA" 2 "LightFault" 1 "LightOn" 0 "LightOff" ;
VAL_ 1096 lightLowBeamStatus_HLR 3 "SNA" 2 "LightFault" 1 "LightOn" 0 "LightOff" ;
VAL_ 1096 lightHighBeamStatus_HLR 3 "SNA" 2 "LightFault" 1 "LightOn" 0 "LightOff" ;
VAL_ 1096 lighttemperatureStatus_HLR 3 "SNA" 2 "Under" 1 "Over" 0 "Ok" ;
VAL_ 1096 lightPosStatus_HLR 3 "SNA" 2 "LightFault" 1 "LightOn" 0 "LightOff" ;
VAL_ 1096 lightTurnStatus_HLR 3 "SNA" 2 "LightFault" 1 "LightOn" 0 "LightOff" ;
VAL_ 680 doorLockReq_DCRL 3 "SNA" 2 "LockRequest" 1 "UnlockRequest" 0 "NoRequest" ;
VAL_ 680 lockUnlockReq_RLLUS 3 "SNA" 2 "LockRequest" 1 "UnlockRequest" 0 "NoRequest" ;
VAL_ 680 doorSafeMode_DCRL 3 "SNA" 1 "SafeMode" 0 "NormalMode" ;
VAL_ 680 doorLatchPawlOpen_DCRL 3 "SNA" 2 "Error" 1 "On" 0 "Off" ;
VAL_ 680 doorLatchFault_DCRL 3 "SNA" 1 "True" 0 "False" ;
VAL_ 680 childLockButtonState_DCRL 3 "SNA" 2 "NoChange" 1 "Unlock" 0 "Lock" ;
VAL_ 680 doorIsUnlatched_DCRL 3 "SNA" 1 "True" 0 "False" ;
VAL_ 680 doorExtSwitch_DCRL 3 "SNA" 1 "True" 0 "False" ;
VAL_ 680 doorMirrorState_DCRL 7 "SNA" 4 "Retracting" 3 "Retracted" 2 "Presenting" 1 "Presented" 0 "Unknown" ;
VAL_ 680 doorState_DCRL 15 "SNA" 9 "DoorCinchingFailure" 8 "DoorUnlatchingError" 7 "DoorClosingError" 6 "DoorOpeningError" 5 "DoorClosingObstruction" 4 "DoorOpeningObstruction" 3 "DoorClosing" 2 "DoorOpening" 1 "DoorOpen" 0 "DoorClosed" ;
VAL_ 680 mirrorHeaterState_DCRL 3 "SNA" 2 "Fault" 1 "On" 0 "Off" ;
VAL_ 680 sideRepeaterState_DCRL 3 "SNA" 2 "LightFault" 1 "LightOn" 0 "LightOff" ;
VAL_ 680 windowStatusRl_DCRL 5 "TempShutoff" 7 "SNA" 4 "Error" 3 "WindowRollingDown" 2 "WindowRollingUp" 1 "WindowOpen" 0 "WindowClosed" ;
VAL_ 680 mirrorFoldFeedbackLeft_DCRL 3 "SNA" 2 "FoldIn" 1 "FoldOut" 0 "NoCommand" ;
VAL_ 680 mirrorDefrostGlassStatusLh_DCRL 3 "SNA" 2 "Error" 1 "On" 0 "Off" ;
VAL_ 680 mirrorStatusMovUpDownLeft_DCRL 3 "SNA" 2 "MovingDown" 1 "MovingUp" 0 "NotMoving" ;
VAL_ 680 mirrorStatusMovInOutLeft_DCRL 3 "SNA" 2 "MovingOut" 1 "MovingIn" 0 "NotMoving" ;
VAL_ 680 mirrorDefrostCamStatusLeft_DCRL 3 "SNA" 2 "Error" 1 "On" 0 "Off" ;
VAL_ 680 errorAMPRL_DCRL 1 "True" 0 "False" ;
VAL_ 680 errorALDRL_DCRL 1 "True" 0 "False" ;
VAL_ 680 wakeUpCause_DCRL 7 "SNA" 4 "Bgw" 3 "ExtDoorOpenSw" 2 "IntOpenCloseSw" 1 "IntDoorReleaseSw" 0 "Unknown" ;
VAL_ 681 windowReqAll_DCRL 7 "SNA" 6 "AutoUp" 5 "AutoDown" 2 "PropUp" 1 "PropDown" 0 "NoCommand" ;
VAL_ 681 windowReqRearLeft_DCRL 7 "SNA" 6 "AutoUp" 5 "AutoDown" 2 "PropUp" 1 "PropDown" 0 "NoCommand" ;
VAL_ 681 windowReqRearRight_DCRL 7 "SNA" 6 "AutoUp" 5 "AutoDown" 2 "PropUp" 1 "PropDown" 0 "NoCommand" ;
VAL_ 681 windowReqFrontLeft_DCRL 7 "SNA" 6 "AutoUp" 5 "AutoDown" 2 "PropUp" 1 "PropDown" 0 "NoCommand" ;
VAL_ 681 windowReqFrontRight_DCRL 7 "SNA" 6 "AutoUp" 5 "AutoDown" 2 "PropUp" 1 "PropDown" 0 "NoCommand" ;
VAL_ 712 doorLockReq_DCRR 3 "SNA" 2 "LockRequest" 1 "UnlockRequest" 0 "NoRequest" ;
VAL_ 712 lockUnlockReq_RRLUS 3 "SNA" 2 "LockRequest" 1 "UnlockRequest" 0 "NoRequest" ;
VAL_ 712 doorSafeMode_DCRR 3 "SNA" 1 "SafeMode" 0 "NormalMode" ;
VAL_ 712 doorLatchPawlOpen_DCRR 3 "SNA" 2 "Error" 1 "On" 0 "Off" ;
VAL_ 712 doorLatchFault_DCRR 3 "SNA" 1 "True" 0 "False" ;
VAL_ 712 childLockButtonState_DCRR 3 "SNA" 2 "NoChange" 1 "Unlock" 0 "Lock" ;
VAL_ 712 doorIsUnlatched_DCRR 3 "SNA" 1 "True" 0 "False" ;
VAL_ 712 doorExtSwitch_DCRR 3 "SNA" 1 "True" 0 "False" ;
VAL_ 712 doorMirrorState_DCRR 7 "SNA" 4 "Retracting" 3 "Retracted" 2 "Presenting" 1 "Presented" 0 "Unknown" ;
VAL_ 712 doorState_DCRR 15 "SNA" 9 "DoorCinchingFailure" 8 "DoorUnlatchingError" 7 "DoorClosingError" 6 "DoorOpeningError" 5 "DoorClosingObstruction" 4 "DoorOpeningObstruction" 3 "DoorClosing" 2 "DoorOpening" 1 "DoorOpen" 0 "DoorClosed" ;
VAL_ 712 mirrorHeaterState_DCRR 3 "SNA" 2 "Fault" 1 "On" 0 "Off" ;
VAL_ 712 sideRepeaterState_DCRR 3 "SNA" 2 "LightFault" 1 "LightOn" 0 "LightOff" ;
VAL_ 712 windowStatusRr_DCRR 5 "TempShutoff" 7 "SNA" 4 "Error" 3 "WindowRollingDown" 2 "WindowRollingUp" 1 "WindowOpen" 0 "WindowClosed" ;
VAL_ 712 mirrorFoldFeedbackRight_DCRR 3 "SNA" 2 "FoldIn" 1 "FoldOut" 0 "NoCommand" ;
VAL_ 712 mirrorDefrostGlassStatusRh_DCRR 3 "SNA" 2 "Error" 1 "On" 0 "Off" ;
VAL_ 712 mirrorStatusMovUpDownRight_DCRR 3 "SNA" 2 "MovingDown" 1 "MovingUp" 0 "NotMoving" ;
VAL_ 712 mirrorStatusMovInOutRight_DCRR 3 "SNA" 2 "MovingOut" 1 "MovingIn" 0 "NotMoving" ;
VAL_ 712 mirrorDefrostCamStatusRight_DCRR 3 "SNA" 2 "Error" 1 "On" 0 "Off" ;
VAL_ 712 errorAMPRR_DCRR 1 "True" 0 "False" ;
VAL_ 712 errorALDRR_DCRR 1 "True" 0 "False" ;
VAL_ 712 wakeUpCause_DCRR 7 "SNA" 4 "Bgw" 3 "ExtDoorOpenSw" 2 "IntOpenCloseSw" 1 "IntDoorReleaseSw" 0 "Unknown" ;
VAL_ 713 windowReqAll_DCRR 7 "SNA" 6 "AutoUp" 5 "AutoDown" 2 "PropUp" 1 "PropDown" 0 "NoCommand" ;
VAL_ 713 windowReqRearLeft_DCRR 7 "SNA" 6 "AutoUp" 5 "AutoDown" 2 "PropUp" 1 "PropDown" 0 "NoCommand" ;
VAL_ 713 windowReqRearRight_DCRR 7 "SNA" 6 "AutoUp" 5 "AutoDown" 2 "PropUp" 1 "PropDown" 0 "NoCommand" ;
VAL_ 713 windowReqFrontLeft_DCRR 7 "SNA" 6 "AutoUp" 5 "AutoDown" 2 "PropUp" 1 "PropDown" 0 "NoCommand" ;
VAL_ 713 windowReqFrontRight_DCRR 7 "SNA" 6 "AutoUp" 5 "AutoDown" 2 "PropUp" 1 "PropDown" 0 "NoCommand" ;
VAL_ 1259 lightReverseStatus_LGL 3 "SNA" 2 "LightFault" 1 "LightOn" 0 "LightOff" ;
VAL_ 1259 lightSMarkerStatus_LGL 3 "SNA" 2 "LightFault" 1 "LightOn" 0 "LightOff" ;
VAL_ 1259 lightPosStatus_LGL 3 "SNA" 2 "LightFault" 1 "LightOn" 0 "LightOff" ;
VAL_ 1259 lighttemperatureStatus_LGL 3 "SNA" 2 "Under" 1 "Over" 0 "Ok" ;
VAL_ 1273 lightTurnStatus_RCLL 3 "SNA" 2 "LightFault" 1 "LightOn" 0 "LightOff" ;
VAL_ 1273 lightSMarkerStatus_RCLL 3 "SNA" 2 "LightFault" 1 "LightOn" 0 "LightOff" ;
VAL_ 1273 lightPosStatus_RCLL 3 "SNA" 2 "LightFault" 1 "LightOn" 0 "LightOff" ;
VAL_ 1273 lighttemperatureStatus_RCLL 3 "SNA" 2 "Under" 1 "Over" 0 "Ok" ;
VAL_ 1273 lightStopStatus_RCLL 3 "SNA" 2 "LightFault" 1 "LightOn" 0 "LightOff" ;
VAL_ 1281 lightSMarkerStatus_RCLR 3 "SNA" 2 "LightFault" 1 "LightOn" 0 "LightOff" ;
VAL_ 1281 lightTurnStatus_RCLR 3 "SNA" 2 "LightFault" 1 "LightOn" 0 "LightOff" ;
VAL_ 1281 lightPosStatus_RCLR 3 "SNA" 2 "LightFault" 1 "LightOn" 0 "LightOff" ;
VAL_ 1281 lighttemperatureStatus_RCLR 3 "SNA" 2 "Under" 1 "Over" 0 "Ok" ;
VAL_ 1281 lightStopStatus_RCLR 3 "SNA" 2 "LightFault" 1 "LightOn" 0 "LightOff" ;
VAL_ 1290 seatCushionMassageCmdRL_BGW 3 "SNA" 1 "On" 0 "Off" ;
VAL_ 1290 seatCushionMassageCmdRR_BGW 3 "SNA" 1 "On" 0 "Off" ;
VAL_ 1290 seatBackMassageCmdRR_BGW 3 "SNA" 1 "On" 0 "Off" ;
VAL_ 1290 seatBackMassageCmdRL_BGW 3 "SNA" 1 "On" 0 "Off" ;
VAL_ 1290 seatCushionMassageCmdFR_BGW 3 "SNA" 1 "On" 0 "Off" ;
VAL_ 1290 seatBackMassageCmdFR_BGW 3 "SNA" 1 "On" 0 "Off" ;
VAL_ 1290 seatCushionMassageCmdFL_BGW 3 "SNA" 1 "On" 0 "Off" ;
VAL_ 1290 seatBackMassageCmdFL_BGW 3 "SNA" 1 "On" 0 "Off" ;
VAL_ 1290 seatMassageTypeCmdRR_BGW 7 "SNA" 3 "Type3" 2 "Type2" 1 "Type1" 0 "Off" ;
VAL_ 1290 seatMassageIntensityCmdRR_BGW 7 "SNA" 5 "5" 4 "4" 3 "3" 2 "2" 1 "1" 0 "0" ;
VAL_ 1290 seatHeatVentCmdRR_BGW 7 "SNA" 6 "VentHigh" 5 "VentMedium" 4 "VentLow" 3 "HeatHigh" 2 "HeatMedium" 1 "HeatLow" 0 "Off" ;
VAL_ 1290 seatMassageTypeCmdRL_BGW 7 "SNA" 3 "Type3" 2 "Type2" 1 "Type1" 0 "Off" ;
VAL_ 1290 seatMassageIntensityCmdRL_BGW 7 "SNA" 5 "5" 4 "4" 3 "3" 2 "2" 1 "1" 0 "0" ;
VAL_ 1290 seatHeatVentCmdRL_BGW 7 "SNA" 6 "VentHigh" 5 "VentMedium" 4 "VentLow" 3 "HeatHigh" 2 "HeatMedium" 1 "HeatLow" 0 "Off" ;
VAL_ 1290 seatMassageTypeCmdFR_BGW 7 "SNA" 3 "Type3" 2 "Type2" 1 "Type1" 0 "Off" ;
VAL_ 1290 seatMassageIntensityCmdFR_BGW 7 "SNA" 5 "5" 4 "4" 3 "3" 2 "2" 1 "1" 0 "0" ;
VAL_ 1290 seatHeatVentCmdFR_BGW 7 "SNA" 6 "VentHigh" 5 "VentMedium" 4 "VentLow" 3 "HeatHigh" 2 "HeatMedium" 1 "HeatLow" 0 "Off" ;
VAL_ 1290 seatHeatVentCmdFL_BGW 7 "SNA" 6 "VentHigh" 5 "VentMedium" 4 "VentLow" 3 "HeatHigh" 2 "HeatMedium" 1 "HeatLow" 0 "Off" ;
VAL_ 1290 seatMassageIntensityCmdFL_BGW 7 "SNA" 5 "5" 4 "4" 3 "3" 2 "2" 1 "1" 0 "0" ;
VAL_ 1290 seatMassageTypeCmdFL_BGW 7 "SNA" 3 "Type3" 2 "Type2" 1 "Type1" 0 "Off" ;
VAL_ 1298 lightPosStatus_ACCL 3 "SNA" 2 "LightFault" 1 "LightOn" 0 "LightOff" ;
VAL_ 1328 cpdOperation_DBPC 15 "SNA" 7 "PopDoor" 4 "DoorClose" 3 "DoorOpen" 1 "DoorStop" 0 "NoAction" ;
VAL_ 1328 doorLockReq_DBPC 3 "SNA" 2 "NoChange" 1 "Unlock" 0 "Lock" ;
VAL_ 1328 doorRROperation_DBPC 15 "SNA" 7 "PopDoor" 4 "DoorClose" 3 "DoorOpen" 1 "DoorStop" 0 "NoAction" ;
VAL_ 1328 doorRLOperation_DBPC 15 "SNA" 7 "PopDoor" 4 "DoorClose" 3 "DoorOpen" 1 "DoorStop" 0 "NoAction" ;
VAL_ 1328 doorFROperation_DBPC 15 "SNA" 7 "PopDoor" 4 "DoorClose" 3 "DoorOpen" 1 "DoorStop" 0 "NoAction" ;
VAL_ 1328 doorFLOperation_DBPC 15 "SNA" 7 "PopDoor" 4 "DoorClose" 3 "DoorOpen" 1 "DoorStop" 0 "NoAction" ;
VAL_ 1328 liftgateOperation_DBPC 15 "SNA" 7 "PopDoor" 4 "DoorClose" 3 "DoorOpen" 1 "DoorStop" 0 "NoAction" ;
VAL_ 1328 frunkLockReq_DBPC 3 "SNA" 2 "LockRequest" 1 "UnlockRequest" 0 "NoRequest" ;
VAL_ 1328 liftgateLockReq_DBPC 3 "SNA" 2 "LockRequest" 1 "UnlockRequest" 0 "NoRequest" ;
VAL_ 1328 doorRRLockReq_DBPC 3 "SNA" 2 "LockRequest" 1 "UnlockRequest" 0 "NoRequest" ;
VAL_ 1328 doorRLLockReq_DBPC 3 "SNA" 2 "LockRequest" 1 "UnlockRequest" 0 "NoRequest" ;
VAL_ 1328 doorFRLockReq_DBPC 3 "SNA" 2 "LockRequest" 1 "UnlockRequest" 0 "NoRequest" ;
VAL_ 1328 doorFLLockReq_DBPC 3 "SNA" 2 "LockRequest" 1 "UnlockRequest" 0 "NoRequest" ;
VAL_ 1344 sequenceStatus_FFL 3 "SNA" 1 "Running" 0 "NotRunning" ;
VAL_ 1344 sequenceIDStatus_FFL 255 "SNA" 99 "Null" 98 "PreparingToCharge" 97 "ChargingInProgress" 96 "ChargingErrorState" 95 "BatteryLowState" 94 "ScheduleToCharge" 93 "PickupMode" 92 "Awake" 91 "Unlock" 90 "Lock" 89 "GoodBye" 88 "OpenLeftFront" 87 "CloseLeftFront" 86 "OpenRightFront" 85 "CloseRightFront" 84 "OpenLeftRear" 83 "CloseLeftRear" 82 "OpenRightRear" 81 "CloseRightRear" 80 "DriveDefault" 79 "DriveEce" 78 "DriveFmvss" 77 "DriveCcc" ;
VAL_ 1352 ledStatus_FLDC 3 "SNA" 1 "Failure" 0 "Ok" ;
VAL_ 1352 temperatureStatus_FLDC 3 "SNA" 2 "UnderTemperature" 1 "OverTemperature" 0 "Ok" ;
VAL_ 1352 sequenceIDStatus_FLDC 255 "SNA" 99 "Null" 98 "PreparingToCharge" 97 "ChargingInProgress" 96 "ChargingErrorState" 95 "BatteryLowState" 94 "ScheduleToCharge" 93 "PickupMode" 92 "Awake" 91 "Unlock" 90 "Lock" 89 "GoodBye" 88 "OpenLeftFront" 87 "CloseLeftFront" 86 "OpenRightFront" 85 "CloseRightFront" 84 "OpenLeftRear" 83 "CloseLeftRear" 82 "OpenRightRear" 81 "CloseRightRear" 80 "DriveDefault" 79 "DriveEce" 78 "DriveFmvss" 77 "DriveCcc" ;
VAL_ 1360 ledStatus_FRDC 3 "SNA" 1 "Failure" 0 "Ok" ;
VAL_ 1360 temperatureStatus_FRDC 3 "SNA" 2 "UnderTemperature" 1 "OverTemperature" 0 "Ok" ;
VAL_ 1360 sequenceIDStatus_FRDC 255 "SNA" 99 "Null" 98 "PreparingToCharge" 97 "ChargingInProgress" 96 "ChargingErrorState" 95 "BatteryLowState" 94 "ScheduleToCharge" 93 "PickupMode" 92 "Awake" 91 "Unlock" 90 "Lock" 89 "GoodBye" 88 "OpenLeftFront" 87 "CloseLeftFront" 86 "OpenRightFront" 85 "CloseRightFront" 84 "OpenLeftRear" 83 "CloseLeftRear" 82 "OpenRightRear" 81 "CloseRightRear" 80 "DriveDefault" 79 "DriveEce" 78 "DriveFmvss" 77 "DriveCcc" ;
VAL_ 1368 ledStatus_RLDC 3 "SNA" 1 "Failure" 0 "Ok" ;
VAL_ 1368 temperatureStatus_RLDC 3 "SNA" 2 "UnderTemperature" 1 "OverTemperature" 0 "Ok" ;
VAL_ 1368 sequenceIDStatus_RLDC 255 "SNA" 99 "Null" 98 "PreparingToCharge" 97 "ChargingInProgress" 96 "ChargingErrorState" 95 "BatteryLowState" 94 "ScheduleToCharge" 93 "PickupMode" 92 "Awake" 91 "Unlock" 90 "Lock" 89 "GoodBye" 88 "OpenLeftFront" 87 "CloseLeftFront" 86 "OpenRightFront" 85 "CloseRightFront" 84 "OpenLeftRear" 83 "CloseLeftRear" 82 "OpenRightRear" 81 "CloseRightRear" 80 "DriveDefault" 79 "DriveEce" 78 "DriveFmvss" 77 "DriveCcc" ;
VAL_ 1376 ledStatus_RRDC 3 "SNA" 1 "Failure" 0 "Ok" ;
VAL_ 1376 temperatureStatus_RRDC 3 "SNA" 2 "UnderTemperature" 1 "OverTemperature" 0 "Ok" ;
VAL_ 1376 sequenceIDStatus_RRDC 255 "SNA" 99 "Null" 98 "PreparingToCharge" 97 "ChargingInProgress" 96 "ChargingErrorState" 95 "BatteryLowState" 94 "ScheduleToCharge" 93 "PickupMode" 92 "Awake" 91 "Unlock" 90 "Lock" 89 "GoodBye" 88 "OpenLeftFront" 87 "CloseLeftFront" 86 "OpenRightFront" 85 "CloseRightFront" 84 "OpenLeftRear" 83 "CloseLeftRear" 82 "OpenRightRear" 81 "CloseRightRear" 80 "DriveDefault" 79 "DriveEce" 78 "DriveFmvss" 77 "DriveCcc" ;
VAL_ 364 switchStatusLeft_DOMEF 1 "On" 0 "Off" ;
VAL_ 364 switchStatusCenter_DOMEF 1 "On" 0 "Off" ;
VAL_ 364 switchStatusRight_DOMEF 1 "On" 0 "Off" ;
VAL_ 364 lightStatusLeft_DOMEF 1 "On" 0 "Off" ;
VAL_ 364 lightStatusCenter_DOMEF 1 "On" 0 "Off" ;
VAL_ 364 lightStatusRight_DOMEF 1 "On" 0 "Off" ;
VAL_ 364 error_DOMEF 1 "True" 0 "False" ;
VAL_ 364 switchStatus_DOMER 7 "SNA" 2 "LocalSwitchClosed" 1 "LocalSwitchOpen" 0 "NoSwitch" ;
VAL_ 364 lightStatus_DOMER 1 "On" 0 "Off" ;
VAL_ 364 error_DOMER 1 "True" 0 "False" ;
VAL_ 1166 redStatusAMPFR_DCFR 255 "SNA" ;
VAL_ 1166 greenStatusAMPFR_DCFR 255 "SNA" ;
VAL_ 1166 blueStatusAMPFR_DCFR 255 "SNA" ;
VAL_ 1166 routineStatusAMPFR_DCFR 255 "SNA" ;
VAL_ 1166 redStatusALDFR_DCFR 255 "SNA" ;
VAL_ 1166 greenStatusALDFR_DCFR 255 "SNA" ;
VAL_ 1166 blueStatusALDFR_DCFR 255 "SNA" ;
VAL_ 1166 routineStatusALDFR_DCFR 255 "SNA" ;
VAL_ 1198 redStatusAMPRL_DCRL 255 "SNA" ;
VAL_ 1198 greenStatusAMPRL_DCRL 255 "SNA" ;
VAL_ 1198 blueStatusAMPRL_DCRL 255 "SNA" ;
VAL_ 1198 routineStatusAMPRL_DCRL 255 "SNA" ;
VAL_ 1198 redStatusALDRL_DCRL 255 "SNA" ;
VAL_ 1198 greenStatusALDRL_DCRL 255 "SNA" ;
VAL_ 1198 blueStatusALDRL_DCRL 255 "SNA" ;
VAL_ 1198 routineStatusALDRL_DCRL 255 "SNA" ;
VAL_ 1230 redStatusAMPRR_DCRR 255 "SNA" ;
VAL_ 1230 greenStatusAMPRR_DCRR 255 "SNA" ;
VAL_ 1230 blueStatusAMPRR_DCRR 255 "SNA" ;
VAL_ 1230 routineStatusAMPRR_DCRR 255 "SNA" ;
VAL_ 1230 redStatusALDRR_DCRR 255 "SNA" ;
VAL_ 1230 greenStatusALDRR_DCRR 255 "SNA" ;
VAL_ 1230 blueStatusALDRR_DCRR 255 "SNA" ;
VAL_ 1230 routineStatusALDRR_DCRR 255 "SNA" ;
VAL_ 1546 bootloaderStuckSignal_BGW 255 "SNA" 18 "EcuSpecificReason3" 17 "EcuSpecificReason2" 16 "EcuSpecificReason1" 15 "Reserved12" 14 "Reserved11" 13 "Reserved10" 12 "Reserved9" 11 "Reserved8" 10 "Reserved7" 9 "Reserved6" 8 "Reserved5" 7 "Reserved4" 6 "Reserved3" 5 "Reserved2" 4 "Reserved1" 3 "BootloaderSelfCheckFail" 2 "ApplicationCrcfail" 1 "ApplicationNotPresent" 0 "NormalStartup" ;
VAL_ 1546 resetCause_BGW 255 "SNA" 250 "UnknownReason" 21 "ExrF31" 20 "HsmF29" 19 "SoftF28" 18 "NmiF27" 17 "StDoneF25" 16 "OscResetF24" 15 "FccuLongResetF23" 14 "FccuShortResetF22" 13 "Z4aDbgResetF21" 12 "Z4bDbgResetF20" 11 "Z2DbgResetF19" 10 "LvdResetF18" 9 "HvdResetF17" 8 "Pd2LvdResetF14" 7 "HsmResetD29" 6 "SoftwareD28" 5 "SscmResetD27" 4 "SufResetD25" 3 "Core0ResetD24" 2 "Core1ResetD23" 1 "Core2ResetD22" 0 "NormalWakeD31" ;
VAL_ 1554 bootloaderStuckSignal_FBCM 255 "SNA" 18 "EcuSpecificReason3" 17 "EcuSpecificReason2" 16 "EcuSpecificReason1" 15 "Reserved12" 14 "Reserved11" 13 "Reserved10" 12 "Reserved9" 11 "Reserved8" 10 "Reserved7" 9 "Reserved6" 8 "Reserved5" 7 "Reserved4" 6 "Reserved3" 5 "Reserved2" 4 "Reserved1" 3 "BootloaderSelfCheckFail" 2 "ApplicationCrcfail" 1 "ApplicationNotPresent" 0 "NormalStartup" ;
VAL_ 1554 resetCause_FBCM 255 "SNA" 18 "EcuSpecificReason3" 17 "EcuSpecificReason2" 16 "EcuSpecificReason1" 15 "Reserved10" 14 "Reserved9" 13 "Reserved8" 12 "Reserved7" 11 "Reserved6" 10 "Reserved5" 9 "Reserved4" 8 "Reserved3" 7 "Reserved2" 6 "Reserved1" 5 "SoftwareException" 4 "UdsResetRequest" 3 "PowerMonitor" 2 "WatchdogTimer" 1 "WakeSignal" 0 "NormalWakeCanOrRtc" ;
VAL_ 1047 lvlrequestlowbeam_FBCM 15 "SNA" 7 "SubtractThreeDeg" 6 "SubtractTwoDeg" 5 "SubtractOneDeg" 4 "ZeroDeg" 3 "AddOneDeg" 2 "AddTwoDeg" 1 "AddThreeDeg" 0 "Stop" ;
VAL_ 1047 lightPosLeftOnReq_FBCM 3 "SNA" 2 "LightFault" 1 "LightOn" 0 "LightOff" ;
VAL_ 1047 lightPosRightOnReq_FBCM 3 "SNA" 2 "LightFault" 1 "LightOn" 0 "LightOff" ;
VAL_ 1047 lightReverseOnReq_FBCM 3 "SNA" 1 "TurnLightOn" 0 "TurnLightOff" ;
VAL_ 1047 lightFogRearOnReq_FBCM 3 "SNA" 1 "TurnLightOn" 0 "TurnLightOff" ;
VAL_ 1602 bootloaderStuckSignal_HLL 255 "SNA" 18 "EcuSpecificReason3" 17 "EcuSpecificReason2" 16 "EcuSpecificReason1" 15 "Reserved12" 14 "Reserved11" 13 "Reserved10" 12 "Reserved9" 11 "Reserved8" 10 "Reserved7" 9 "Reserved6" 8 "Reserved5" 7 "Reserved4" 6 "Reserved3" 5 "Reserved2" 4 "Reserved1" 3 "BootloaderSelfCheckFail" 2 "ApplicationCrcfail" 1 "ApplicationNotPresent" 0 "NormalStartup" ;
VAL_ 1602 resetCause_HLL 255 "SNA" 18 "EcuSpecificReason3" 17 "EcuSpecificReason2" 16 "EcuSpecificReason1" 15 "Reserved10" 14 "Reserved9" 13 "Reserved8" 12 "Reserved7" 11 "Reserved6" 10 "Reserved5" 9 "Reserved4" 8 "Reserved3" 7 "Reserved2" 6 "Reserved1" 5 "SoftwareException" 4 "UdsResetRequest" 3 "PowerMonitor" 2 "WatchdogTimer" 1 "WakeSignal" 0 "NormalWakeCanOrRtc" ;
VAL_ 1610 bootloaderStuckSignal_HLR 255 "SNA" 18 "EcuSpecificReason3" 17 "EcuSpecificReason2" 16 "EcuSpecificReason1" 15 "Reserved12" 14 "Reserved11" 13 "Reserved10" 12 "Reserved9" 11 "Reserved8" 10 "Reserved7" 9 "Reserved6" 8 "Reserved5" 7 "Reserved4" 6 "Reserved3" 5 "Reserved2" 4 "Reserved1" 3 "BootloaderSelfCheckFail" 2 "ApplicationCrcfail" 1 "ApplicationNotPresent" 0 "NormalStartup" ;
VAL_ 1610 resetCause_HLR 255 "SNA" 18 "EcuSpecificReason3" 17 "EcuSpecificReason2" 16 "EcuSpecificReason1" 15 "Reserved10" 14 "Reserved9" 13 "Reserved8" 12 "Reserved7" 11 "Reserved6" 10 "Reserved5" 9 "Reserved4" 8 "Reserved3" 7 "Reserved2" 6 "Reserved1" 5 "SoftwareException" 4 "UdsResetRequest" 3 "PowerMonitor" 2 "WatchdogTimer" 1 "WakeSignal" 0 "NormalWakeCanOrRtc" ;
VAL_ 1634 bootloaderStuckSignal_DCFL 255 "SNA" 18 "EcuSpecificReason3" 17 "EcuSpecificReason2" 16 "EcuSpecificReason1" 15 "Reserved12" 14 "Reserved11" 13 "Reserved10" 12 "Reserved9" 11 "Reserved8" 10 "Reserved7" 9 "Reserved6" 8 "Reserved5" 7 "Reserved4" 6 "Reserved3" 5 "Reserved2" 4 "Reserved1" 3 "BootloaderSelfCheckFail" 2 "ApplicationCrcfail" 1 "ApplicationNotPresent" 0 "NormalStartup" ;
VAL_ 1634 resetCause_DCFL 255 "SNA" 18 "EcuSpecificReason3" 17 "EcuSpecificReason2" 16 "EcuSpecificReason1" 15 "Reserved10" 14 "Reserved9" 13 "Reserved8" 12 "Reserved7" 11 "Reserved6" 10 "Reserved5" 9 "Reserved4" 8 "Reserved3" 7 "Reserved2" 6 "Reserved1" 5 "SoftwareException" 4 "UdsResetRequest" 3 "PowerMonitor" 2 "WatchdogTimer" 1 "WakeSignal" 0 "NormalWakeCanOrRtc" ;
VAL_ 1650 resetCause_DSM 255 "SNA" 18 "EcuSpecificReason3" 17 "EcuSpecificReason2" 16 "EcuSpecificReason1" 15 "Reserved10" 14 "Reserved9" 13 "Reserved8" 12 "Reserved7" 11 "Reserved6" 10 "Reserved5" 9 "Reserved4" 8 "Reserved3" 7 "Reserved2" 6 "Reserved1" 5 "SoftwareException" 4 "UdsResetRequest" 3 "PowerMonitor" 2 "WatchdogTimer" 1 "WakeSignal" 0 "NormalWakeCanOrRtc" ;
VAL_ 1650 bootloaderStuckSignal_DSM 255 "SNA" 18 "EcuSpecificReason3" 17 "EcuSpecificReason2" 16 "EcuSpecificReason1" 15 "Reserved12" 14 "Reserved11" 13 "Reserved10" 12 "Reserved9" 11 "Reserved8" 10 "Reserved7" 9 "Reserved6" 8 "Reserved5" 7 "Reserved4" 6 "Reserved3" 5 "Reserved2" 4 "Reserved1" 3 "BootloaderSelfCheckFail" 2 "ApplicationCrcfail" 1 "ApplicationNotPresent" 0 "NormalStartup" ;
VAL_ 1674 bootloaderStuckSignal_DCFR 255 "SNA" 18 "EcuSpecificReason3" 17 "EcuSpecificReason2" 16 "EcuSpecificReason1" 15 "Reserved12" 14 "Reserved11" 13 "Reserved10" 12 "Reserved9" 11 "Reserved8" 10 "Reserved7" 9 "Reserved6" 8 "Reserved5" 7 "Reserved4" 6 "Reserved3" 5 "Reserved2" 4 "Reserved1" 3 "BootloaderSelfCheckFail" 2 "ApplicationCrcfail" 1 "ApplicationNotPresent" 0 "NormalStartup" ;
VAL_ 1674 resetCause_DCFR 255 "SNA" 18 "EcuSpecificReason3" 17 "EcuSpecificReason2" 16 "EcuSpecificReason1" 15 "Reserved10" 14 "Reserved9" 13 "Reserved8" 12 "Reserved7" 11 "Reserved6" 10 "Reserved5" 9 "Reserved4" 8 "Reserved3" 7 "Reserved2" 6 "Reserved1" 5 "SoftwareException" 4 "UdsResetRequest" 3 "PowerMonitor" 2 "WatchdogTimer" 1 "WakeSignal" 0 "NormalWakeCanOrRtc" ;
VAL_ 1682 resetCause_PSM 255 "SNA" 18 "EcuSpecificReason3" 17 "EcuSpecificReason2" 16 "EcuSpecificReason1" 15 "Reserved10" 14 "Reserved9" 13 "Reserved8" 12 "Reserved7" 11 "Reserved6" 10 "Reserved5" 9 "Reserved4" 8 "Reserved3" 7 "Reserved2" 6 "Reserved1" 5 "SoftwareException" 4 "UdsResetRequest" 3 "PowerMonitor" 2 "WatchdogTimer" 1 "WakeSignal" 0 "NormalWakeCanOrRtc" ;
VAL_ 1682 bootloaderStuckSignal_PSM 255 "SNA" 18 "EcuSpecificReason3" 17 "EcuSpecificReason2" 16 "EcuSpecificReason1" 15 "Reserved12" 14 "Reserved11" 13 "Reserved10" 12 "Reserved9" 11 "Reserved8" 10 "Reserved7" 9 "Reserved6" 8 "Reserved5" 7 "Reserved4" 6 "Reserved3" 5 "Reserved2" 4 "Reserved1" 3 "BootloaderSelfCheckFail" 2 "ApplicationCrcfail" 1 "ApplicationNotPresent" 0 "NormalStartup" ;
VAL_ 1706 bootloaderStuckSignal_DCRL 255 "SNA" 18 "EcuSpecificReason3" 17 "EcuSpecificReason2" 16 "EcuSpecificReason1" 15 "Reserved12" 14 "Reserved11" 13 "Reserved10" 12 "Reserved9" 11 "Reserved8" 10 "Reserved7" 9 "Reserved6" 8 "Reserved5" 7 "Reserved4" 6 "Reserved3" 5 "Reserved2" 4 "Reserved1" 3 "BootloaderSelfCheckFail" 2 "ApplicationCrcfail" 1 "ApplicationNotPresent" 0 "NormalStartup" ;
VAL_ 1706 resetCause_DCRL 255 "SNA" 18 "EcuSpecificReason3" 17 "EcuSpecificReason2" 16 "EcuSpecificReason1" 15 "Reserved10" 14 "Reserved9" 13 "Reserved8" 12 "Reserved7" 11 "Reserved6" 10 "Reserved5" 9 "Reserved4" 8 "Reserved3" 7 "Reserved2" 6 "Reserved1" 5 "SoftwareException" 4 "UdsResetRequest" 3 "PowerMonitor" 2 "WatchdogTimer" 1 "WakeSignal" 0 "NormalWakeCanOrRtc" ;
VAL_ 1714 resetCause_RLSM 255 "SNA" 18 "EcuSpecificReason3" 17 "EcuSpecificReason2" 16 "EcuSpecificReason1" 15 "Reserved10" 14 "Reserved9" 13 "Reserved8" 12 "Reserved7" 11 "Reserved6" 10 "Reserved5" 9 "Reserved4" 8 "Reserved3" 7 "Reserved2" 6 "Reserved1" 5 "SoftwareException" 4 "UdsResetRequest" 3 "PowerMonitor" 2 "WatchdogTimer" 1 "WakeSignal" 0 "NormalWakeCanOrRtc" ;
VAL_ 1714 bootloaderStuckSignal_RLSM 255 "SNA" 18 "EcuSpecificReason3" 17 "EcuSpecificReason2" 16 "EcuSpecificReason1" 15 "Reserved12" 14 "Reserved11" 13 "Reserved10" 12 "Reserved9" 11 "Reserved8" 10 "Reserved7" 9 "Reserved6" 8 "Reserved5" 7 "Reserved4" 6 "Reserved3" 5 "Reserved2" 4 "Reserved1" 3 "BootloaderSelfCheckFail" 2 "ApplicationCrcfail" 1 "ApplicationNotPresent" 0 "NormalStartup" ;
VAL_ 1738 bootloaderStuckSignal_DCRR 255 "SNA" 18 "EcuSpecificReason3" 17 "EcuSpecificReason2" 16 "EcuSpecificReason1" 15 "Reserved12" 14 "Reserved11" 13 "Reserved10" 12 "Reserved9" 11 "Reserved8" 10 "Reserved7" 9 "Reserved6" 8 "Reserved5" 7 "Reserved4" 6 "Reserved3" 5 "Reserved2" 4 "Reserved1" 3 "BootloaderSelfCheckFail" 2 "ApplicationCrcfail" 1 "ApplicationNotPresent" 0 "NormalStartup" ;
VAL_ 1738 resetCause_DCRR 255 "SNA" 18 "EcuSpecificReason3" 17 "EcuSpecificReason2" 16 "EcuSpecificReason1" 15 "Reserved10" 14 "Reserved9" 13 "Reserved8" 12 "Reserved7" 11 "Reserved6" 10 "Reserved5" 9 "Reserved4" 8 "Reserved3" 7 "Reserved2" 6 "Reserved1" 5 "SoftwareException" 4 "UdsResetRequest" 3 "PowerMonitor" 2 "WatchdogTimer" 1 "WakeSignal" 0 "NormalWakeCanOrRtc" ;
VAL_ 1746 resetCause_RRSM 255 "SNA" 18 "EcuSpecificReason3" 17 "EcuSpecificReason2" 16 "EcuSpecificReason1" 15 "Reserved10" 14 "Reserved9" 13 "Reserved8" 12 "Reserved7" 11 "Reserved6" 10 "Reserved5" 9 "Reserved4" 8 "Reserved3" 7 "Reserved2" 6 "Reserved1" 5 "SoftwareException" 4 "UdsResetRequest" 3 "PowerMonitor" 2 "WatchdogTimer" 1 "WakeSignal" 0 "NormalWakeCanOrRtc" ;
VAL_ 1746 bootloaderStuckSignal_RRSM 255 "SNA" 18 "EcuSpecificReason3" 17 "EcuSpecificReason2" 16 "EcuSpecificReason1" 15 "Reserved12" 14 "Reserved11" 13 "Reserved10" 12 "Reserved9" 11 "Reserved8" 10 "Reserved7" 9 "Reserved6" 8 "Reserved5" 7 "Reserved4" 6 "Reserved3" 5 "Reserved2" 4 "Reserved1" 3 "BootloaderSelfCheckFail" 2 "ApplicationCrcfail" 1 "ApplicationNotPresent" 0 "NormalStartup" ;
VAL_ 1826 bootloaderStuckSignal_ECPM 255 "SNA" 18 "EcuSpecificReason3" 17 "EcuSpecificReason2" 16 "EcuSpecificReason1" 15 "Reserved12" 14 "Reserved11" 13 "Reserved10" 12 "Reserved9" 11 "Reserved8" 10 "Reserved7" 9 "Reserved6" 8 "Reserved5" 7 "Reserved4" 6 "Reserved3" 5 "Reserved2" 4 "Reserved1" 3 "BootloaderSelfCheckFail" 2 "ApplicationCrcfail" 1 "ApplicationNotPresent" 0 "NormalStartup" ;
VAL_ 1826 resetCause_ECPM 255 "SNA" 18 "EcuSpecificReason3" 17 "EcuSpecificReason2" 16 "EcuSpecificReason1" 15 "Reserved10" 14 "Reserved9" 13 "Reserved8" 12 "Reserved7" 11 "Reserved6" 10 "Reserved5" 9 "Reserved4" 8 "Reserved3" 7 "Reserved2" 6 "Reserved1" 5 "SoftwareException" 4 "UdsResetRequest" 3 "PowerMonitor" 2 "WatchdogTimer" 1 "WakeSignal" 0 "NormalWakeCanOrRtc" ;
VAL_ 1842 bootloaderStuckSignal_DBPC 255 "SNA" 18 "EcuSpecificReason3" 17 "EcuSpecificReason2" 16 "EcuSpecificReason1" 15 "Reserved12" 14 "Reserved11" 13 "Reserved10" 12 "Reserved9" 11 "Reserved8" 10 "Reserved7" 9 "Reserved6" 8 "Reserved5" 7 "Reserved4" 6 "Reserved3" 5 "Reserved2" 4 "Reserved1" 3 "BootloaderSelfCheckFail" 2 "ApplicationCrcfail" 1 "ApplicationNotPresent" 0 "NormalStartup" ;
VAL_ 1842 resetCause_DBPC 255 "SNA" 18 "EcuSpecificReason3" 17 "EcuSpecificReason2" 16 "EcuSpecificReason1" 15 "Reserved10" 14 "Reserved9" 13 "Reserved8" 12 "Reserved7" 11 "Reserved6" 10 "Reserved5" 9 "Reserved4" 8 "Reserved3" 7 "Reserved2" 6 "Reserved1" 5 "SoftwareException" 4 "UdsResetRequest" 3 "PowerMonitor" 2 "WatchdogTimer" 1 "WakeSignal" 0 "NormalWakeCanOrRtc" ;
VAL_ 1858 bootloaderStuckSignal_FFL 255 "SNA" 18 "EcuSpecificReason3" 17 "EcuSpecificReason2" 16 "EcuSpecificReason1" 15 "Reserved12" 14 "Reserved11" 13 "Reserved10" 12 "Reserved9" 11 "Reserved8" 10 "Reserved7" 9 "Reserved6" 8 "Reserved5" 7 "Reserved4" 6 "Reserved3" 5 "Reserved2" 4 "Reserved1" 3 "BootloaderSelfCheckFail" 2 "ApplicationCrcfail" 1 "ApplicationNotPresent" 0 "NormalStartup" ;
VAL_ 1858 resetCause_FFL 255 "SNA" 18 "EcuSpecificReason3" 17 "EcuSpecificReason2" 16 "EcuSpecificReason1" 15 "Reserved10" 14 "Reserved9" 13 "Reserved8" 12 "Reserved7" 11 "Reserved6" 10 "Reserved5" 9 "Reserved4" 8 "Reserved3" 7 "Reserved2" 6 "Reserved1" 5 "SoftwareException" 4 "UdsResetRequest" 3 "PowerMonitor" 2 "WatchdogTimer" 1 "WakeSignal" 0 "NormalWakeCanOrRtc" ;
VAL_ 1866 bootloaderStuckSignal_FLDC 255 "SNA" 18 "EcuSpecificReason3" 17 "EcuSpecificReason2" 16 "EcuSpecificReason1" 15 "Reserved12" 14 "Reserved11" 13 "Reserved10" 12 "Reserved9" 11 "Reserved8" 10 "Reserved7" 9 "Reserved6" 8 "Reserved5" 7 "Reserved4" 6 "Reserved3" 5 "Reserved2" 4 "Reserved1" 3 "BootloaderSelfCheckFail" 2 "ApplicationCrcfail" 1 "ApplicationNotPresent" 0 "NormalStartup" ;
VAL_ 1866 resetCause_FLDC 255 "SNA" 18 "EcuSpecificReason3" 17 "EcuSpecificReason2" 16 "EcuSpecificReason1" 15 "Reserved10" 14 "Reserved9" 13 "Reserved8" 12 "Reserved7" 11 "Reserved6" 10 "Reserved5" 9 "Reserved4" 8 "Reserved3" 7 "Reserved2" 6 "Reserved1" 5 "SoftwareException" 4 "UdsResetRequest" 3 "PowerMonitor" 2 "WatchdogTimer" 1 "WakeSignal" 0 "NormalWakeCanOrRtc" ;
VAL_ 1874 bootloaderStuckSignal_FRDC 255 "SNA" 18 "EcuSpecificReason3" 17 "EcuSpecificReason2" 16 "EcuSpecificReason1" 15 "Reserved12" 14 "Reserved11" 13 "Reserved10" 12 "Reserved9" 11 "Reserved8" 10 "Reserved7" 9 "Reserved6" 8 "Reserved5" 7 "Reserved4" 6 "Reserved3" 5 "Reserved2" 4 "Reserved1" 3 "BootloaderSelfCheckFail" 2 "ApplicationCrcfail" 1 "ApplicationNotPresent" 0 "NormalStartup" ;
VAL_ 1874 resetCause_FRDC 255 "SNA" 18 "EcuSpecificReason3" 17 "EcuSpecificReason2" 16 "EcuSpecificReason1" 15 "Reserved10" 14 "Reserved9" 13 "Reserved8" 12 "Reserved7" 11 "Reserved6" 10 "Reserved5" 9 "Reserved4" 8 "Reserved3" 7 "Reserved2" 6 "Reserved1" 5 "SoftwareException" 4 "UdsResetRequest" 3 "PowerMonitor" 2 "WatchdogTimer" 1 "WakeSignal" 0 "NormalWakeCanOrRtc" ;
VAL_ 1882 bootloaderStuckSignal_RLDC 255 "SNA" 18 "EcuSpecificReason3" 17 "EcuSpecificReason2" 16 "EcuSpecificReason1" 15 "Reserved12" 14 "Reserved11" 13 "Reserved10" 12 "Reserved9" 11 "Reserved8" 10 "Reserved7" 9 "Reserved6" 8 "Reserved5" 7 "Reserved4" 6 "Reserved3" 5 "Reserved2" 4 "Reserved1" 3 "BootloaderSelfCheckFail" 2 "ApplicationCrcfail" 1 "ApplicationNotPresent" 0 "NormalStartup" ;
VAL_ 1882 resetCause_RLDC 255 "SNA" 18 "EcuSpecificReason3" 17 "EcuSpecificReason2" 16 "EcuSpecificReason1" 15 "Reserved10" 14 "Reserved9" 13 "Reserved8" 12 "Reserved7" 11 "Reserved6" 10 "Reserved5" 9 "Reserved4" 8 "Reserved3" 7 "Reserved2" 6 "Reserved1" 5 "SoftwareException" 4 "UdsResetRequest" 3 "PowerMonitor" 2 "WatchdogTimer" 1 "WakeSignal" 0 "NormalWakeCanOrRtc" ;
VAL_ 1890 bootloaderStuckSignal_RRDC 255 "SNA" 18 "EcuSpecificReason3" 17 "EcuSpecificReason2" 16 "EcuSpecificReason1" 15 "Reserved12" 14 "Reserved11" 13 "Reserved10" 12 "Reserved9" 11 "Reserved8" 10 "Reserved7" 9 "Reserved6" 8 "Reserved5" 7 "Reserved4" 6 "Reserved3" 5 "Reserved2" 4 "Reserved1" 3 "BootloaderSelfCheckFail" 2 "ApplicationCrcfail" 1 "ApplicationNotPresent" 0 "NormalStartup" ;
VAL_ 1890 resetCause_RRDC 255 "SNA" 18 "EcuSpecificReason3" 17 "EcuSpecificReason2" 16 "EcuSpecificReason1" 15 "Reserved10" 14 "Reserved9" 13 "Reserved8" 12 "Reserved7" 11 "Reserved6" 10 "Reserved5" 9 "Reserved4" 8 "Reserved3" 7 "Reserved2" 6 "Reserved1" 5 "SoftwareException" 4 "UdsResetRequest" 3 "PowerMonitor" 2 "WatchdogTimer" 1 "WakeSignal" 0 "NormalWakeCanOrRtc" ;
